[part 1 of 5: packages /MICROSAR/Dem_swc/DataTypes to /MICROSAR/Dem_swc/ComponentTypes]
AUTOSAR XML (schema 00048)
package /MICROSAR/Dem_swc/DataTypes
  27 x impl type:
    Dem_EventIdType: range raw 1..65535, implementation-data-type=uint16
    Dem_RatioIdType: range raw 1..65535, implementation-data-type=uint16
    Dem_DTCStatusMaskType: range raw 0..255, implementation-data-type=uint8
    Dem_OperationCycleIdType: range raw 0..255, implementation-data-type=uint8
    Dem_DTCGroupType: range raw 0..16777215, implementation-data-type=uint32
    Dem_EventStatusType:
      compu {0=DEM_EVENT_STATUS_PASSED, 1=DEM_EVENT_STATUS_FAILED, 2=DEM_EVENT_STATUS_PREPASSED, 3=DEM_EVENT_STATUS_PREFAILED, 4=DEM_EVENT_STATUS_FDC_THRESHOLD_REACHED, 5=DEM_EVENT_STATUS_PASSED_CONDITIONS_NOT_FULFILLED, 6=DEM_EVENT_STATUS_FAILED_CONDITIONS_NOT_FULFILLED, 7=DEM_EVENT_STATUS_PREPASSED_CONDITIONS_NOT_FULFILLED, 8=DEM_EVENT_STATUS_PREFAILED_CONDITIONS_NOT_FULFILLED}
      range raw 0..255
      implementation-data-type=uint8
    Dem_DTCKindType: compu {1=DEM_DTC_KIND_ALL_DTCS, 2=DEM_DTC_KIND_EMISSION_REL_DTCS}, range raw 0..255, implementation-data-type=uint8
    Dem_IumprDenomCondStatusType: compu {0=DEM_IUMPR_DEN_STATUS_NOT_REACHED, 1=DEM_IUMPR_DEN_STATUS_REACHED, 2=DEM_IUMPR_DEN_STATUS_INHIBITED}, range raw 0..255, implementation-data-type=uint8
    Dem_DebounceResetStatusType: compu {0=DEM_DEBOUNCE_STATUS_FREEZE, 1=DEM_DEBOUNCE_STATUS_RESET}, range raw 0..255, implementation-data-type=uint8
    Dem_DTRControlType: compu {0=DEM_DTR_CTL_NORMAL, 1=DEM_DTR_CTL_NO_MAX, 2=DEM_DTR_CTL_NO_MIN, 3=DEM_DTR_CTL_RESET, 4=DEM_DTR_CTL_INVISIBLE}, range raw 0..255, implementation-data-type=uint8
    Dem_DebouncingStateType:
      compu {mask 1: 1=DEM_TEMPORARILY_DEFECTIVE (Bit 0: Temporarily Defective (corresponds to 0 < FDC < 127)), mask 2: 2=DEM_FINALLY_DEFECTIVE (Bit 1: Finally Defective (corresponds to FDC = 127)), mask 4: 4=DEM_TEMPORARILY_HEALED (Bit 2: Temporarily healed (corresponds to -128 < FDC < 0)), mask 8: 8=DEM_TEST_COMPLETE (Bit 3: Test complete (corresponds to FDC = -128 or FDC = 127)), mask 16: 16=DEM_DTR_UPDATE (Bit 4: DTR Update (= Test complete && Debouncing complete && enable conditions / storage conditions fulfilled))}
      range raw 0..255
      implementation-data-type=uint8
    Dem_DTCSeverityType:
      compu {mask 255: 0=DEM_SEVERITY_NO_SEVERITY (DTC_NO_SEVERITY) (No severity information available), mask 31: 1=DEM_SEVERITY_WWHOBD_CLASS_NO_CLASS (DTC_CLASS) (No class information), mask 31: 2=DEM_SEVERITY_WWHOBD_CLASS_A (DTC_CLASS) (WWH-OBD Class A), mask 31: 4=DEM_SEVERITY_WWHOBD_CLASS_B1 (DTC_CLASS) (WWH-OBD Class B1), mask 31: 8=DEM_SEVERITY_WWHOBD_CLASS_B2 (DTC_CLASS) (WWH-OBD Class B2), mask 31: 16=DEM_SEVERITY_WWHOBD_CLASS_C (DTC_CLASS) (WWH-OBD Class C), mask 224: 32=DEM_SEVERITY_MAINTENANCE_ONLY (DTC_SEVERITY) (Maintenance required), mask 224: 64=DEM_SEVERITY_CHECK_AT_NEXT_HALT (DTC_SEVERITY) (Check at next halt), mask 224: 128=DEM_SEVERITY_CHECK_IMMEDIATELY (DTC_SEVERITY) (Check immediately)}
      range raw 0..255
      implementation-data-type=uint8
    Dem_UdsStatusByteType:
      compu {mask 1: 1=DEM_UDS_STATUS_TF (bit 0: TestFailed), mask 2: 2=DEM_UDS_STATUS_TFTOC (bit 1: TestFailedThisOperationCycle), mask 4: 4=DEM_UDS_STATUS_PDTC (bit 2: PendingDTC), mask 8: 8=DEM_UDS_STATUS_CDTC (bit 3: ConfirmedDTC), mask 16: 16=DEM_UDS_STATUS_TNCSLC (bit 4: TestNotCompletedSinceLastClear), mask 32: 32=DEM_UDS_STATUS_TFSLC (bit 5: TestFailedSinceLastClear), mask 64: 64=DEM_UDS_STATUS_TNCTOC (bit 6: TestNotCompletedThisOperationCycle), mask 128: 128=DEM_UDS_STATUS_WIR (bit 7: WarningIndicatorRequested)}
      range raw 0..255
      implementation-data-type=uint8
    Dem_MonitorStatusType: compu {mask 1: 1=DEM_MONITOR_STATUS_TF (bit 0: TestFailed), mask 2: 2=DEM_MONITOR_STATUS_TNCTOC (bit 1: TestNotCompletedThisOperationCycle)}, range raw 0..255, implementation-data-type=uint8
    DataArrayType_uint8_2: category=ARRAY, sw-calibration-access=READ-ONLY
      element DataArrayType_uint8_2Element: array-size=2, array-size-semantics=FIXED-SIZE, implementation-data-type=uint8
    Dem_IumprReadinessGroupType:
      compu {0=DEM_IUMPR_BOOSTPRS, 1=DEM_IUMPR_CAT1, 2=DEM_IUMPR_CAT2, 3=DEM_IUMPR_EGR, 4=DEM_IUMPR_EGSENSOR, 5=DEM_IUMPR_EVAP, 6=DEM_IUMPR_NMHCCAT, 7=DEM_IUMPR_NOXADSORB, 8=DEM_IUMPR_NOXCAT, 9=DEM_IUMPR_OXS1, 10=DEM_IUMPR_OXS2, 11=DEM_IUMPR_PMFILTER, 12=DEM_IUMPR_PRIVATE, 13=DEM_IUMPR_SAIR, 14=DEM_IUMPR_SECOXS1, 15=DEM_IUMPR_SECOXS2, 16=DEM_IUMPR_FLSYS, 17=DEM_IUMPR_AFRI1, 18=DEM_IUMPR_AFRI2, 19=DEM_IUMPR_PF1, 20=DEM_IUMPR_PF2, 255=DEM_IUMPR_ALLGROUPS}
      range raw 0..255
      implementation-data-type=uint8
    Dem_IumprDenomCondIdType: compu {1=DEM_IUMPR_GENERAL_DENOMINATOR, 2=DEM_IUMPR_DEN_COND_COLDSTART, 3=DEM_IUMPR_DEN_COND_EVAP, 4=DEM_IUMPR_DEN_COND_500MI, 5=DEM_IUMPR_GENERAL_INDIVIDUAL_DENOMINATOR, 6=DEM_IUMPR_GENERAL_OBDCOND, 7=DEM_IUMPR_DEN_COND_INDEPENDENT}, range raw 0..255, implementation-data-type=uint8
    Dem_InitMonitorReasonType: compu {1=DEM_INIT_MONITOR_CLEAR, 2=DEM_INIT_MONITOR_RESTART, 3=DEM_INIT_MONITOR_REENABLED, 4=DEM_INIT_MONITOR_STORAGE_REENABLED}, range raw 1..4, implementation-data-type=uint8
    Dem_DTCFormatType: compu {0=DEM_DTC_FORMAT_OBD, 1=DEM_DTC_FORMAT_UDS, 2=DEM_DTC_FORMAT_J1939}, range raw 0..2, implementation-data-type=uint8
    Dem_OperationCycleStateType: compu {0=DEM_CYCLE_STATE_START, 1=DEM_CYCLE_STATE_END}, range raw 0..1, implementation-data-type=uint8
    Dem_IndicatorStatusType: compu {0=DEM_INDICATOR_OFF, 1=DEM_INDICATOR_CONTINUOUS, 2=DEM_INDICATOR_BLINKING, 3=DEM_INDICATOR_BLINK_CONT, 4=DEM_INDICATOR_SLOW_FLASH, 5=DEM_INDICATOR_FAST_FLASH, 6=DEM_INDICATOR_ON_DEMAND, 7=DEM_INDICATOR_SHORT}, range raw 0..7, implementation-data-type=uint8
    Dem_DTCOriginType: compu {1=DEM_DTC_ORIGIN_PRIMARY_MEMORY, 2=DEM_DTC_ORIGIN_MIRROR_MEMORY, 3=DEM_DTC_ORIGIN_PERMANENT_MEMORY, 4=DEM_DTC_ORIGIN_OBD_RELEVANT_MEMORY, 256=DEM_DTC_ORIGIN_SECONDARY_MEMORY}, range raw 1..511, implementation-data-type=uint16
    Dem_MaxDataValueType: category=ARRAY, sw-calibration-access=READ-ONLY
      element Dem_MaxDataValueTypeElement: array-size=10, array-size-semantics=FIXED-SIZE, implementation-data-type=uint8
    DataPrimitiveType_uint8: implementation-data-type=uint8
    DataArrayType_uint8_3: category=ARRAY, sw-calibration-access=READ-ONLY
      element DataArrayType_uint8_3Element: array-size=3, array-size-semantics=FIXED-SIZE, implementation-data-type=uint8
    DataArrayType_uint8_1: category=ARRAY, sw-calibration-access=READ-ONLY
      element DataArrayType_uint8_1Element: array-size=1, array-size-semantics=FIXED-SIZE, implementation-data-type=uint8
    DataArrayType_uint8_5: category=ARRAY, sw-calibration-access=READ-ONLY
      element DataArrayType_uint8_5Element: array-size=5, array-size-semantics=FIXED-SIZE, implementation-data-type=uint8
package /MICROSAR/Dem_swc/Interfaces
  37 x client server interface, all with is-service=true, service-kind=DIAGNOSTIC-EVENT-MANAGER:
    DemServices
      operation GetPostRunRequested: possible-error=DemServices/E_NOT_OK
        arg IsRequested: type=boolean, direction=OUT
      operation GetDTCStatusAvailabilityMask: possible-error=DemServices/E_NOT_OK
        arg ClientId: type=uint8, direction=IN
        arg DTCStatusMask: type=uint8, direction=OUT
      error E_NOT_OK: error-code=1
    ClearDTC
      operation ClearDTC: possible-error=[ClearDTC/E_NOT_OK, DEM_CLEAR_FAILED, ClearDTC/DEM_PENDING, DEM_CLEAR_BUSY, DEM_CLEAR_MEMORY_ERROR, ClearDTC/DEM_WRONG_DTC, ClearDTC/DEM_WRONG_DTCORIGIN]
      operation SelectDTC: possible-error=[ClearDTC/E_OK, ClearDTC/E_NOT_OK]
        arg DTC: type=uint32, direction=IN
        arg DTCFormat: type=Dem_DTCFormatType, direction=IN
        arg DTCOrigin: type=Dem_DTCOriginType, direction=IN
      8 x error:
        E_OK: error-code=0
        E_NOT_OK: error-code=1
        DEM_CLEAR_FAILED: error-code=7
        DEM_PENDING: error-code=4
        DEM_CLEAR_BUSY: error-code=5
        DEM_CLEAR_MEMORY_ERROR: error-code=6
        DEM_WRONG_DTC: error-code=8
        DEM_WRONG_DTCORIGIN: error-code=9
    EvMemOverflowIndication
      operation GetEventMemoryOverflow: possible-error=EvMemOverflowIndication/E_NOT_OK
        arg OverflowIndication: type=boolean, direction=OUT
      operation GetNumberOfEventMemoryEntries: possible-error=EvMemOverflowIndication/E_NOT_OK
        arg NumberOfEventMemoryEntries: type=uint8, direction=OUT
      error E_NOT_OK: error-code=1
    GeneralDiagnosticInfo
      11 x operation:
        GetEventUdsStatus: possible-error=GeneralDiagnosticInfo/E_NOT_OK
          arg EventId: type=Dem_EventIdType, direction=IN
          arg UDSStatusByte: type=Dem_UdsStatusByteType, direction=OUT
        GetEventStatus: possible-error=GeneralDiagnosticInfo/E_NOT_OK
          arg EventId: type=Dem_EventIdType, direction=IN
          arg UDSStatusByte: type=Dem_UdsStatusByteType, direction=OUT
        GetEventFailed: possible-error=GeneralDiagnosticInfo/E_NOT_OK
          arg EventId: type=Dem_EventIdType, direction=IN
          arg EventFailed: type=boolean, direction=OUT
        GetEventTested: possible-error=GeneralDiagnosticInfo/E_NOT_OK
          arg EventId: type=Dem_EventIdType, direction=IN
          arg EventTested: type=boolean, direction=OUT
        GetDTCOfEvent: possible-error=[GeneralDiagnosticInfo/E_NOT_OK, GeneralDiagnosticInfo/DEM_E_NO_DTC_AVAILABLE]
          arg EventId: type=Dem_EventIdType, direction=IN
          arg DTCFormat: type=Dem_DTCFormatType, direction=IN
          arg DTCOfEvent: type=uint32, direction=OUT
        GetFaultDetectionCounter: possible-error=[GeneralDiagnosticInfo/E_NOT_OK, GeneralDiagnosticInfo/DEM_E_NO_FDC_AVAILABLE]
          arg EventId: type=Dem_EventIdType, direction=IN
          arg FaultDetectionCounter: type=sint8, direction=OUT
        GetEventFreezeFrameDataEx: possible-error=[GeneralDiagnosticInfo/E_NOT_OK, GeneralDiagnosticInfo/DEM_BUFFER_TOO_SMALL, GeneralDiagnosticInfo/DEM_NO_SUCH_ELEMENT]
          5 x arg:
            EventId: type=Dem_EventIdType, direction=IN
            RecordNumber: type=uint8, direction=IN
            DataId: type=uint16, direction=IN
            DestBuffer: type=Dem_MaxDataValueType, direction=OUT
            BufSize: type=uint16, direction=INOUT
        GetEventExtendedDataRecordEx: possible-error=[GeneralDiagnosticInfo/E_NOT_OK, GeneralDiagnosticInfo/DEM_BUFFER_TOO_SMALL, GeneralDiagnosticInfo/DEM_NO_SUCH_ELEMENT]
          4 x arg:
            EventId: type=Dem_EventIdType, direction=IN
            RecordNumber: type=uint8, direction=IN
            DestBuffer: type=Dem_MaxDataValueType, direction=OUT
            BufSize: type=uint16, direction=INOUT
        GetEventEnableCondition: possible-error=GeneralDiagnosticInfo/E_NOT_OK
          arg EventId: type=Dem_EventIdType, direction=IN
          arg ConditionFullfilled: type=boolean, direction=OUT
        GetDebouncingOfEvent: possible-error=GeneralDiagnosticInfo/E_NOT_OK
          arg EventId: type=Dem_EventIdType, direction=IN
          arg DebouncingState: type=Dem_DebouncingStateType, direction=OUT
        GetMonitorStatus: possible-error=GeneralDiagnosticInfo/E_NOT_OK
          arg EventId: type=Dem_EventIdType, direction=IN
          arg MonitorStatus: type=Dem_MonitorStatusType, direction=OUT
      5 x error:
        E_NOT_OK: error-code=1
        DEM_E_NO_DTC_AVAILABLE: error-code=10
        DEM_E_NO_FDC_AVAILABLE: error-code=14
        DEM_BUFFER_TOO_SMALL: error-code=21
        DEM_NO_SUCH_ELEMENT: error-code=48
    OperationCycle
      operation GetOperationCycleState: possible-error=[OperationCycle/E_OK, OperationCycle/E_NOT_OK]
        arg CycleState: type=Dem_OperationCycleStateType, direction=OUT
      operation SetOperationCycleState: possible-error=[OperationCycle/E_OK, OperationCycle/E_NOT_OK]
        arg CycleState: type=Dem_OperationCycleStateType, direction=IN
      error E_OK: error-code=0
      error E_NOT_OK: error-code=1
    DiagnosticInfo
      11 x operation:
        GetEventUdsStatus: possible-error=DiagnosticInfo/E_NOT_OK
          arg UDSStatusByte: type=Dem_UdsStatusByteType, direction=OUT
        GetEventStatus: possible-error=DiagnosticInfo/E_NOT_OK
          arg UDSStatusByte: type=Dem_UdsStatusByteType, direction=OUT
        GetEventFailed: possible-error=DiagnosticInfo/E_NOT_OK
          arg EventFailed: type=boolean, direction=OUT
        GetEventTested: possible-error=DiagnosticInfo/E_NOT_OK
          arg EventTested: type=boolean, direction=OUT
        GetDTCOfEvent: possible-error=[DiagnosticInfo/E_NOT_OK, DiagnosticInfo/DEM_E_NO_DTC_AVAILABLE]
          arg DTCFormat: type=Dem_DTCFormatType, direction=IN
          arg DTCOfEvent: type=uint32, direction=OUT
        GetFaultDetectionCounter: possible-error=[DiagnosticInfo/E_NOT_OK, DiagnosticInfo/DEM_E_NO_FDC_AVAILABLE]
          arg FaultDetectionCounter: type=sint8, direction=OUT
        GetEventFreezeFrameDataEx: possible-error=[DiagnosticInfo/E_NOT_OK, DiagnosticInfo/DEM_BUFFER_TOO_SMALL, DiagnosticInfo/DEM_NO_SUCH_ELEMENT]
          4 x arg:
            RecordNumber: type=uint8, direction=IN
            DataId: type=uint16, direction=IN
            DestBuffer: type=Dem_MaxDataValueType, direction=OUT
            BufSize: type=uint16, direction=INOUT
        GetEventExtendedDataRecordEx: possible-error=[DiagnosticInfo/E_NOT_OK, DiagnosticInfo/DEM_BUFFER_TOO_SMALL, DiagnosticInfo/DEM_NO_SUCH_ELEMENT]
          arg RecordNumber: type=uint8, direction=IN
          arg DestBuffer: type=Dem_MaxDataValueType, direction=OUT
          arg BufSize: type=uint16, direction=INOUT
        GetEventEnableCondition: possible-error=DiagnosticInfo/E_NOT_OK
          arg ConditionFullfilled: type=boolean, direction=OUT
        GetDebouncingOfEvent: possible-error=DiagnosticInfo/E_NOT_OK
          arg DebouncingState: type=Dem_DebouncingStateType, direction=OUT
        GetMonitorStatus: possible-error=DiagnosticInfo/E_NOT_OK
          arg MonitorStatus: type=Dem_MonitorStatusType, direction=OUT
      5 x error:
        E_NOT_OK: error-code=1
        DEM_E_NO_DTC_AVAILABLE: error-code=10
        DEM_E_NO_FDC_AVAILABLE: error-code=14
        DEM_BUFFER_TOO_SMALL: error-code=21
        DEM_NO_SUCH_ELEMENT: error-code=48
    DiagnosticMonitor
      11 x operation:
        SetEventStatus: possible-error=DiagnosticMonitor/E_NOT_OK
          arg EventStatus: type=Dem_EventStatusType, direction=IN
        ResetEventStatus: possible-error=DiagnosticMonitor/E_NOT_OK
        ResetEventDebounceStatus: possible-error=DiagnosticMonitor/E_NOT_OK
          arg DebounceResetStatus: type=Dem_DebounceResetStatusType, direction=IN
        GetEventUdsStatus: possible-error=DiagnosticMonitor/E_NOT_OK
          arg UDSStatusByte: type=Dem_UdsStatusByteType, direction=OUT
        GetEventStatus: possible-error=DiagnosticMonitor/E_NOT_OK
          arg UDSStatusByte: type=Dem_UdsStatusByteType, direction=OUT
        GetEventFailed: possible-error=DiagnosticMonitor/E_NOT_OK
          arg EventFailed: type=boolean, direction=OUT
        GetEventTested: possible-error=DiagnosticMonitor/E_NOT_OK
          arg EventTested: type=boolean, direction=OUT
        GetDTCOfEvent: possible-error=[DiagnosticMonitor/E_NOT_OK, DiagnosticMonitor/DEM_E_NO_DTC_AVAILABLE]
          arg DTCFormat: type=Dem_DTCFormatType, direction=IN
          arg DTCOfEvent: type=uint32, direction=OUT
        GetFaultDetectionCounter: possible-error=[DiagnosticMonitor/E_NOT_OK, DiagnosticMonitor/DEM_E_NO_FDC_AVAILABLE]
          arg FaultDetectionCounter: type=sint8, direction=OUT
        GetEventFreezeFrameDataEx: possible-error=[DiagnosticMonitor/E_NOT_OK, DiagnosticMonitor/DEM_BUFFER_TOO_SMALL, DiagnosticMonitor/DEM_NO_SUCH_ELEMENT]
          4 x arg:
            RecordNumber: type=uint8, direction=IN
            DataId: type=uint16, direction=IN
            DestBuffer: type=Dem_MaxDataValueType, direction=OUT
            BufSize: type=uint16, direction=INOUT
        GetEventExtendedDataRecordEx: possible-error=[DiagnosticMonitor/E_NOT_OK, DiagnosticMonitor/DEM_BUFFER_TOO_SMALL, DiagnosticMonitor/DEM_NO_SUCH_ELEMENT]
          arg RecordNumber: type=uint8, direction=IN
          arg DestBuffer: type=Dem_MaxDataValueType, direction=OUT
          arg BufSize: type=uint16, direction=INOUT
      5 x error:
        E_NOT_OK: error-code=1
        DEM_E_NO_DTC_AVAILABLE: error-code=10
        DEM_E_NO_FDC_AVAILABLE: error-code=14
        DEM_BUFFER_TOO_SMALL: error-code=21
        DEM_NO_SUCH_ELEMENT: error-code=48
    CSDataServices_DemDataElementClass_StartApplication
      operation ReadData: possible-error=CSDataServices_DemDataElementClass_StartApplication/E_NOT_OK
        arg Data: type=DataArrayType_uint8_2, direction=OUT
      error E_NOT_OK: error-code=1
    CallbackGetFaultDetectCounter
      operation GetFaultDetectionCounter: possible-error=CallbackGetFaultDetectCounter/E_NOT_OK
        arg FaultDetectionCounter: type=sint8, direction=OUT
      error E_NOT_OK: error-code=1
    CSDataServices_DID_0xF404_Calculate_Load_Value
      operation ReadData: possible-error=CSDataServices_DID_0xF404_Calculate_Load_Value/E_NOT_OK
        arg Data: type=DataPrimitiveType_uint8, direction=OUT
      error E_NOT_OK: error-code=1
    CSDataServices_DID_0xF405_Engine_Coolent_temperature
      operation ReadData: possible-error=CSDataServices_DID_0xF405_Engine_Coolent_temperature/E_NOT_OK
        arg Data: type=DataPrimitiveType_uint8, direction=OUT
      error E_NOT_OK: error-code=1
    CSDataServices_DID_0xF40C_Engine_RPM
      operation ReadData: possible-error=CSDataServices_DID_0xF40C_Engine_RPM/E_NOT_OK
        arg Data: type=DataPrimitiveType_uint8, direction=OUT
      error E_NOT_OK: error-code=1
    CSDataServices_DID_0xF41F_Time_Since_Engin_Start
      operation ReadData: possible-error=CSDataServices_DID_0xF41F_Time_Since_Engin_Start/E_NOT_OK
        arg Data: type=DataPrimitiveType_uint8, direction=OUT
      error E_NOT_OK: error-code=1
    CSDataServices_DID_0xF40D_Vehicle_Speed_Sensor
      operation ReadData: possible-error=CSDataServices_DID_0xF40D_Vehicle_Speed_Sensor/E_NOT_OK
        arg Data: type=DataPrimitiveType_uint8, direction=OUT
      error E_NOT_OK: error-code=1
    CSDataServices_DID_0xF442_Controle_Module_Voltage
      operation ReadData: possible-error=CSDataServices_DID_0xF442_Controle_Module_Voltage/E_NOT_OK
        arg Data: type=DataPrimitiveType_uint8, direction=OUT
      error E_NOT_OK: error-code=1
    CSDataServices_DID_0xF449_Accelerator_Pedal_Position_D
      operation ReadData: possible-error=CSDataServices_DID_0xF449_Accelerator_Pedal_Position_D/E_NOT_OK
        arg Data: type=DataPrimitiveType_uint8, direction=OUT
      error E_NOT_OK: error-code=1
    CSDataServices_EDC_Standard_DTC_Information
      operation ReadData: possible-error=CSDataServices_EDC_Standard_DTC_Information/E_NOT_OK
        arg Data: type=DataPrimitiveType_uint8, direction=OUT
      error E_NOT_OK: error-code=1
    CSDataServices_EDC_Standard_Freeze_Frame
      operation ReadData: possible-error=CSDataServices_EDC_Standard_Freeze_Frame/E_NOT_OK
        arg Data: type=DataPrimitiveType_uint8, direction=OUT
      error E_NOT_OK: error-code=1
    CSDataServices_EDC_Monitor_Activity_numerator_Counts
      operation ReadData: possible-error=CSDataServices_EDC_Monitor_Activity_numerator_Counts/E_NOT_OK
        arg Data: type=DataPrimitiveType_uint8, direction=OUT
      error E_NOT_OK: error-code=1
    CSDataServices_EDC_Stored_Monitor_Activity_Ratio
      operation ReadData: possible-error=CSDataServices_EDC_Stored_Monitor_Activity_Ratio/E_NOT_OK
        arg Data: type=DataPrimitiveType_uint8, direction=OUT
      error E_NOT_OK: error-code=1
    CSDataServices_Data_StandardFreezeFrame1_Param_KmMilea_1
      operation ReadData: possible-error=CSDataServices_Data_StandardFreezeFrame1_Param_KmMilea_1/E_NOT_OK
        arg Data: type=DataArrayType_uint8_3, direction=OUT
      error E_NOT_OK: error-code=1
    CSDataServices_Data_PID_0xd_Param_VehicSpeedSenso
      operation ReadData: possible-error=CSDataServices_Data_PID_0xd_Param_VehicSpeedSenso/E_NOT_OK
        arg Data: type=DataArrayType_uint8_1, direction=OUT
      error E_NOT_OK: error-code=1
    CSDataServices_Data_PID_0x42_Param_ContrModulVolta
      operation ReadData: possible-error=CSDataServices_Data_PID_0x42_Param_ContrModulVolta/E_NOT_OK
        arg Data: type=DataArrayType_uint8_2, direction=OUT
      error E_NOT_OK: error-code=1
    CSDataServices_Data_PID_0xc_Param_EnginRPM
      operation ReadData: possible-error=CSDataServices_Data_PID_0xc_Param_EnginRPM/E_NOT_OK
        arg Data: type=DataArrayType_uint8_2, direction=OUT
      error E_NOT_OK: error-code=1
    CSDataServices_Data_PID_0x1f_Param_TimeSinceEnginStart
      operation ReadData: possible-error=CSDataServices_Data_PID_0x1f_Param_TimeSinceEnginStart/E_NOT_OK
        arg Data: type=DataArrayType_uint8_2, direction=OUT
      error E_NOT_OK: error-code=1
    CSDataServices_Data_SupplementalMonitorActivityData_Param_StoreMonitActivRatio
      operation ReadData: possible-error=CSDataServices_Data_SupplementalMonitorActivityData_Param_StoreMonitActivRatio/E_NOT_OK
        arg Data: type=DataPrimitiveType_uint8, direction=OUT
      error E_NOT_OK: error-code=1
    CSDataServices_Data_PID_0x49_Param_AccelPedalPositD
      operation ReadData: possible-error=CSDataServices_Data_PID_0x49_Param_AccelPedalPositD/E_NOT_OK
        arg Data: type=DataArrayType_uint8_1, direction=OUT
      error E_NOT_OK: error-code=1
    CSDataServices_Data_PID_0x4_Param_CalcuLOADValue
      operation ReadData: possible-error=CSDataServices_Data_PID_0x4_Param_CalcuLOADValue/E_NOT_OK
        arg Data: type=DataArrayType_uint8_1, direction=OUT
      error E_NOT_OK: error-code=1
    CSDataServices_Data_PID_0x5_Param_EnginCoolaTempe
      operation ReadData: possible-error=CSDataServices_Data_PID_0x5_Param_EnginCoolaTempe/E_NOT_OK
        arg Data: type=DataArrayType_uint8_1, direction=OUT
      error E_NOT_OK: error-code=1
    CSDataServices_Data_StandardFreezeFrame1_Param_TimeStamp_STRUC_Bitfi
      operation ReadData: possible-error=CSDataServices_Data_StandardFreezeFrame1_Param_TimeStamp_STRUC_Bitfi/E_NOT_OK
        arg Data: type=DataArrayType_uint8_5, direction=OUT
      error E_NOT_OK: error-code=1
    CSDataServices_Data_StandardFreezeFrame1_Param_AgingCount
      operation ReadData: possible-error=CSDataServices_Data_StandardFreezeFrame1_Param_AgingCount/E_NOT_OK
        arg Data: type=DataPrimitiveType_uint8, direction=OUT
      error E_NOT_OK: error-code=1
    CSDataServices_Data_StandardDTCInformation_Param_DTCPrior
      operation ReadData: possible-error=CSDataServices_Data_StandardDTCInformation_Param_DTCPrior/E_NOT_OK
        arg Data: type=DataPrimitiveType_uint8, direction=OUT
      error E_NOT_OK: error-code=1
    CSDataServices_Data_SupplementalMonitorActivityData_Param_MonitActivNumerCount
      operation ReadData: possible-error=CSDataServices_Data_SupplementalMonitorActivityData_Param_MonitActivNumerCount/E_NOT_OK
        arg Data: type=DataPrimitiveType_uint8, direction=OUT
      error E_NOT_OK: error-code=1
    CSDataServices_Data_StandardFreezeFrame1_Param_Reser
      operation ReadData: possible-error=CSDataServices_Data_StandardFreezeFrame1_Param_Reser/E_NOT_OK
        arg Data: type=DataPrimitiveType_uint8, direction=OUT
      error E_NOT_OK: error-code=1
    CSDataServices_Data_Vishnu_ExtData_Param_VishnDOB
      operation ReadData: possible-error=CSDataServices_Data_Vishnu_ExtData_Param_VishnDOB/E_NOT_OK
        arg EventId: type=Dem_EventIdType, direction=IN
        arg Data: type=DataPrimitiveType_uint8, direction=OUT
      error E_NOT_OK: error-code=1
    CSDataServices_Data_Vishnu_ExtData_Param_VishnRes
      operation ReadData: possible-error=CSDataServices_Data_Vishnu_ExtData_Param_VishnRes/E_NOT_OK
        arg Data: type=DataPrimitiveType_uint8, direction=OUT
      error E_NOT_OK: error-code=1
    DTCSuppression
      operation SetDTCSuppression: possible-error=[DTCSuppression/E_NOT_OK, DTCSuppression/DEM_WRONG_DTC, DTCSuppression/DEM_WRONG_DTCORIGIN, DTCSuppression/DEM_PENDING]
        arg SuppressionStatus: type=boolean, direction=IN
      operation GetDTCSuppression: possible-error=[DTCSuppression/E_NOT_OK, DTCSuppression/DEM_WRONG_DTC, DTCSuppression/DEM_WRONG_DTCORIGIN, DTCSuppression/DEM_PENDING]
        arg SuppressionStatus: type=boolean, direction=OUT
      4 x error:
        E_NOT_OK: error-code=1
        DEM_WRONG_DTC: error-code=8
        DEM_WRONG_DTCORIGIN: error-code=9
        DEM_PENDING: error-code=4
package /MICROSAR/Dem_swc/ComponentTypes
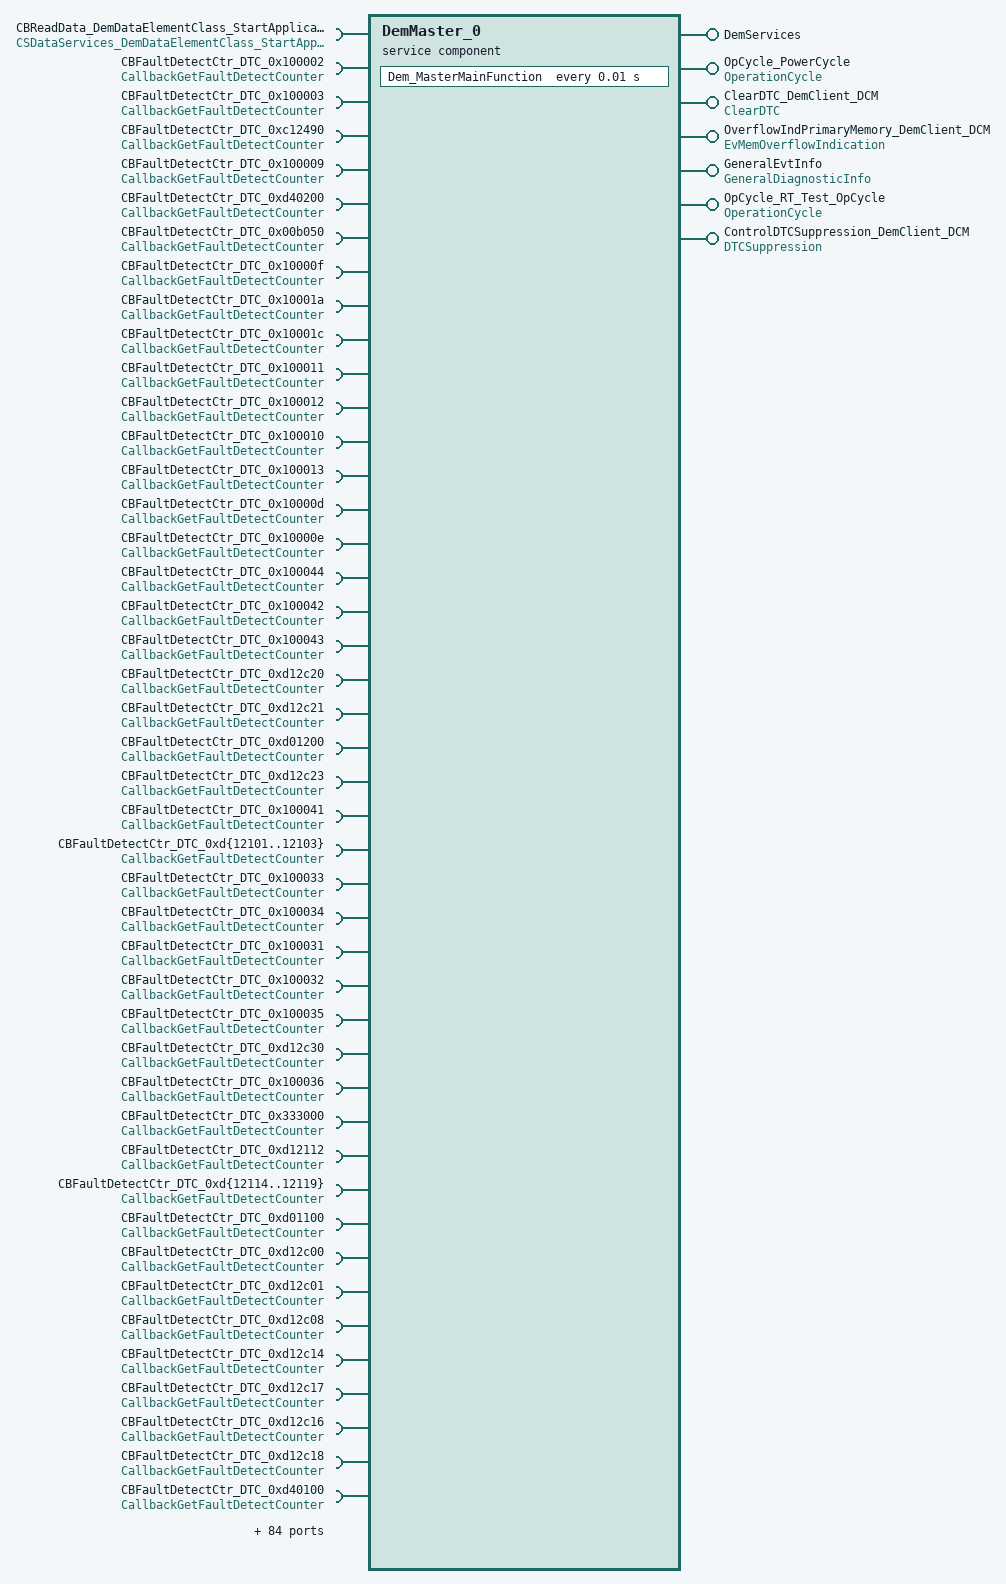
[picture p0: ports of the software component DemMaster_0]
  service sw component type DemMaster_0: category=SERVICE_COMPONENT
    provide port DemServices: provided-interface=DemServices
    provide port OpCycle_PowerCycle: provided-interface=OperationCycle
    require port CBReadData_DemDataElementClass_StartApplication: required-interface=CSDataServices_DemDataElementClass_StartApplication
    provide port ClearDTC_DemClient_DCM: provided-interface=ClearDTC
    provide port OverflowIndPrimaryMemory_DemClient_DCM: provided-interface=EvMemOverflowIndication
    provide port GeneralEvtInfo: provided-interface=GeneralDiagnosticInfo
    135 x require port:
      CBFaultDetectCtr_DTC_0x100002: required-interface=CallbackGetFaultDetectCounter
      CBFaultDetectCtr_DTC_0x100003: required-interface=CallbackGetFaultDetectCounter
      CBFaultDetectCtr_DTC_0xc12490: required-interface=CallbackGetFaultDetectCounter
      CBFaultDetectCtr_DTC_0x100009: required-interface=CallbackGetFaultDetectCounter
      CBFaultDetectCtr_DTC_0xd40200: required-interface=CallbackGetFaultDetectCounter
      CBFaultDetectCtr_DTC_0x00b050: required-interface=CallbackGetFaultDetectCounter
      CBFaultDetectCtr_DTC_0x10000f: required-interface=CallbackGetFaultDetectCounter
      CBFaultDetectCtr_DTC_0x10001a: required-interface=CallbackGetFaultDetectCounter
      CBFaultDetectCtr_DTC_0x10001c: required-interface=CallbackGetFaultDetectCounter
      CBFaultDetectCtr_DTC_0x100011: required-interface=CallbackGetFaultDetectCounter
      CBFaultDetectCtr_DTC_0x100012: required-interface=CallbackGetFaultDetectCounter
      CBFaultDetectCtr_DTC_0x100010: required-interface=CallbackGetFaultDetectCounter
      CBFaultDetectCtr_DTC_0x100013: required-interface=CallbackGetFaultDetectCounter
      CBFaultDetectCtr_DTC_0x10000d: required-interface=CallbackGetFaultDetectCounter
      CBFaultDetectCtr_DTC_0x10000e: required-interface=CallbackGetFaultDetectCounter
      CBFaultDetectCtr_DTC_0x100044: required-interface=CallbackGetFaultDetectCounter
      CBFaultDetectCtr_DTC_0x100042: required-interface=CallbackGetFaultDetectCounter
      CBFaultDetectCtr_DTC_0x100043: required-interface=CallbackGetFaultDetectCounter
      CBFaultDetectCtr_DTC_0xd12c20: required-interface=CallbackGetFaultDetectCounter
      CBFaultDetectCtr_DTC_0xd12c21: required-interface=CallbackGetFaultDetectCounter
      CBFaultDetectCtr_DTC_0xd01200: required-interface=CallbackGetFaultDetectCounter
      CBFaultDetectCtr_DTC_0xd12c23: required-interface=CallbackGetFaultDetectCounter
      CBFaultDetectCtr_DTC_0x100041: required-interface=CallbackGetFaultDetectCounter
      CBFaultDetectCtr_DTC_0xd{12101..12103}: required-interface=CallbackGetFaultDetectCounter
      CBFaultDetectCtr_DTC_0x100033: required-interface=CallbackGetFaultDetectCounter
      CBFaultDetectCtr_DTC_0x100034: required-interface=CallbackGetFaultDetectCounter
      CBFaultDetectCtr_DTC_0x100031: required-interface=CallbackGetFaultDetectCounter
      CBFaultDetectCtr_DTC_0x100032: required-interface=CallbackGetFaultDetectCounter
      CBFaultDetectCtr_DTC_0x100035: required-interface=CallbackGetFaultDetectCounter
      CBFaultDetectCtr_DTC_0xd12c30: required-interface=CallbackGetFaultDetectCounter
      CBFaultDetectCtr_DTC_0x100036: required-interface=CallbackGetFaultDetectCounter
      CBFaultDetectCtr_DTC_0x333000: required-interface=CallbackGetFaultDetectCounter
      CBFaultDetectCtr_DTC_0xd12112: required-interface=CallbackGetFaultDetectCounter
      CBFaultDetectCtr_DTC_0xd{12114..12119}: required-interface=CallbackGetFaultDetectCounter
      CBFaultDetectCtr_DTC_0xd01100: required-interface=CallbackGetFaultDetectCounter
      CBFaultDetectCtr_DTC_0xd12c00: required-interface=CallbackGetFaultDetectCounter
      CBFaultDetectCtr_DTC_0xd12c01: required-interface=CallbackGetFaultDetectCounter
      CBFaultDetectCtr_DTC_0xd12c08: required-interface=CallbackGetFaultDetectCounter
      CBFaultDetectCtr_DTC_0xd12c14: required-interface=CallbackGetFaultDetectCounter
      CBFaultDetectCtr_DTC_0xd12c17: required-interface=CallbackGetFaultDetectCounter
      CBFaultDetectCtr_DTC_0xd12c16: required-interface=CallbackGetFaultDetectCounter
      CBFaultDetectCtr_DTC_0xd12c18: required-interface=CallbackGetFaultDetectCounter
      CBFaultDetectCtr_DTC_0xd40100: required-interface=CallbackGetFaultDetectCounter
      CBFaultDetectCtr_DTC_0x000080: required-interface=CallbackGetFaultDetectCounter
      CBFaultDetectCtr_DTC_0xd12025: required-interface=CallbackGetFaultDetectCounter
      CBFaultDetectCtr_DTC_0xd12026: required-interface=CallbackGetFaultDetectCounter
      CBFaultDetectCtr_DTC_0x120022: required-interface=CallbackGetFaultDetectCounter
      CBFaultDetectCtr_DTC_0x120020: required-interface=CallbackGetFaultDetectCounter
      CBFaultDetectCtr_DTC_0x170400: required-interface=CallbackGetFaultDetectCounter
      CBFaultDetectCtr_DTC_0xd12159: required-interface=CallbackGetFaultDetectCounter
      CBFaultDetectCtr_DTC_0x00a009: required-interface=CallbackGetFaultDetectCounter
      CBFaultDetectCtr_DTC_0xd1210b: required-interface=CallbackGetFaultDetectCounter
      CBFaultDetectCtr_DTC_0xd1210c: required-interface=CallbackGetFaultDetectCounter
      CBFaultDetectCtr_DTC_0xd1210d: required-interface=CallbackGetFaultDetectCounter
      CBFaultDetectCtr_DTC_0xd1210e: required-interface=CallbackGetFaultDetectCounter
      CBFaultDetectCtr_DTC_0xd1210f: required-interface=CallbackGetFaultDetectCounter
      CBFaultDetectCtr_DTC_0xd{12000..12002}: required-interface=CallbackGetFaultDetectCounter
      CBFaultDetectCtr_DTC_0xd12004: required-interface=CallbackGetFaultDetectCounter
      CBFaultDetectCtr_DTC_0xe40004: required-interface=CallbackGetFaultDetectCounter
      CBFaultDetectCtr_DTC_0xe40005: required-interface=CallbackGetFaultDetectCounter
      CBFaultDetectCtr_DTC_0xe40002: required-interface=CallbackGetFaultDetectCounter
      CBFaultDetectCtr_DTC_0xe40003: required-interface=CallbackGetFaultDetectCounter
      CBFaultDetectCtr_DTC_0xe40001: required-interface=CallbackGetFaultDetectCounter
      CBFaultDetectCtr_DTC_0xd1211d: required-interface=CallbackGetFaultDetectCounter
      CBFaultDetectCtr_DTC_0xd12011: required-interface=CallbackGetFaultDetectCounter
      CBFaultDetectCtr_DTC_0xe40013: required-interface=CallbackGetFaultDetectCounter
      CBFaultDetectCtr_DTC_0xd13b51: required-interface=CallbackGetFaultDetectCounter
      CBFaultDetectCtr_DTC_0xd13b50: required-interface=CallbackGetFaultDetectCounter
      CBFaultDetectCtr_DTC_0xe40011: required-interface=CallbackGetFaultDetectCounter
      CBFaultDetectCtr_DTC_0xe40012: required-interface=CallbackGetFaultDetectCounter
      CBFaultDetectCtr_DTC_0x100203: required-interface=CallbackGetFaultDetectCounter
      CBFaultDetectCtr_DTC_0xe40010: required-interface=CallbackGetFaultDetectCounter
      CBFaultDetectCtr_DTC_0x12cb03: required-interface=CallbackGetFaultDetectCounter
      CBFaultDetectCtr_DTC_0x12cb04: required-interface=CallbackGetFaultDetectCounter
      CBFaultDetectCtr_DTC_0x12cb01: required-interface=CallbackGetFaultDetectCounter
      CBFaultDetectCtr_DTC_0x12cb02: required-interface=CallbackGetFaultDetectCounter
      CBFaultDetectCtr_DTC_0xe40008: required-interface=CallbackGetFaultDetectCounter
      CBFaultDetectCtr_DTC_0xe40009: required-interface=CallbackGetFaultDetectCounter
      CBFaultDetectCtr_DTC_0xe40006: required-interface=CallbackGetFaultDetectCounter
      CBFaultDetectCtr_DTC_0xe40007: required-interface=CallbackGetFaultDetectCounter
      CBFaultDetectCtr_DTC_0xd10301: required-interface=CallbackGetFaultDetectCounter
      CBFaultDetectCtr_DTC_0xd10300: required-interface=CallbackGetFaultDetectCounter
      CBFaultDetectCtr_DTC_0x170600: required-interface=CallbackGetFaultDetectCounter
      CBFaultDetectCtr_DTC_0x000016: required-interface=CallbackGetFaultDetectCounter
      CBFaultDetectCtr_DTC_0x000018: required-interface=CallbackGetFaultDetectCounter
      CBFaultDetectCtr_DTC_0xd1311d: required-interface=CallbackGetFaultDetectCounter
      CBFaultDetectCtr_DTC_0xd1311f: required-interface=CallbackGetFaultDetectCounter
      CBFaultDetectCtr_DTC_0xd12160: required-interface=CallbackGetFaultDetectCounter
      CBFaultDetectCtr_DTC_0xd12161: required-interface=CallbackGetFaultDetectCounter
      CBFaultDetectCtr_DTC_0x170612: required-interface=CallbackGetFaultDetectCounter
      CBFaultDetectCtr_DTC_0x000012: required-interface=CallbackGetFaultDetectCounter
      CBFaultDetectCtr_DTC_0x170610: required-interface=CallbackGetFaultDetectCounter
      CBFaultDetectCtr_DTC_0x000015: required-interface=CallbackGetFaultDetectCounter
      CBFaultDetectCtr_DTC_0x170611: required-interface=CallbackGetFaultDetectCounter
      CBFaultDetectCtr_DTC_0xd13026: required-interface=CallbackGetFaultDetectCounter
      CBFaultDetectCtr_DTC_0x170500: required-interface=CallbackGetFaultDetectCounter
      CBReadData_DID_0xF404_Calculate_Load_Value: required-interface=CSDataServices_DID_0xF404_Calculate_Load_Value
      CBReadData_DID_0xF405_Engine_Coolent_temperature: required-interface=CSDataServices_DID_0xF405_Engine_Coolent_temperature
      CBReadData_DID_0xF40C_Engine_RPM: required-interface=CSDataServices_DID_0xF40C_Engine_RPM
      CBReadData_DID_0xF41F_Time_Since_Engin_Start: required-interface=CSDataServices_DID_0xF41F_Time_Since_Engin_Start
      CBReadData_DID_0xF40D_Vehicle_Speed_Sensor: required-interface=CSDataServices_DID_0xF40D_Vehicle_Speed_Sensor
      CBReadData_DID_0xF442_Controle_Module_Voltage: required-interface=CSDataServices_DID_0xF442_Controle_Module_Voltage
      CBReadData_DID_0xF449_Accelerator_Pedal_Position_D: required-interface=CSDataServices_DID_0xF449_Accelerator_Pedal_Position_D
      CBReadData_EDC_Standard_DTC_Information: required-interface=CSDataServices_EDC_Standard_DTC_Information
      CBReadData_EDC_Standard_Freeze_Frame: required-interface=CSDataServices_EDC_Standard_Freeze_Frame
      CBReadData_EDC_Monitor_Activity_numerator_Counts: required-interface=CSDataServices_EDC_Monitor_Activity_numerator_Counts
      CBReadData_EDC_Stored_Monitor_Activity_Ratio: required-interface=CSDataServices_EDC_Stored_Monitor_Activity_Ratio
      CBFaultDetectCtr_DTC_0x184c00: required-interface=CallbackGetFaultDetectCounter
      CBFaultDetectCtr_DTC_0x1d5af0: required-interface=CallbackGetFaultDetectCounter
      CBReadData_Data_StandardFreezeFrame1_Param_KmMilea_1: required-interface=CSDataServices_Data_StandardFreezeFrame1_Param_KmMilea_1
      CBReadData_Data_PID_0xd_Param_VehicSpeedSenso: required-interface=CSDataServices_Data_PID_0xd_Param_VehicSpeedSenso
      CBReadData_Data_PID_0x42_Param_ContrModulVolta: required-interface=CSDataServices_Data_PID_0x42_Param_ContrModulVolta
      CBReadData_Data_PID_0xc_Param_EnginRPM: required-interface=CSDataServices_Data_PID_0xc_Param_EnginRPM
      CBReadData_Data_PID_0x1f_Param_TimeSinceEnginStart: required-interface=CSDataServices_Data_PID_0x1f_Param_TimeSinceEnginStart
      CBReadData_Data_SupplementalMonitorActivityData_Param_StoreMonitActivRatio: required-interface=CSDataServices_Data_SupplementalMonitorActivityData_Param_StoreMonitActivRatio
      CBReadData_Data_PID_0x49_Param_AccelPedalPositD: required-interface=CSDataServices_Data_PID_0x49_Param_AccelPedalPositD
      CBReadData_Data_PID_0x4_Param_CalcuLOADValue: required-interface=CSDataServices_Data_PID_0x4_Param_CalcuLOADValue
      CBReadData_Data_PID_0x5_Param_EnginCoolaTempe: required-interface=CSDataServices_Data_PID_0x5_Param_EnginCoolaTempe
      CBReadData_Data_StandardFreezeFrame1_Param_TimeStamp_STRUC_Bitfi: required-interface=CSDataServices_Data_StandardFreezeFrame1_Param_TimeStamp_STRUC_Bitfi
      CBReadData_Data_StandardFreezeFrame1_Param_AgingCount: required-interface=CSDataServices_Data_StandardFreezeFrame1_Param_AgingCount
      CBReadData_Data_StandardDTCInformation_Param_DTCPrior: required-interface=CSDataServices_Data_StandardDTCInformation_Param_DTCPrior
      CBReadData_Data_SupplementalMonitorActivityData_Param_MonitActivNumerCount: required-interface=CSDataServices_Data_SupplementalMonitorActivityData_Param_MonitActivNumerCount
      CBReadData_Data_StandardFreezeFrame1_Param_Reser: required-interface=CSDataServices_Data_StandardFreezeFrame1_Param_Reser
      CBFaultDetectCtr_DTC_0x100000: required-interface=CallbackGetFaultDetectCounter
      CBReadData_Data_Vishnu_ExtData_Param_VishnDOB: required-interface=CSDataServices_Data_Vishnu_ExtData_Param_VishnDOB
      CBReadData_Data_Vishnu_ExtData_Param_VishnRes: required-interface=CSDataServices_Data_Vishnu_ExtData_Param_VishnRes
    provide port OpCycle_RT_Test_OpCycle: provided-interface=OperationCycle
    require port CBFaultDetectCtr_DTC_0xe40000: required-interface=CallbackGetFaultDetectCounter
    provide port ControlDTCSuppression_DemClient_DCM: provided-interface=DTCSuppression
    behavior DemMaster_0InternalBehavior: handle-termination-and-restart=NO-SUPPORT, included-data-type-set=data-type=[Dem_EventIdType, Dem_RatioIdType, Dem_EventStatusType, Dem_UdsStatusByteType, Dem_DTCFormatType, Dem_InitMonitorReasonType, Dem_OperationCycleStateType, Dem_DTCStatusMaskType, Dem_IndicatorStatusType, Dem_MaxDataValueType, Dem_DTCKindType, Dem_DTCGroupType, Dem_IumprDenomCondIdType, Dem_IumprDenomCondStatusType, Dem_DebounceResetStatusType, Dem_DebouncingStateType, Dem_IumprReadinessGroupType, Dem_DTRControlType, Dem_DTCSeverityType, Dem_MonitorStatusType]
      timing event Timer_Dem_MasterMainFunction: start-on-event=Dem_MasterMainFunction, period=0.01
      23 x operation invoked event:
        OpEventPostRunRequested_GetPostRunRequested_DemServices: start-on-event=PostRunRequested, operation=DemServices.GetPostRunRequested
        OpEventGetDTCStatusAvailabilityMask_GetDTCStatusAvailabilityMask_DemServices: start-on-event=GetDTCStatusAvailabilityMask, operation=DemServices.GetDTCStatusAvailabilityMask
        OpEventGetOperationCycleState_GetOperationCycleState_OpCycle_PowerCycle: start-on-event=GetOperationCycleState, operation=OpCycle_PowerCycle.GetOperationCycleState
        OpEventSetOperationCycleState_SetOperationCycleState_OpCycle_PowerCycle: start-on-event=SetOperationCycleState, operation=OpCycle_PowerCycle.SetOperationCycleState
        OpEventClearDTC_ClearDTC_ClearDTC_DemClient_DCM: start-on-event=ClearDTC, operation=ClearDTC_DemClient_DCM.ClearDTC
        OpEventSelectDTC_SelectDTC_ClearDTC_DemClient_DCM: start-on-event=SelectDTC, operation=ClearDTC_DemClient_DCM.SelectDTC
        OpEventGetEventMemoryOverflow_GetEventMemoryOverflow_OverflowIndPrimaryMemory_DemClient_DCM: start-on-event=GetEventMemoryOverflow, operation=OverflowIndPrimaryMemory_DemClient_DCM.GetEventMemoryOverflow
        OpEventGetNumberOfEventMemoryEntries_GetNumberOfEventMemoryEntries_OverflowIndPrimaryMemory_DemClient_DCM: start-on-event=GetNumberOfEventMemoryEntries, operation=OverflowIndPrimaryMemory_DemClient_DCM.GetNumberOfEventMemoryEntries
        OpEventGetEventUdsStatus_GetEventUdsStatus_GeneralEvtInfo: start-on-event=DemMaster_0InternalBehavior/GetEventUdsStatus, operation=GeneralEvtInfo.GetEventUdsStatus
        OpEventGetEventStatus_GetEventStatus_GeneralEvtInfo: start-on-event=DemMaster_0InternalBehavior/GetEventStatus, operation=GeneralEvtInfo.GetEventStatus
        OpEventGetEventFailed_GetEventFailed_GeneralEvtInfo: start-on-event=DemMaster_0InternalBehavior/GetEventFailed, operation=GeneralEvtInfo.GetEventFailed
        OpEventGetEventTested_GetEventTested_GeneralEvtInfo: start-on-event=DemMaster_0InternalBehavior/GetEventTested, operation=GeneralEvtInfo.GetEventTested
        OpEventGetDTCOfEvent_GetDTCOfEvent_GeneralEvtInfo: start-on-event=DemMaster_0InternalBehavior/GetDTCOfEvent, operation=GeneralEvtInfo.GetDTCOfEvent
        OpEventGetFaultDetectionCounter_GetFaultDetectionCounter_GeneralEvtInfo: start-on-event=DemMaster_0InternalBehavior/GetFaultDetectionCounter, operation=GeneralEvtInfo.GetFaultDetectionCounter
        OpEventGetEventFreezeFrameDataEx_GetEventFreezeFrameDataEx_GeneralEvtInfo: start-on-event=DemMaster_0InternalBehavior/GetEventFreezeFrameDataEx, operation=GeneralEvtInfo.GetEventFreezeFrameDataEx
        OpEventGetEventExtendedDataRecordEx_GetEventExtendedDataRecordEx_GeneralEvtInfo: start-on-event=DemMaster_0InternalBehavior/GetEventExtendedDataRecordEx, operation=GeneralEvtInfo.GetEventExtendedDataRecordEx
        OpEventGetEventEnableCondition_GetEventEnableCondition_GeneralEvtInfo: start-on-event=DemMaster_0InternalBehavior/GetEventEnableCondition, operation=GeneralEvtInfo.GetEventEnableCondition
        OpEventGetDebouncingOfEvent_GetDebouncingOfEvent_GeneralEvtInfo: start-on-event=DemMaster_0InternalBehavior/GetDebouncingOfEvent, operation=GeneralEvtInfo.GetDebouncingOfEvent
        OpEventGetMonitorStatus_GetMonitorStatus_GeneralEvtInfo: start-on-event=DemMaster_0InternalBehavior/GetMonitorStatus, operation=GeneralEvtInfo.GetMonitorStatus
        OpEventGetOperationCycleState_GetOperationCycleState_OpCycle_RT_Test_OpCycle: start-on-event=GetOperationCycleState, operation=OpCycle_RT_Test_OpCycle.GetOperationCycleState
        OpEventSetOperationCycleState_SetOperationCycleState_OpCycle_RT_Test_OpCycle: start-on-event=SetOperationCycleState, operation=OpCycle_RT_Test_OpCycle.SetOperationCycleState
        OpEventSetDTCSuppression_SetDTCSuppression_ControlDTCSuppression_DemClient_DCM: start-on-event=SetDTCSuppression, operation=ControlDTCSuppression_DemClient_DCM.SetDTCSuppression
        OpEventGetDTCSuppression_GetDTCSuppression_ControlDTCSuppression_DemClient_DCM: start-on-event=GetDTCSuppression, operation=ControlDTCSuppression_DemClient_DCM.GetDTCSuppression
      port-api-options:
        enable-take-address=true, indirect-api=false, port=DemServices
        {enable-take-address=true, indirect-api=false, port-defined-argument-value{value=0, value-type=uint8}, port=ClearDTC_DemClient_DCM}
        enable-take-address=true, indirect-api=false, port=DemMaster_0/GeneralEvtInfo
        enable-take-address=true, indirect-api=false, port=DemMaster_0/CBReadData_DemDataElementClass_StartApplication
        {enable-take-address=true, indirect-api=false, port-arg-values=[{value=0, value-type=uint8}, {value=1, value-type=Dem_DTCOriginType}], port=OverflowIndPrimaryMemory_DemClient_DCM}
        enable-take-address=true, indirect-api=false, port=CBFaultDetectCtr_DTC_0x100002
        enable-take-address=true, indirect-api=false, port=CBFaultDetectCtr_DTC_0x100003
        enable-take-address=true, indirect-api=false, port=CBFaultDetectCtr_DTC_0xc12490
        enable-take-address=true, indirect-api=false, port=CBFaultDetectCtr_DTC_0x100009
        enable-take-address=true, indirect-api=false, port=CBFaultDetectCtr_DTC_0xd40200
        enable-take-address=true, indirect-api=false, port=CBFaultDetectCtr_DTC_0x00b050
        enable-take-address=true, indirect-api=false, port=CBFaultDetectCtr_DTC_0x10000f
        enable-take-address=true, indirect-api=false, port=CBFaultDetectCtr_DTC_0x10001a
        enable-take-address=true, indirect-api=false, port=CBFaultDetectCtr_DTC_0x10001c
        enable-take-address=true, indirect-api=false, port=CBFaultDetectCtr_DTC_0x100011
        enable-take-address=true, indirect-api=false, port=CBFaultDetectCtr_DTC_0x100012
        enable-take-address=true, indirect-api=false, port=CBFaultDetectCtr_DTC_0x100010
        enable-take-address=true, indirect-api=false, port=CBFaultDetectCtr_DTC_0x100013
        enable-take-address=true, indirect-api=false, port=CBFaultDetectCtr_DTC_0x10000d
        enable-take-address=true, indirect-api=false, port=CBFaultDetectCtr_DTC_0x10000e
        enable-take-address=true, indirect-api=false, port=CBFaultDetectCtr_DTC_0x100044
        enable-take-address=true, indirect-api=false, port=CBFaultDetectCtr_DTC_0x100042
        enable-take-address=true, indirect-api=false, port=CBFaultDetectCtr_DTC_0x100043
        enable-take-address=true, indirect-api=false, port=CBFaultDetectCtr_DTC_0xd12c20
        enable-take-address=true, indirect-api=false, port=CBFaultDetectCtr_DTC_0xd12c21
        enable-take-address=true, indirect-api=false, port=CBFaultDetectCtr_DTC_0xd01200
        enable-take-address=true, indirect-api=false, port=CBFaultDetectCtr_DTC_0xd12c23
        enable-take-address=true, indirect-api=false, port=CBFaultDetectCtr_DTC_0x100041
        enable-take-address=true, indirect-api=false, port=CBFaultDetectCtr_DTC_0xd{12101..12103}
        enable-take-address=true, indirect-api=false, port=CBFaultDetectCtr_DTC_0x100033
        enable-take-address=true, indirect-api=false, port=CBFaultDetectCtr_DTC_0x100034
        enable-take-address=true, indirect-api=false, port=CBFaultDetectCtr_DTC_0x100031
        enable-take-address=true, indirect-api=false, port=CBFaultDetectCtr_DTC_0x100032
        enable-take-address=true, indirect-api=false, port=CBFaultDetectCtr_DTC_0x100035
        enable-take-address=true, indirect-api=false, port=CBFaultDetectCtr_DTC_0xd12c30
        enable-take-address=true, indirect-api=false, port=CBFaultDetectCtr_DTC_0x100036
        enable-take-address=true, indirect-api=false, port=CBFaultDetectCtr_DTC_0x333000
        enable-take-address=true, indirect-api=false, port=CBFaultDetectCtr_DTC_0xd12112
        enable-take-address=true, indirect-api=false, port=CBFaultDetectCtr_DTC_0xd{12114..12119}
        enable-take-address=true, indirect-api=false, port=CBFaultDetectCtr_DTC_0xd01100
        enable-take-address=true, indirect-api=false, port=CBFaultDetectCtr_DTC_0xd12c00
        enable-take-address=true, indirect-api=false, port=CBFaultDetectCtr_DTC_0xd12c01
        enable-take-address=true, indirect-api=false, port=CBFaultDetectCtr_DTC_0xd12c08
        enable-take-address=true, indirect-api=false, port=CBFaultDetectCtr_DTC_0xd12c14
        enable-take-address=true, indirect-api=false, port=CBFaultDetectCtr_DTC_0xd12c17
        enable-take-address=true, indirect-api=false, port=CBFaultDetectCtr_DTC_0xd12c16
        enable-take-address=true, indirect-api=false, port=CBFaultDetectCtr_DTC_0xd12c18
        enable-take-address=true, indirect-api=false, port=CBFaultDetectCtr_DTC_0xd40100
        enable-take-address=true, indirect-api=false, port=CBFaultDetectCtr_DTC_0x000080
        enable-take-address=true, indirect-api=false, port=CBFaultDetectCtr_DTC_0xd12025
        enable-take-address=true, indirect-api=false, port=CBFaultDetectCtr_DTC_0xd12026
        enable-take-address=true, indirect-api=false, port=CBFaultDetectCtr_DTC_0x120022
        enable-take-address=true, indirect-api=false, port=CBFaultDetectCtr_DTC_0x120020
        enable-take-address=true, indirect-api=false, port=CBFaultDetectCtr_DTC_0x170400
        enable-take-address=true, indirect-api=false, port=CBFaultDetectCtr_DTC_0xd12159
        enable-take-address=true, indirect-api=false, port=CBFaultDetectCtr_DTC_0x00a009
        enable-take-address=true, indirect-api=false, port=CBFaultDetectCtr_DTC_0xd1210b
        enable-take-address=true, indirect-api=false, port=CBFaultDetectCtr_DTC_0xd1210c
        enable-take-address=true, indirect-api=false, port=CBFaultDetectCtr_DTC_0xd1210d
        enable-take-address=true, indirect-api=false, port=CBFaultDetectCtr_DTC_0xd1210e
        enable-take-address=true, indirect-api=false, port=CBFaultDetectCtr_DTC_0xd1210f
        enable-take-address=true, indirect-api=false, port=CBFaultDetectCtr_DTC_0xd{12000..12002}
        enable-take-address=true, indirect-api=false, port=CBFaultDetectCtr_DTC_0xd12004
        enable-take-address=true, indirect-api=false, port=CBFaultDetectCtr_DTC_0xe40004
        enable-take-address=true, indirect-api=false, port=CBFaultDetectCtr_DTC_0xe40005
        enable-take-address=true, indirect-api=false, port=CBFaultDetectCtr_DTC_0xe40002
        enable-take-address=true, indirect-api=false, port=CBFaultDetectCtr_DTC_0xe40003
        enable-take-address=true, indirect-api=false, port=CBFaultDetectCtr_DTC_0xe40001
        enable-take-address=true, indirect-api=false, port=CBFaultDetectCtr_DTC_0xd1211d
        enable-take-address=true, indirect-api=false, port=CBFaultDetectCtr_DTC_0xd12011
        enable-take-address=true, indirect-api=false, port=CBFaultDetectCtr_DTC_0xe40013
        enable-take-address=true, indirect-api=false, port=CBFaultDetectCtr_DTC_0xd13b51
        enable-take-address=true, indirect-api=false, port=CBFaultDetectCtr_DTC_0xd13b50
        enable-take-address=true, indirect-api=false, port=CBFaultDetectCtr_DTC_0xe40011
        enable-take-address=true, indirect-api=false, port=CBFaultDetectCtr_DTC_0xe40012
        enable-take-address=true, indirect-api=false, port=CBFaultDetectCtr_DTC_0x100203
        enable-take-address=true, indirect-api=false, port=CBFaultDetectCtr_DTC_0xe40010
        enable-take-address=true, indirect-api=false, port=CBFaultDetectCtr_DTC_0x12cb03
        enable-take-address=true, indirect-api=false, port=CBFaultDetectCtr_DTC_0x12cb04
        enable-take-address=true, indirect-api=false, port=CBFaultDetectCtr_DTC_0x12cb01
        enable-take-address=true, indirect-api=false, port=CBFaultDetectCtr_DTC_0x12cb02
        enable-take-address=true, indirect-api=false, port=CBFaultDetectCtr_DTC_0xe40008
        enable-take-address=true, indirect-api=false, port=CBFaultDetectCtr_DTC_0xe40009
        enable-take-address=true, indirect-api=false, port=CBFaultDetectCtr_DTC_0xe40006
        enable-take-address=true, indirect-api=false, port=CBFaultDetectCtr_DTC_0xe40007
        enable-take-address=true, indirect-api=false, port=CBFaultDetectCtr_DTC_0xd10301
        enable-take-address=true, indirect-api=false, port=CBFaultDetectCtr_DTC_0xd10300
        enable-take-address=true, indirect-api=false, port=CBFaultDetectCtr_DTC_0x170600
        enable-take-address=true, indirect-api=false, port=CBFaultDetectCtr_DTC_0x000016
        enable-take-address=true, indirect-api=false, port=CBFaultDetectCtr_DTC_0x000018
        enable-take-address=true, indirect-api=false, port=CBFaultDetectCtr_DTC_0xd1311d
        enable-take-address=true, indirect-api=false, port=CBFaultDetectCtr_DTC_0xd1311f
        enable-take-address=true, indirect-api=false, port=CBFaultDetectCtr_DTC_0xd12160
        enable-take-address=true, indirect-api=false, port=CBFaultDetectCtr_DTC_0xd12161
        enable-take-address=true, indirect-api=false, port=CBFaultDetectCtr_DTC_0x170612
        enable-take-address=true, indirect-api=false, port=CBFaultDetectCtr_DTC_0x000012
        enable-take-address=true, indirect-api=false, port=CBFaultDetectCtr_DTC_0x170610
        enable-take-address=true, indirect-api=false, port=CBFaultDetectCtr_DTC_0x000015
        enable-take-address=true, indirect-api=false, port=CBFaultDetectCtr_DTC_0x170611
        enable-take-address=true, indirect-api=false, port=CBFaultDetectCtr_DTC_0xd13026
        enable-take-address=true, indirect-api=false, port=CBFaultDetectCtr_DTC_0x170500
        {enable-take-address=true, indirect-api=false, port-defined-argument-value{value=0, value-type=uint8}, port=OpCycle_PowerCycle}
        enable-take-address=true, indirect-api=false, port=DemMaster_0/CBReadData_DID_0xF404_Calculate_Load_Value
        enable-take-address=true, indirect-api=false, port=DemMaster_0/CBReadData_DID_0xF405_Engine_Coolent_temperature
        enable-take-address=true, indirect-api=false, port=DemMaster_0/CBReadData_DID_0xF40C_Engine_RPM
        enable-take-address=true, indirect-api=false, port=DemMaster_0/CBReadData_DID_0xF41F_Time_Since_Engin_Start
        enable-take-address=true, indirect-api=false, port=DemMaster_0/CBReadData_DID_0xF40D_Vehicle_Speed_Sensor
        enable-take-address=true, indirect-api=false, port=DemMaster_0/CBReadData_DID_0xF442_Controle_Module_Voltage
        enable-take-address=true, indirect-api=false, port=DemMaster_0/CBReadData_DID_0xF449_Accelerator_Pedal_Position_D
        enable-take-address=true, indirect-api=false, port=DemMaster_0/CBReadData_EDC_Standard_DTC_Information
        enable-take-address=true, indirect-api=false, port=DemMaster_0/CBReadData_EDC_Standard_Freeze_Frame
        enable-take-address=true, indirect-api=false, port=DemMaster_0/CBReadData_EDC_Monitor_Activity_numerator_Counts
        enable-take-address=true, indirect-api=false, port=DemMaster_0/CBReadData_EDC_Stored_Monitor_Activity_Ratio
        enable-take-address=true, indirect-api=false, port=CBFaultDetectCtr_DTC_0x184c00
        enable-take-address=true, indirect-api=false, port=CBFaultDetectCtr_DTC_0x1d5af0
        enable-take-address=true, indirect-api=false, port=DemMaster_0/CBReadData_Data_StandardFreezeFrame1_Param_KmMilea_1
        enable-take-address=true, indirect-api=false, port=DemMaster_0/CBReadData_Data_PID_0xd_Param_VehicSpeedSenso
        enable-take-address=true, indirect-api=false, port=DemMaster_0/CBReadData_Data_PID_0x42_Param_ContrModulVolta
        enable-take-address=true, indirect-api=false, port=DemMaster_0/CBReadData_Data_PID_0xc_Param_EnginRPM
        enable-take-address=true, indirect-api=false, port=DemMaster_0/CBReadData_Data_PID_0x1f_Param_TimeSinceEnginStart
        enable-take-address=true, indirect-api=false, port=DemMaster_0/CBReadData_Data_SupplementalMonitorActivityData_Param_StoreMonitActivRatio
        enable-take-address=true, indirect-api=false, port=DemMaster_0/CBReadData_Data_PID_0x49_Param_AccelPedalPositD
        enable-take-address=true, indirect-api=false, port=DemMaster_0/CBReadData_Data_PID_0x4_Param_CalcuLOADValue
        enable-take-address=true, indirect-api=false, port=DemMaster_0/CBReadData_Data_PID_0x5_Param_EnginCoolaTempe
        enable-take-address=true, indirect-api=false, port=DemMaster_0/CBReadData_Data_StandardFreezeFrame1_Param_TimeStamp_STRUC_Bitfi
        enable-take-address=true, indirect-api=false, port=DemMaster_0/CBReadData_Data_StandardFreezeFrame1_Param_AgingCount
        enable-take-address=true, indirect-api=false, port=DemMaster_0/CBReadData_Data_StandardDTCInformation_Param_DTCPrior
        enable-take-address=true, indirect-api=false, port=DemMaster_0/CBReadData_Data_SupplementalMonitorActivityData_Param_MonitActivNumerCount
        enable-take-address=true, indirect-api=false, port=DemMaster_0/CBReadData_Data_StandardFreezeFrame1_Param_Reser
        enable-take-address=true, indirect-api=false, port=CBFaultDetectCtr_DTC_0x100000
        enable-take-address=true, indirect-api=false, port=DemMaster_0/CBReadData_Data_Vishnu_ExtData_Param_VishnDOB
        enable-take-address=true, indirect-api=false, port=DemMaster_0/CBReadData_Data_Vishnu_ExtData_Param_VishnRes
        {enable-take-address=true, indirect-api=false, port-defined-argument-value{value=1, value-type=uint8}, port=OpCycle_RT_Test_OpCycle}
        enable-take-address=true, indirect-api=false, port=CBFaultDetectCtr_DTC_0xe40000
        {enable-take-address=true, indirect-api=false, port-defined-argument-value{value=0, value-type=uint8}, port=ControlDTCSuppression_DemClient_DCM}
      22 x runnable:
        Dem_MasterMainFunction
          137 x sync call, all with timeout=0:
            OpServerCallDem_MasterMainFunction_ReadData_CBReadData_DemDataElementClass_StartApplication: operation=CBReadData_DemDataElementClass_StartApplication.ReadData
            OpServerCallDem_MasterMainFunction_GetFaultDetectionCounter_CBFaultDetectCtr_DTC_0x100002: operation=CBFaultDetectCtr_DTC_0x100002.GetFaultDetectionCounter
            OpServerCallDem_MasterMainFunction_GetFaultDetectionCounter_CBFaultDetectCtr_DTC_0x100003: operation=CBFaultDetectCtr_DTC_0x100003.GetFaultDetectionCounter
            OpServerCallDem_MasterMainFunction_GetFaultDetectionCounter_CBFaultDetectCtr_DTC_0xc12490: operation=CBFaultDetectCtr_DTC_0xc12490.GetFaultDetectionCounter
            OpServerCallDem_MasterMainFunction_GetFaultDetectionCounter_CBFaultDetectCtr_DTC_0x100009: operation=CBFaultDetectCtr_DTC_0x100009.GetFaultDetectionCounter
            OpServerCallDem_MasterMainFunction_GetFaultDetectionCounter_CBFaultDetectCtr_DTC_0xd40200: operation=CBFaultDetectCtr_DTC_0xd40200.GetFaultDetectionCounter
            OpServerCallDem_MasterMainFunction_GetFaultDetectionCounter_CBFaultDetectCtr_DTC_0x00b050: operation=CBFaultDetectCtr_DTC_0x00b050.GetFaultDetectionCounter
            OpServerCallDem_MasterMainFunction_GetFaultDetectionCounter_CBFaultDetectCtr_DTC_0x10000f: operation=CBFaultDetectCtr_DTC_0x10000f.GetFaultDetectionCounter
            OpServerCallDem_MasterMainFunction_GetFaultDetectionCounter_CBFaultDetectCtr_DTC_0x10001a: operation=CBFaultDetectCtr_DTC_0x10001a.GetFaultDetectionCounter
            OpServerCallDem_MasterMainFunction_GetFaultDetectionCounter_CBFaultDetectCtr_DTC_0x10001c: operation=CBFaultDetectCtr_DTC_0x10001c.GetFaultDetectionCounter
            OpServerCallDem_MasterMainFunction_GetFaultDetectionCounter_CBFaultDetectCtr_DTC_0x100011: operation=CBFaultDetectCtr_DTC_0x100011.GetFaultDetectionCounter
            OpServerCallDem_MasterMainFunction_GetFaultDetectionCounter_CBFaultDetectCtr_DTC_0x100012: operation=CBFaultDetectCtr_DTC_0x100012.GetFaultDetectionCounter
            OpServerCallDem_MasterMainFunction_GetFaultDetectionCounter_CBFaultDetectCtr_DTC_0x100010: operation=CBFaultDetectCtr_DTC_0x100010.GetFaultDetectionCounter
            OpServerCallDem_MasterMainFunction_GetFaultDetectionCounter_CBFaultDetectCtr_DTC_0x100013: operation=CBFaultDetectCtr_DTC_0x100013.GetFaultDetectionCounter
            OpServerCallDem_MasterMainFunction_GetFaultDetectionCounter_CBFaultDetectCtr_DTC_0x10000d: operation=CBFaultDetectCtr_DTC_0x10000d.GetFaultDetectionCounter
            OpServerCallDem_MasterMainFunction_GetFaultDetectionCounter_CBFaultDetectCtr_DTC_0x10000e: operation=CBFaultDetectCtr_DTC_0x10000e.GetFaultDetectionCounter
            OpServerCallDem_MasterMainFunction_GetFaultDetectionCounter_CBFaultDetectCtr_DTC_0x100044: operation=CBFaultDetectCtr_DTC_0x100044.GetFaultDetectionCounter
            OpServerCallDem_MasterMainFunction_GetFaultDetectionCounter_CBFaultDetectCtr_DTC_0x100042: operation=CBFaultDetectCtr_DTC_0x100042.GetFaultDetectionCounter
            OpServerCallDem_MasterMainFunction_GetFaultDetectionCounter_CBFaultDetectCtr_DTC_0x100043: operation=CBFaultDetectCtr_DTC_0x100043.GetFaultDetectionCounter
            OpServerCallDem_MasterMainFunction_GetFaultDetectionCounter_CBFaultDetectCtr_DTC_0xd12c20: operation=CBFaultDetectCtr_DTC_0xd12c20.GetFaultDetectionCounter
            OpServerCallDem_MasterMainFunction_GetFaultDetectionCounter_CBFaultDetectCtr_DTC_0xd12c21: operation=CBFaultDetectCtr_DTC_0xd12c21.GetFaultDetectionCounter
            OpServerCallDem_MasterMainFunction_GetFaultDetectionCounter_CBFaultDetectCtr_DTC_0xd01200: operation=CBFaultDetectCtr_DTC_0xd01200.GetFaultDetectionCounter
            OpServerCallDem_MasterMainFunction_GetFaultDetectionCounter_CBFaultDetectCtr_DTC_0xd12c23: operation=CBFaultDetectCtr_DTC_0xd12c23.GetFaultDetectionCounter
            OpServerCallDem_MasterMainFunction_GetFaultDetectionCounter_CBFaultDetectCtr_DTC_0x100041: operation=CBFaultDetectCtr_DTC_0x100041.GetFaultDetectionCounter
            OpServerCallDem_MasterMainFunction_GetFaultDetectionCounter_CBFaultDetectCtr_DTC_0xd{12101..12103}: operation=CBFaultDetectCtr_DTC_0xd{12101..12103}.GetFaultDetectionCounter
            OpServerCallDem_MasterMainFunction_GetFaultDetectionCounter_CBFaultDetectCtr_DTC_0x100033: operation=CBFaultDetectCtr_DTC_0x100033.GetFaultDetectionCounter
            OpServerCallDem_MasterMainFunction_GetFaultDetectionCounter_CBFaultDetectCtr_DTC_0x100034: operation=CBFaultDetectCtr_DTC_0x100034.GetFaultDetectionCounter
            OpServerCallDem_MasterMainFunction_GetFaultDetectionCounter_CBFaultDetectCtr_DTC_0x100031: operation=CBFaultDetectCtr_DTC_0x100031.GetFaultDetectionCounter
            OpServerCallDem_MasterMainFunction_GetFaultDetectionCounter_CBFaultDetectCtr_DTC_0x100032: operation=CBFaultDetectCtr_DTC_0x100032.GetFaultDetectionCounter
            OpServerCallDem_MasterMainFunction_GetFaultDetectionCounter_CBFaultDetectCtr_DTC_0x100035: operation=CBFaultDetectCtr_DTC_0x100035.GetFaultDetectionCounter
            OpServerCallDem_MasterMainFunction_GetFaultDetectionCounter_CBFaultDetectCtr_DTC_0xd12c30: operation=CBFaultDetectCtr_DTC_0xd12c30.GetFaultDetectionCounter
            OpServerCallDem_MasterMainFunction_GetFaultDetectionCounter_CBFaultDetectCtr_DTC_0x100036: operation=CBFaultDetectCtr_DTC_0x100036.GetFaultDetectionCounter
            OpServerCallDem_MasterMainFunction_GetFaultDetectionCounter_CBFaultDetectCtr_DTC_0x333000: operation=CBFaultDetectCtr_DTC_0x333000.GetFaultDetectionCounter
            OpServerCallDem_MasterMainFunction_GetFaultDetectionCounter_CBFaultDetectCtr_DTC_0xd12112: operation=CBFaultDetectCtr_DTC_0xd12112.GetFaultDetectionCounter
            OpServerCallDem_MasterMainFunction_GetFaultDetectionCounter_CBFaultDetectCtr_DTC_0xd{12114..12119}: operation=CBFaultDetectCtr_DTC_0xd{12114..12119}.GetFaultDetectionCounter
            OpServerCallDem_MasterMainFunction_GetFaultDetectionCounter_CBFaultDetectCtr_DTC_0xd01100: operation=CBFaultDetectCtr_DTC_0xd01100.GetFaultDetectionCounter
            OpServerCallDem_MasterMainFunction_GetFaultDetectionCounter_CBFaultDetectCtr_DTC_0xd12c00: operation=CBFaultDetectCtr_DTC_0xd12c00.GetFaultDetectionCounter
            OpServerCallDem_MasterMainFunction_GetFaultDetectionCounter_CBFaultDetectCtr_DTC_0xd12c01: operation=CBFaultDetectCtr_DTC_0xd12c01.GetFaultDetectionCounter
            OpServerCallDem_MasterMainFunction_GetFaultDetectionCounter_CBFaultDetectCtr_DTC_0xd12c08: operation=CBFaultDetectCtr_DTC_0xd12c08.GetFaultDetectionCounter
            OpServerCallDem_MasterMainFunction_GetFaultDetectionCounter_CBFaultDetectCtr_DTC_0xd12c14: operation=CBFaultDetectCtr_DTC_0xd12c14.GetFaultDetectionCounter
            OpServerCallDem_MasterMainFunction_GetFaultDetectionCounter_CBFaultDetectCtr_DTC_0xd12c17: operation=CBFaultDetectCtr_DTC_0xd12c17.GetFaultDetectionCounter
            OpServerCallDem_MasterMainFunction_GetFaultDetectionCounter_CBFaultDetectCtr_DTC_0xd12c16: operation=CBFaultDetectCtr_DTC_0xd12c16.GetFaultDetectionCounter
            OpServerCallDem_MasterMainFunction_GetFaultDetectionCounter_CBFaultDetectCtr_DTC_0xd12c18: operation=CBFaultDetectCtr_DTC_0xd12c18.GetFaultDetectionCounter
            OpServerCallDem_MasterMainFunction_GetFaultDetectionCounter_CBFaultDetectCtr_DTC_0xd40100: operation=CBFaultDetectCtr_DTC_0xd40100.GetFaultDetectionCounter
            OpServerCallDem_MasterMainFunction_GetFaultDetectionCounter_CBFaultDetectCtr_DTC_0x000080: operation=CBFaultDetectCtr_DTC_0x000080.GetFaultDetectionCounter
            OpServerCallDem_MasterMainFunction_GetFaultDetectionCounter_CBFaultDetectCtr_DTC_0xd12025: operation=CBFaultDetectCtr_DTC_0xd12025.GetFaultDetectionCounter
            OpServerCallDem_MasterMainFunction_GetFaultDetectionCounter_CBFaultDetectCtr_DTC_0xd12026: operation=CBFaultDetectCtr_DTC_0xd12026.GetFaultDetectionCounter
            OpServerCallDem_MasterMainFunction_GetFaultDetectionCounter_CBFaultDetectCtr_DTC_0x120022: operation=CBFaultDetectCtr_DTC_0x120022.GetFaultDetectionCounter
            OpServerCallDem_MasterMainFunction_GetFaultDetectionCounter_CBFaultDetectCtr_DTC_0x120020: operation=CBFaultDetectCtr_DTC_0x120020.GetFaultDetectionCounter
            OpServerCallDem_MasterMainFunction_GetFaultDetectionCounter_CBFaultDetectCtr_DTC_0x170400: operation=CBFaultDetectCtr_DTC_0x170400.GetFaultDetectionCounter
            OpServerCallDem_MasterMainFunction_GetFaultDetectionCounter_CBFaultDetectCtr_DTC_0xd12159: operation=CBFaultDetectCtr_DTC_0xd12159.GetFaultDetectionCounter
            OpServerCallDem_MasterMainFunction_GetFaultDetectionCounter_CBFaultDetectCtr_DTC_0x00a009: operation=CBFaultDetectCtr_DTC_0x00a009.GetFaultDetectionCounter
            OpServerCallDem_MasterMainFunction_GetFaultDetectionCounter_CBFaultDetectCtr_DTC_0xd1210b: operation=CBFaultDetectCtr_DTC_0xd1210b.GetFaultDetectionCounter
            OpServerCallDem_MasterMainFunction_GetFaultDetectionCounter_CBFaultDetectCtr_DTC_0xd1210c: operation=CBFaultDetectCtr_DTC_0xd1210c.GetFaultDetectionCounter
            OpServerCallDem_MasterMainFunction_GetFaultDetectionCounter_CBFaultDetectCtr_DTC_0xd1210d: operation=CBFaultDetectCtr_DTC_0xd1210d.GetFaultDetectionCounter
            OpServerCallDem_MasterMainFunction_GetFaultDetectionCounter_CBFaultDetectCtr_DTC_0xd1210e: operation=CBFaultDetectCtr_DTC_0xd1210e.GetFaultDetectionCounter
            OpServerCallDem_MasterMainFunction_GetFaultDetectionCounter_CBFaultDetectCtr_DTC_0xd1210f: operation=CBFaultDetectCtr_DTC_0xd1210f.GetFaultDetectionCounter
            OpServerCallDem_MasterMainFunction_GetFaultDetectionCounter_CBFaultDetectCtr_DTC_0xd{12000..12002}: operation=CBFaultDetectCtr_DTC_0xd{12000..12002}.GetFaultDetectionCounter
            OpServerCallDem_MasterMainFunction_GetFaultDetectionCounter_CBFaultDetectCtr_DTC_0xd12004: operation=CBFaultDetectCtr_DTC_0xd12004.GetFaultDetectionCounter
            OpServerCallDem_MasterMainFunction_GetFaultDetectionCounter_CBFaultDetectCtr_DTC_0xe40004: operation=CBFaultDetectCtr_DTC_0xe40004.GetFaultDetectionCounter
            OpServerCallDem_MasterMainFunction_GetFaultDetectionCounter_CBFaultDetectCtr_DTC_0xe40005: operation=CBFaultDetectCtr_DTC_0xe40005.GetFaultDetectionCounter
            OpServerCallDem_MasterMainFunction_GetFaultDetectionCounter_CBFaultDetectCtr_DTC_0xe40002: operation=CBFaultDetectCtr_DTC_0xe40002.GetFaultDetectionCounter
            OpServerCallDem_MasterMainFunction_GetFaultDetectionCounter_CBFaultDetectCtr_DTC_0xe40003: operation=CBFaultDetectCtr_DTC_0xe40003.GetFaultDetectionCounter
            OpServerCallDem_MasterMainFunction_GetFaultDetectionCounter_CBFaultDetectCtr_DTC_0xe40001: operation=CBFaultDetectCtr_DTC_0xe40001.GetFaultDetectionCounter
            OpServerCallDem_MasterMainFunction_GetFaultDetectionCounter_CBFaultDetectCtr_DTC_0xd1211d: operation=CBFaultDetectCtr_DTC_0xd1211d.GetFaultDetectionCounter
            OpServerCallDem_MasterMainFunction_GetFaultDetectionCounter_CBFaultDetectCtr_DTC_0xd12011: operation=CBFaultDetectCtr_DTC_0xd12011.GetFaultDetectionCounter
            OpServerCallDem_MasterMainFunction_GetFaultDetectionCounter_CBFaultDetectCtr_DTC_0xe40013: operation=CBFaultDetectCtr_DTC_0xe40013.GetFaultDetectionCounter
            OpServerCallDem_MasterMainFunction_GetFaultDetectionCounter_CBFaultDetectCtr_DTC_0xd13b51: operation=CBFaultDetectCtr_DTC_0xd13b51.GetFaultDetectionCounter
            OpServerCallDem_MasterMainFunction_GetFaultDetectionCounter_CBFaultDetectCtr_DTC_0xd13b50: operation=CBFaultDetectCtr_DTC_0xd13b50.GetFaultDetectionCounter
            OpServerCallDem_MasterMainFunction_GetFaultDetectionCounter_CBFaultDetectCtr_DTC_0xe40011: operation=CBFaultDetectCtr_DTC_0xe40011.GetFaultDetectionCounter
            OpServerCallDem_MasterMainFunction_GetFaultDetectionCounter_CBFaultDetectCtr_DTC_0xe40012: operation=CBFaultDetectCtr_DTC_0xe40012.GetFaultDetectionCounter
            OpServerCallDem_MasterMainFunction_GetFaultDetectionCounter_CBFaultDetectCtr_DTC_0x100203: operation=CBFaultDetectCtr_DTC_0x100203.GetFaultDetectionCounter
            OpServerCallDem_MasterMainFunction_GetFaultDetectionCounter_CBFaultDetectCtr_DTC_0xe40010: operation=CBFaultDetectCtr_DTC_0xe40010.GetFaultDetectionCounter
            OpServerCallDem_MasterMainFunction_GetFaultDetectionCounter_CBFaultDetectCtr_DTC_0x12cb03: operation=CBFaultDetectCtr_DTC_0x12cb03.GetFaultDetectionCounter
            OpServerCallDem_MasterMainFunction_GetFaultDetectionCounter_CBFaultDetectCtr_DTC_0x12cb04: operation=CBFaultDetectCtr_DTC_0x12cb04.GetFaultDetectionCounter
            OpServerCallDem_MasterMainFunction_GetFaultDetectionCounter_CBFaultDetectCtr_DTC_0x12cb01: operation=CBFaultDetectCtr_DTC_0x12cb01.GetFaultDetectionCounter
            OpServerCallDem_MasterMainFunction_GetFaultDetectionCounter_CBFaultDetectCtr_DTC_0x12cb02: operation=CBFaultDetectCtr_DTC_0x12cb02.GetFaultDetectionCounter
            OpServerCallDem_MasterMainFunction_GetFaultDetectionCounter_CBFaultDetectCtr_DTC_0xe40008: operation=CBFaultDetectCtr_DTC_0xe40008.GetFaultDetectionCounter
            OpServerCallDem_MasterMainFunction_GetFaultDetectionCounter_CBFaultDetectCtr_DTC_0xe40009: operation=CBFaultDetectCtr_DTC_0xe40009.GetFaultDetectionCounter
            OpServerCallDem_MasterMainFunction_GetFaultDetectionCounter_CBFaultDetectCtr_DTC_0xe40006: operation=CBFaultDetectCtr_DTC_0xe40006.GetFaultDetectionCounter
            OpServerCallDem_MasterMainFunction_GetFaultDetectionCounter_CBFaultDetectCtr_DTC_0xe40007: operation=CBFaultDetectCtr_DTC_0xe40007.GetFaultDetectionCounter
            OpServerCallDem_MasterMainFunction_GetFaultDetectionCounter_CBFaultDetectCtr_DTC_0xd10301: operation=CBFaultDetectCtr_DTC_0xd10301.GetFaultDetectionCounter
            OpServerCallDem_MasterMainFunction_GetFaultDetectionCounter_CBFaultDetectCtr_DTC_0xd10300: operation=CBFaultDetectCtr_DTC_0xd10300.GetFaultDetectionCounter
            OpServerCallDem_MasterMainFunction_GetFaultDetectionCounter_CBFaultDetectCtr_DTC_0x170600: operation=CBFaultDetectCtr_DTC_0x170600.GetFaultDetectionCounter
            OpServerCallDem_MasterMainFunction_GetFaultDetectionCounter_CBFaultDetectCtr_DTC_0x000016: operation=CBFaultDetectCtr_DTC_0x000016.GetFaultDetectionCounter
            OpServerCallDem_MasterMainFunction_GetFaultDetectionCounter_CBFaultDetectCtr_DTC_0x000018: operation=CBFaultDetectCtr_DTC_0x000018.GetFaultDetectionCounter
            OpServerCallDem_MasterMainFunction_GetFaultDetectionCounter_CBFaultDetectCtr_DTC_0xd1311d: operation=CBFaultDetectCtr_DTC_0xd1311d.GetFaultDetectionCounter
            OpServerCallDem_MasterMainFunction_GetFaultDetectionCounter_CBFaultDetectCtr_DTC_0xd1311f: operation=CBFaultDetectCtr_DTC_0xd1311f.GetFaultDetectionCounter
            OpServerCallDem_MasterMainFunction_GetFaultDetectionCounter_CBFaultDetectCtr_DTC_0xd12160: operation=CBFaultDetectCtr_DTC_0xd12160.GetFaultDetectionCounter
            OpServerCallDem_MasterMainFunction_GetFaultDetectionCounter_CBFaultDetectCtr_DTC_0xd12161: operation=CBFaultDetectCtr_DTC_0xd12161.GetFaultDetectionCounter
            OpServerCallDem_MasterMainFunction_GetFaultDetectionCounter_CBFaultDetectCtr_DTC_0x170612: operation=CBFaultDetectCtr_DTC_0x170612.GetFaultDetectionCounter
            OpServerCallDem_MasterMainFunction_GetFaultDetectionCounter_CBFaultDetectCtr_DTC_0x000012: operation=CBFaultDetectCtr_DTC_0x000012.GetFaultDetectionCounter
            OpServerCallDem_MasterMainFunction_GetFaultDetectionCounter_CBFaultDetectCtr_DTC_0x170610: operation=CBFaultDetectCtr_DTC_0x170610.GetFaultDetectionCounter
            OpServerCallDem_MasterMainFunction_GetFaultDetectionCounter_CBFaultDetectCtr_DTC_0x000015: operation=CBFaultDetectCtr_DTC_0x000015.GetFaultDetectionCounter
            OpServerCallDem_MasterMainFunction_GetFaultDetectionCounter_CBFaultDetectCtr_DTC_0x170611: operation=CBFaultDetectCtr_DTC_0x170611.GetFaultDetectionCounter
            OpServerCallDem_MasterMainFunction_GetFaultDetectionCounter_CBFaultDetectCtr_DTC_0xd13026: operation=CBFaultDetectCtr_DTC_0xd13026.GetFaultDetectionCounter
            OpServerCallDem_MasterMainFunction_GetFaultDetectionCounter_CBFaultDetectCtr_DTC_0x170500: operation=CBFaultDetectCtr_DTC_0x170500.GetFaultDetectionCounter
            OpServerCallDem_MasterMainFunction_ReadData_CBReadData_DID_0xF404_Calculate_Load_Value: operation=CBReadData_DID_0xF404_Calculate_Load_Value.ReadData
            OpServerCallDem_MasterMainFunction_ReadData_CBReadData_DID_0xF405_Engine_Coolent_temperature: operation=CBReadData_DID_0xF405_Engine_Coolent_temperature.ReadData
            OpServerCallDem_MasterMainFunction_ReadData_CBReadData_DID_0xF40C_Engine_RPM: operation=CBReadData_DID_0xF40C_Engine_RPM.ReadData
            OpServerCallDem_MasterMainFunction_ReadData_CBReadData_DID_0xF41F_Time_Since_Engin_Start: operation=CBReadData_DID_0xF41F_Time_Since_Engin_Start.ReadData
            OpServerCallDem_MasterMainFunction_ReadData_CBReadData_DID_0xF40D_Vehicle_Speed_Sensor: operation=CBReadData_DID_0xF40D_Vehicle_Speed_Sensor.ReadData
            OpServerCallDem_MasterMainFunction_ReadData_CBReadData_DID_0xF442_Controle_Module_Voltage: operation=CBReadData_DID_0xF442_Controle_Module_Voltage.ReadData
            OpServerCallDem_MasterMainFunction_ReadData_CBReadData_DID_0xF449_Accelerator_Pedal_Position_D: operation=CBReadData_DID_0xF449_Accelerator_Pedal_Position_D.ReadData
            OpServerCallDem_MasterMainFunction_ReadData_CBReadData_EDC_Standard_DTC_Information: operation=CBReadData_EDC_Standard_DTC_Information.ReadData
            OpServerCallDem_MasterMainFunction_ReadData_CBReadData_EDC_Standard_Freeze_Frame: operation=CBReadData_EDC_Standard_Freeze_Frame.ReadData
            OpServerCallDem_MasterMainFunction_ReadData_CBReadData_EDC_Monitor_Activity_numerator_Counts: operation=CBReadData_EDC_Monitor_Activity_numerator_Counts.ReadData
            OpServerCallDem_MasterMainFunction_ReadData_CBReadData_EDC_Stored_Monitor_Activity_Ratio: operation=CBReadData_EDC_Stored_Monitor_Activity_Ratio.ReadData
            OpServerCallDem_MasterMainFunction_GetFaultDetectionCounter_CBFaultDetectCtr_DTC_0x184c00: operation=CBFaultDetectCtr_DTC_0x184c00.GetFaultDetectionCounter
            OpServerCallDem_MasterMainFunction_GetFaultDetectionCounter_CBFaultDetectCtr_DTC_0x1d5af0: operation=CBFaultDetectCtr_DTC_0x1d5af0.GetFaultDetectionCounter
            OpServerCallDem_MasterMainFunction_ReadData_CBReadData_Data_StandardFreezeFrame1_Param_KmMilea_1: operation=CBReadData_Data_StandardFreezeFrame1_Param_KmMilea_1.ReadData
            OpServerCallDem_MasterMainFunction_ReadData_CBReadData_Data_PID_0xd_Param_VehicSpeedSenso: operation=CBReadData_Data_PID_0xd_Param_VehicSpeedSenso.ReadData
            OpServerCallDem_MasterMainFunction_ReadData_CBReadData_Data_PID_0x42_Param_ContrModulVolta: operation=CBReadData_Data_PID_0x42_Param_ContrModulVolta.ReadData
            OpServerCallDem_MasterMainFunction_ReadData_CBReadData_Data_PID_0xc_Param_EnginRPM: operation=CBReadData_Data_PID_0xc_Param_EnginRPM.ReadData
            OpServerCallDem_MasterMainFunction_ReadData_CBReadData_Data_PID_0x1f_Param_TimeSinceEnginStart: operation=CBReadData_Data_PID_0x1f_Param_TimeSinceEnginStart.ReadData
            OpServerCallDem_MasterMainFunction_ReadData_CBReadData_Data_SupplementalMonitorActivityData_Param_StoreMonitActivRatio: operation=CBReadData_Data_SupplementalMonitorActivityData_Param_StoreMonitActivRatio.ReadData
            OpServerCallDem_MasterMainFunction_ReadData_CBReadData_Data_PID_0x49_Param_AccelPedalPositD: operation=CBReadData_Data_PID_0x49_Param_AccelPedalPositD.ReadData
            OpServerCallDem_MasterMainFunction_ReadData_CBReadData_Data_PID_0x4_Param_CalcuLOADValue: operation=CBReadData_Data_PID_0x4_Param_CalcuLOADValue.ReadData
            OpServerCallDem_MasterMainFunction_ReadData_CBReadData_Data_PID_0x5_Param_EnginCoolaTempe: operation=CBReadData_Data_PID_0x5_Param_EnginCoolaTempe.ReadData
            OpServerCallDem_MasterMainFunction_ReadData_CBReadData_Data_StandardFreezeFrame1_Param_TimeStamp_STRUC_Bitfi: operation=CBReadData_Data_StandardFreezeFrame1_Param_TimeStamp_STRUC_Bitfi.ReadData
            OpServerCallDem_MasterMainFunction_ReadData_CBReadData_Data_StandardFreezeFrame1_Param_AgingCount: operation=CBReadData_Data_StandardFreezeFrame1_Param_AgingCount.ReadData
            OpServerCallDem_MasterMainFunction_ReadData_CBReadData_Data_StandardDTCInformation_Param_DTCPrior: operation=CBReadData_Data_StandardDTCInformation_Param_DTCPrior.ReadData
            OpServerCallDem_MasterMainFunction_ReadData_CBReadData_Data_SupplementalMonitorActivityData_Param_MonitActivNumerCount: operation=CBReadData_Data_SupplementalMonitorActivityData_Param_MonitActivNumerCount.ReadData
            OpServerCallDem_MasterMainFunction_ReadData_CBReadData_Data_StandardFreezeFrame1_Param_Reser: operation=CBReadData_Data_StandardFreezeFrame1_Param_Reser.ReadData
            OpServerCallDem_MasterMainFunction_GetFaultDetectionCounter_CBFaultDetectCtr_DTC_0x100000: operation=CBFaultDetectCtr_DTC_0x100000.GetFaultDetectionCounter
            OpServerCallDem_MasterMainFunction_ReadData_CBReadData_Data_Vishnu_ExtData_Param_VishnDOB: operation=CBReadData_Data_Vishnu_ExtData_Param_VishnDOB.ReadData
            OpServerCallDem_MasterMainFunction_ReadData_CBReadData_Data_Vishnu_ExtData_Param_VishnRes: operation=CBReadData_Data_Vishnu_ExtData_Param_VishnRes.ReadData
            OpServerCallDem_MasterMainFunction_GetFaultDetectionCounter_CBFaultDetectCtr_DTC_0xe40000: operation=CBFaultDetectCtr_DTC_0xe40000.GetFaultDetectionCounter
        PostRunRequested: can-be-invoked-concurrently=true, symbol=Dem_PostRunRequested
        GetDTCStatusAvailabilityMask: can-be-invoked-concurrently=true, symbol=Dem_GetDTCStatusAvailabilityMask
        GetEventUdsStatus: can-be-invoked-concurrently=true, symbol=Dem_GetEventUdsStatus
        GetEventStatus: can-be-invoked-concurrently=true, symbol=Dem_GetEventUdsStatus
        GetEventFailed: can-be-invoked-concurrently=true, symbol=Dem_GetEventFailed
        GetEventTested: can-be-invoked-concurrently=true, symbol=Dem_GetEventTested
        GetDTCOfEvent: can-be-invoked-concurrently=true, symbol=Dem_GetDTCOfEvent
        GetFaultDetectionCounter: can-be-invoked-concurrently=true, symbol=Dem_GetFaultDetectionCounter
        GetEventFreezeFrameDataEx: can-be-invoked-concurrently=true, symbol=Dem_GetEventFreezeFrameDataEx
        GetEventExtendedDataRecordEx: can-be-invoked-concurrently=true, symbol=Dem_GetEventExtendedDataRecordEx
        GetEventEnableCondition: can-be-invoked-concurrently=true, symbol=Dem_GetEventEnableCondition
        GetDebouncingOfEvent: can-be-invoked-concurrently=true, symbol=Dem_GetDebouncingOfEvent
        GetMonitorStatus: can-be-invoked-concurrently=true, symbol=Dem_GetMonitorStatus
        GetOperationCycleState: can-be-invoked-concurrently=true, symbol=Dem_GetOperationCycleState
        SetOperationCycleState: can-be-invoked-concurrently=true, symbol=Dem_SetOperationCycleState
        ClearDTC: can-be-invoked-concurrently=true, symbol=Dem_ClearDTC
        SelectDTC: can-be-invoked-concurrently=true, symbol=Dem_SelectDTC
        GetEventMemoryOverflow: can-be-invoked-concurrently=true, symbol=Dem_GetEventMemoryOverflow
        GetNumberOfEventMemoryEntries: can-be-invoked-concurrently=true, symbol=Dem_GetNumberOfEventMemoryEntries
        SetDTCSuppression: can-be-invoked-concurrently=true, symbol=Dem_SetDTCSuppression
        GetDTCSuppression: can-be-invoked-concurrently=true, symbol=Dem_GetDTCSuppression
  swc implementation DemMaster_0Implementation: programming-language=C, behavior=DemMaster_0InternalBehavior
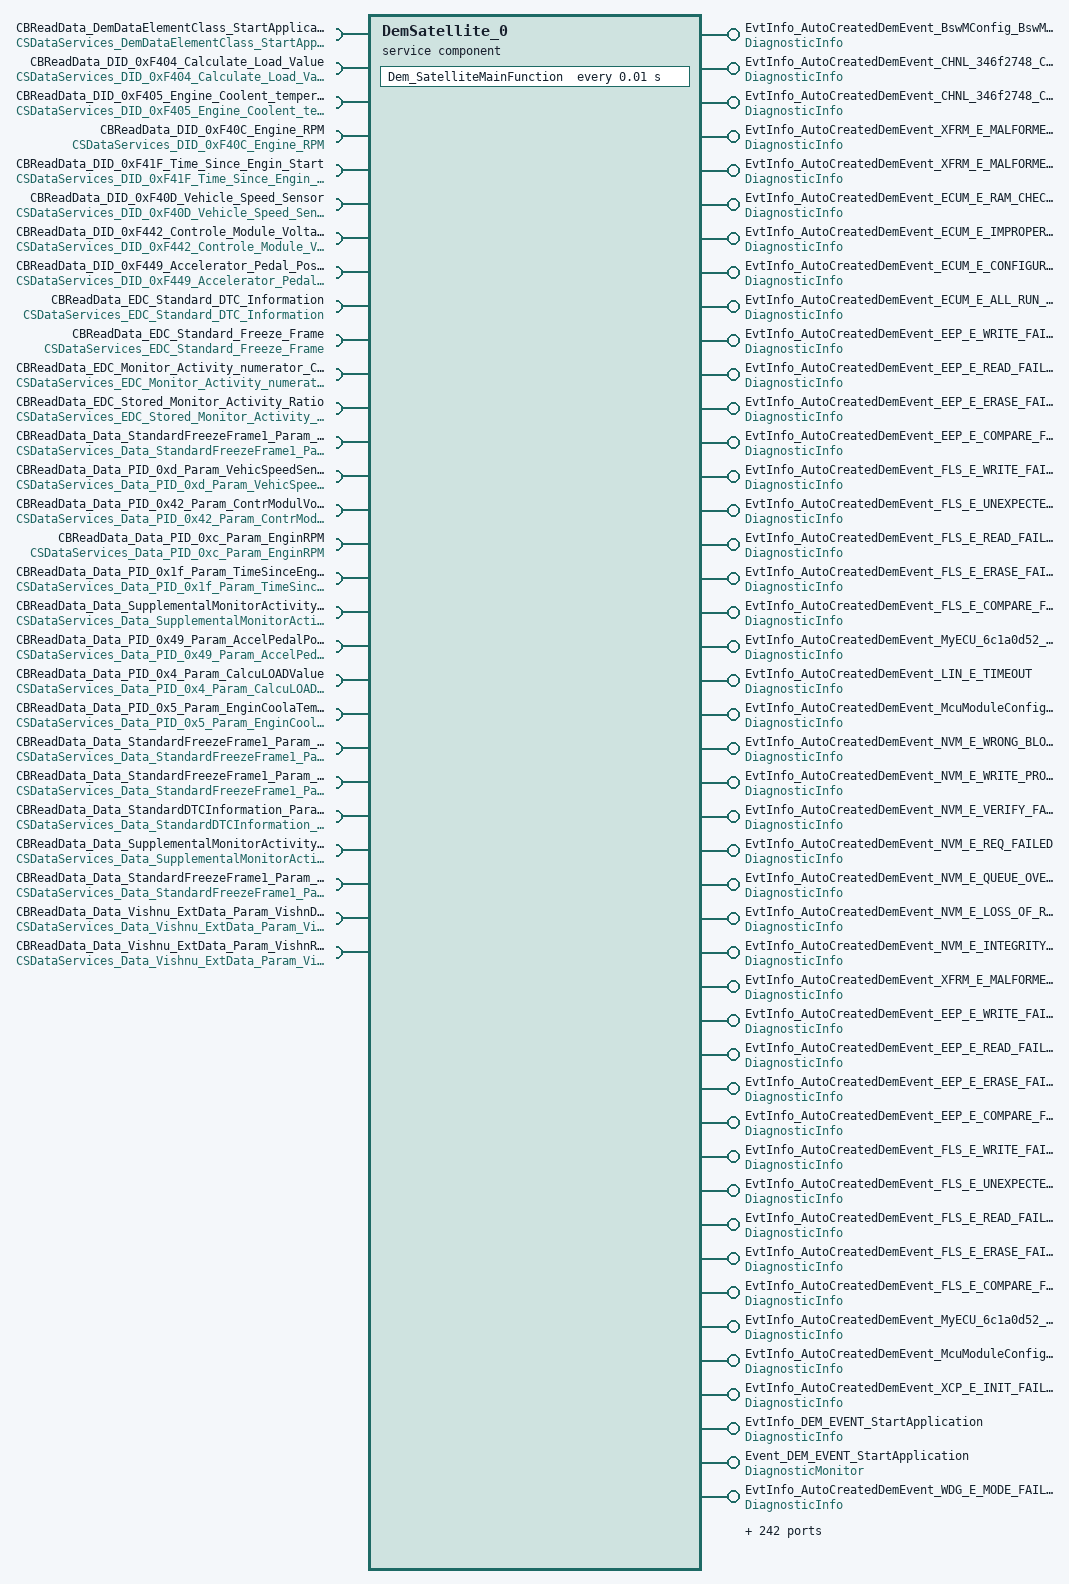
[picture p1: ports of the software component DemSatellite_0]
  service sw component type DemSatellite_0: category=SERVICE_COMPONENT
    43 x provide port:
      EvtInfo_AutoCreatedDemEvent_BswMConfig_BswMReportFailToDemRef: provided-interface=DiagnosticInfo
      EvtInfo_AutoCreatedDemEvent_CHNL_346f2748_CANSM_E_MODE_REQUEST_TIMEOUT: provided-interface=DiagnosticInfo
      EvtInfo_AutoCreatedDemEvent_CHNL_346f2748_CANSM_E_BUS_OFF: provided-interface=DiagnosticInfo
      EvtInfo_AutoCreatedDemEvent_XFRM_E_MALFORMED_MESSAGE: provided-interface=DiagnosticInfo
      EvtInfo_AutoCreatedDemEvent_XFRM_E_MALFORMED_MESSAGE_1: provided-interface=DiagnosticInfo
      EvtInfo_AutoCreatedDemEvent_ECUM_E_RAM_CHECK_FAILED: provided-interface=DiagnosticInfo
      EvtInfo_AutoCreatedDemEvent_ECUM_E_IMPROPER_CALLER: provided-interface=DiagnosticInfo
      EvtInfo_AutoCreatedDemEvent_ECUM_E_CONFIGURATION_DATA_INCONSISTENT: provided-interface=DiagnosticInfo
      EvtInfo_AutoCreatedDemEvent_ECUM_E_ALL_RUN_REQUESTS_KILLED: provided-interface=DiagnosticInfo
      EvtInfo_AutoCreatedDemEvent_EEP_E_WRITE_FAILED: provided-interface=DiagnosticInfo
      EvtInfo_AutoCreatedDemEvent_EEP_E_READ_FAILED: provided-interface=DiagnosticInfo
      EvtInfo_AutoCreatedDemEvent_EEP_E_ERASE_FAILED: provided-interface=DiagnosticInfo
      EvtInfo_AutoCreatedDemEvent_EEP_E_COMPARE_FAILED: provided-interface=DiagnosticInfo
      EvtInfo_AutoCreatedDemEvent_FLS_E_WRITE_FAILED: provided-interface=DiagnosticInfo
      EvtInfo_AutoCreatedDemEvent_FLS_E_UNEXPECTED_FLASH_ID: provided-interface=DiagnosticInfo
      EvtInfo_AutoCreatedDemEvent_FLS_E_READ_FAILED: provided-interface=DiagnosticInfo
      EvtInfo_AutoCreatedDemEvent_FLS_E_ERASE_FAILED: provided-interface=DiagnosticInfo
      EvtInfo_AutoCreatedDemEvent_FLS_E_COMPARE_FAILED: provided-interface=DiagnosticInfo
      EvtInfo_AutoCreatedDemEvent_MyECU_6c1a0d52_FrDemCtrlTestResultRef: provided-interface=DiagnosticInfo
      EvtInfo_AutoCreatedDemEvent_LIN_E_TIMEOUT: provided-interface=DiagnosticInfo
      EvtInfo_AutoCreatedDemEvent_McuModuleConfiguration_MCU_E_CLOCK_FAILURE: provided-interface=DiagnosticInfo
      EvtInfo_AutoCreatedDemEvent_NVM_E_WRONG_BLOCK_ID: provided-interface=DiagnosticInfo
      EvtInfo_AutoCreatedDemEvent_NVM_E_WRITE_PROTECTED: provided-interface=DiagnosticInfo
      EvtInfo_AutoCreatedDemEvent_NVM_E_VERIFY_FAILED: provided-interface=DiagnosticInfo
      EvtInfo_AutoCreatedDemEvent_NVM_E_REQ_FAILED: provided-interface=DiagnosticInfo
      EvtInfo_AutoCreatedDemEvent_NVM_E_QUEUE_OVERFLOW: provided-interface=DiagnosticInfo
      EvtInfo_AutoCreatedDemEvent_NVM_E_LOSS_OF_REDUNDANCY: provided-interface=DiagnosticInfo
      EvtInfo_AutoCreatedDemEvent_NVM_E_INTEGRITY_FAILED: provided-interface=DiagnosticInfo
      EvtInfo_AutoCreatedDemEvent_XFRM_E_MALFORMED_MESSAGE_2: provided-interface=DiagnosticInfo
      EvtInfo_AutoCreatedDemEvent_EEP_E_WRITE_FAILED_1: provided-interface=DiagnosticInfo
      EvtInfo_AutoCreatedDemEvent_EEP_E_READ_FAILED_1: provided-interface=DiagnosticInfo
      EvtInfo_AutoCreatedDemEvent_EEP_E_ERASE_FAILED_1: provided-interface=DiagnosticInfo
      EvtInfo_AutoCreatedDemEvent_EEP_E_COMPARE_FAILED_1: provided-interface=DiagnosticInfo
      EvtInfo_AutoCreatedDemEvent_FLS_E_WRITE_FAILED_1: provided-interface=DiagnosticInfo
      EvtInfo_AutoCreatedDemEvent_FLS_E_UNEXPECTED_FLASH_ID_1: provided-interface=DiagnosticInfo
      EvtInfo_AutoCreatedDemEvent_FLS_E_READ_FAILED_1: provided-interface=DiagnosticInfo
      EvtInfo_AutoCreatedDemEvent_FLS_E_ERASE_FAILED_1: provided-interface=DiagnosticInfo
      EvtInfo_AutoCreatedDemEvent_FLS_E_COMPARE_FAILED_1: provided-interface=DiagnosticInfo
      EvtInfo_AutoCreatedDemEvent_MyECU_6c1a0d52_FrDemCtrlTestResultRef_1: provided-interface=DiagnosticInfo
      EvtInfo_AutoCreatedDemEvent_McuModuleConfiguration_MCU_E_CLOCK_FAILURE_1: provided-interface=DiagnosticInfo
      EvtInfo_AutoCreatedDemEvent_XCP_E_INIT_FAILED: provided-interface=DiagnosticInfo
      EvtInfo_DEM_EVENT_StartApplication: provided-interface=DiagnosticInfo
      Event_DEM_EVENT_StartApplication: provided-interface=DiagnosticMonitor
    require port CBReadData_DemDataElementClass_StartApplication: required-interface=CSDataServices_DemDataElementClass_StartApplication
    238 x provide port:
      EvtInfo_AutoCreatedDemEvent_WDG_E_MODE_FAILED: provided-interface=DiagnosticInfo
      EvtInfo_AutoCreatedDemEvent_WDG_E_DISABLE_REJECTED: provided-interface=DiagnosticInfo
      EvtInfo_AutoCreatedDemEvent_WdgMDemEventParameterRefs_WDGM_E_SET_MODE: provided-interface=DiagnosticInfo
      EvtInfo_AutoCreatedDemEvent_WdgMDemEventParameterRefs_WDGM_E_MONITORING: provided-interface=DiagnosticInfo
      EvtInfo_AutoCreatedDemEvent_WdgMDemEventParameterRefs_WDGM_E_IMPROPER_CALLER: provided-interface=DiagnosticInfo
      GeneralEvtInfo: provided-interface=GeneralDiagnosticInfo
      EvtInfo_AutoCreatedDemEvent_FeeDemEventParameterRefs_FEE_E_WRITE_CYCLES_EXHAUSTED: provided-interface=DiagnosticInfo
      EvtInfo_AutoCreatedDemEvent_FeeDemEventParameterRefs_FEE_E_WRITE: provided-interface=DiagnosticInfo
      EvtInfo_AutoCreatedDemEvent_FeeDemEventParameterRefs_FEE_E_UNCONFIG_BLK_EXCEEDED: provided-interface=DiagnosticInfo
      EvtInfo_AutoCreatedDemEvent_FeeDemEventParameterRefs_FEE_E_READ: provided-interface=DiagnosticInfo
      EvtInfo_AutoCreatedDemEvent_FeeDemEventParameterRefs_FEE_E_INVALIDATE: provided-interface=DiagnosticInfo
      EvtInfo_AutoCreatedDemEvent_FeeDemEventParameterRefs_FEE_E_GC_WRITE: provided-interface=DiagnosticInfo
      EvtInfo_AutoCreatedDemEvent_FeeDemEventParameterRefs_FEE_E_GC_TRIG: provided-interface=DiagnosticInfo
      EvtInfo_AutoCreatedDemEvent_FeeDemEventParameterRefs_FEE_E_GC_READ: provided-interface=DiagnosticInfo
      EvtInfo_AutoCreatedDemEvent_FeeDemEventParameterRefs_FEE_E_GC_INIT: provided-interface=DiagnosticInfo
      EvtInfo_AutoCreatedDemEvent_FeeDemEventParameterRefs_FEE_E_GC_ERASE: provided-interface=DiagnosticInfo
      EvtInfo_DTC_0x100000: provided-interface=DiagnosticInfo
      Event_DTC_0x100000: provided-interface=DiagnosticMonitor
      EvtInfo_DTC_0x100002: provided-interface=DiagnosticInfo
      Event_DTC_0x100002: provided-interface=DiagnosticMonitor
      EvtInfo_DTC_0x100003: provided-interface=DiagnosticInfo
      Event_DTC_0x100003: provided-interface=DiagnosticMonitor
      EvtInfo_DTC_0xc12490: provided-interface=DiagnosticInfo
      Event_DTC_0xc12490: provided-interface=DiagnosticMonitor
      EvtInfo_DTC_0x100009: provided-interface=DiagnosticInfo
      Event_DTC_0x100009: provided-interface=DiagnosticMonitor
      EvtInfo_DTC_0xd40200: provided-interface=DiagnosticInfo
      Event_DTC_0xd40200: provided-interface=DiagnosticMonitor
      EvtInfo_DTC_0x00b050: provided-interface=DiagnosticInfo
      Event_DTC_0x00b050: provided-interface=DiagnosticMonitor
      EvtInfo_DTC_0x10000f: provided-interface=DiagnosticInfo
      Event_DTC_0x10000f: provided-interface=DiagnosticMonitor
      EvtInfo_DTC_0x10001a: provided-interface=DiagnosticInfo
      Event_DTC_0x10001a: provided-interface=DiagnosticMonitor
      EvtInfo_DTC_0x10001c: provided-interface=DiagnosticInfo
      Event_DTC_0x10001c: provided-interface=DiagnosticMonitor
      EvtInfo_DTC_0x100011: provided-interface=DiagnosticInfo
      Event_DTC_0x100011: provided-interface=DiagnosticMonitor
      EvtInfo_DTC_0x100012: provided-interface=DiagnosticInfo
      Event_DTC_0x100012: provided-interface=DiagnosticMonitor
      EvtInfo_DTC_0x100010: provided-interface=DiagnosticInfo
      Event_DTC_0x100010: provided-interface=DiagnosticMonitor
      EvtInfo_DTC_0x100013: provided-interface=DiagnosticInfo
      Event_DTC_0x100013: provided-interface=DiagnosticMonitor
      EvtInfo_DTC_0x10000a: provided-interface=DiagnosticInfo
      Event_DTC_0x10000a: provided-interface=DiagnosticMonitor
      EvtInfo_DTC_0x10000d: provided-interface=DiagnosticInfo
      Event_DTC_0x10000d: provided-interface=DiagnosticMonitor
      EvtInfo_DTC_0x10000e: provided-interface=DiagnosticInfo
      Event_DTC_0x10000e: provided-interface=DiagnosticMonitor
      EvtInfo_DTC_0x10000b: provided-interface=DiagnosticInfo
      Event_DTC_0x10000b: provided-interface=DiagnosticMonitor
      EvtInfo_DTC_0x100044: provided-interface=DiagnosticInfo
      Event_DTC_0x100044: provided-interface=DiagnosticMonitor
      EvtInfo_DTC_0x100042: provided-interface=DiagnosticInfo
      Event_DTC_0x100042: provided-interface=DiagnosticMonitor
      EvtInfo_DTC_0x100043: provided-interface=DiagnosticInfo
      Event_DTC_0x100043: provided-interface=DiagnosticMonitor
      EvtInfo_DTC_0xd12c20: provided-interface=DiagnosticInfo
      Event_DTC_0xd12c20: provided-interface=DiagnosticMonitor
      EvtInfo_DTC_0xd12c21: provided-interface=DiagnosticInfo
      Event_DTC_0xd12c21: provided-interface=DiagnosticMonitor
      EvtInfo_DTC_0xd01200: provided-interface=DiagnosticInfo
      Event_DTC_0xd01200: provided-interface=DiagnosticMonitor
      EvtInfo_DTC_0xd12c23: provided-interface=DiagnosticInfo
      Event_DTC_0xd12c23: provided-interface=DiagnosticMonitor
      EvtInfo_DTC_0x100041: provided-interface=DiagnosticInfo
      Event_DTC_0x100041: provided-interface=DiagnosticMonitor
      EvtInfo_DTC_0xd12101: provided-interface=DiagnosticInfo
      Event_DTC_0xd12101: provided-interface=DiagnosticMonitor
      EvtInfo_DTC_0xd12102: provided-interface=DiagnosticInfo
      Event_DTC_0xd12102: provided-interface=DiagnosticMonitor
      EvtInfo_DTC_0xd12103: provided-interface=DiagnosticInfo
      Event_DTC_0xd12103: provided-interface=DiagnosticMonitor
      EvtInfo_DTC_0x100033: provided-interface=DiagnosticInfo
      Event_DTC_0x100033: provided-interface=DiagnosticMonitor
      EvtInfo_DTC_0x100034: provided-interface=DiagnosticInfo
      Event_DTC_0x100034: provided-interface=DiagnosticMonitor
      EvtInfo_DTC_0x100031: provided-interface=DiagnosticInfo
      Event_DTC_0x100031: provided-interface=DiagnosticMonitor
      EvtInfo_DTC_0x100032: provided-interface=DiagnosticInfo
      Event_DTC_0x100032: provided-interface=DiagnosticMonitor
      EvtInfo_DTC_0x100035: provided-interface=DiagnosticInfo
      Event_DTC_0x100035: provided-interface=DiagnosticMonitor
      EvtInfo_DTC_0xd12c30: provided-interface=DiagnosticInfo
      Event_DTC_0xd12c30: provided-interface=DiagnosticMonitor
      EvtInfo_DTC_0x100036: provided-interface=DiagnosticInfo
      Event_DTC_0x100036: provided-interface=DiagnosticMonitor
      EvtInfo_DTC_0x333000: provided-interface=DiagnosticInfo
      Event_DTC_0x333000: provided-interface=DiagnosticMonitor
      EvtInfo_DTC_0xd12112: provided-interface=DiagnosticInfo
      Event_DTC_0xd12112: provided-interface=DiagnosticMonitor
      EvtInfo_DTC_0xd12114: provided-interface=DiagnosticInfo
      Event_DTC_0xd12114: provided-interface=DiagnosticMonitor
      EvtInfo_DTC_0xd12115: provided-interface=DiagnosticInfo
      Event_DTC_0xd12115: provided-interface=DiagnosticMonitor
      EvtInfo_DTC_0xd12116: provided-interface=DiagnosticInfo
      Event_DTC_0xd12116: provided-interface=DiagnosticMonitor
      EvtInfo_DTC_0xd12117: provided-interface=DiagnosticInfo
      Event_DTC_0xd12117: provided-interface=DiagnosticMonitor
      EvtInfo_DTC_0xd12118: provided-interface=DiagnosticInfo
      Event_DTC_0xd12118: provided-interface=DiagnosticMonitor
      EvtInfo_DTC_0xd12119: provided-interface=DiagnosticInfo
      Event_DTC_0xd12119: provided-interface=DiagnosticMonitor
      EvtInfo_DTC_0xd01100: provided-interface=DiagnosticInfo
      Event_DTC_0xd01100: provided-interface=DiagnosticMonitor
      EvtInfo_DTC_0xd12c00: provided-interface=DiagnosticInfo
      Event_DTC_0xd12c00: provided-interface=DiagnosticMonitor
      EvtInfo_DTC_0xd12c01: provided-interface=DiagnosticInfo
      Event_DTC_0xd12c01: provided-interface=DiagnosticMonitor
      EvtInfo_DTC_0xd12c08: provided-interface=DiagnosticInfo
      Event_DTC_0xd12c08: provided-interface=DiagnosticMonitor
      EvtInfo_DTC_0xd12c14: provided-interface=DiagnosticInfo
      Event_DTC_0xd12c14: provided-interface=DiagnosticMonitor
      EvtInfo_DTC_0xd12c17: provided-interface=DiagnosticInfo
      Event_DTC_0xd12c17: provided-interface=DiagnosticMonitor
      EvtInfo_DTC_0xd12c16: provided-interface=DiagnosticInfo
      Event_DTC_0xd12c16: provided-interface=DiagnosticMonitor
      EvtInfo_DTC_0xd12c18: provided-interface=DiagnosticInfo
      Event_DTC_0xd12c18: provided-interface=DiagnosticMonitor
      EvtInfo_DTC_0xd40100: provided-interface=DiagnosticInfo
      Event_DTC_0xd40100: provided-interface=DiagnosticMonitor
      EvtInfo_DTC_0x000080: provided-interface=DiagnosticInfo
      Event_DTC_0x000080: provided-interface=DiagnosticMonitor
      EvtInfo_DTC_0xd12025: provided-interface=DiagnosticInfo
      Event_DTC_0xd12025: provided-interface=DiagnosticMonitor
      EvtInfo_DTC_0xd12026: provided-interface=DiagnosticInfo
      Event_DTC_0xd12026: provided-interface=DiagnosticMonitor
      EvtInfo_DTC_0x120022: provided-interface=DiagnosticInfo
      Event_DTC_0x120022: provided-interface=DiagnosticMonitor
      EvtInfo_DTC_0x120020: provided-interface=DiagnosticInfo
      Event_DTC_0x120020: provided-interface=DiagnosticMonitor
      EvtInfo_DTC_0x170400: provided-interface=DiagnosticInfo
      Event_DTC_0x170400: provided-interface=DiagnosticMonitor
      EvtInfo_DTC_0xd12159: provided-interface=DiagnosticInfo
      Event_DTC_0xd12159: provided-interface=DiagnosticMonitor
      EvtInfo_DTC_0x00a009: provided-interface=DiagnosticInfo
      Event_DTC_0x00a009: provided-interface=DiagnosticMonitor
      EvtInfo_DTC_0xd1210b: provided-interface=DiagnosticInfo
      Event_DTC_0xd1210b: provided-interface=DiagnosticMonitor
      EvtInfo_DTC_0xd1210c: provided-interface=DiagnosticInfo
      Event_DTC_0xd1210c: provided-interface=DiagnosticMonitor
      EvtInfo_DTC_0xd1210d: provided-interface=DiagnosticInfo
      Event_DTC_0xd1210d: provided-interface=DiagnosticMonitor
      EvtInfo_DTC_0xd1210e: provided-interface=DiagnosticInfo
      Event_DTC_0xd1210e: provided-interface=DiagnosticMonitor
      EvtInfo_DTC_0xd1210f: provided-interface=DiagnosticInfo
      Event_DTC_0xd1210f: provided-interface=DiagnosticMonitor
      EvtInfo_DTC_0xd12000: provided-interface=DiagnosticInfo
      Event_DTC_0xd12000: provided-interface=DiagnosticMonitor
      EvtInfo_DTC_0xd12001: provided-interface=DiagnosticInfo
      Event_DTC_0xd12001: provided-interface=DiagnosticMonitor
      EvtInfo_DTC_0xd12002: provided-interface=DiagnosticInfo
      Event_DTC_0xd12002: provided-interface=DiagnosticMonitor
      EvtInfo_DTC_0xd12004: provided-interface=DiagnosticInfo
      Event_DTC_0xd12004: provided-interface=DiagnosticMonitor
      EvtInfo_DTC_0xe40004: provided-interface=DiagnosticInfo
      Event_DTC_0xe40004: provided-interface=DiagnosticMonitor
      EvtInfo_DTC_0x00a00a: provided-interface=DiagnosticInfo
      Event_DTC_0x00a00a: provided-interface=DiagnosticMonitor
      EvtInfo_DTC_0xe40005: provided-interface=DiagnosticInfo
      Event_DTC_0xe40005: provided-interface=DiagnosticMonitor
      EvtInfo_DTC_0xe40002: provided-interface=DiagnosticInfo
      Event_DTC_0xe40002: provided-interface=DiagnosticMonitor
      EvtInfo_DTC_0xe40003: provided-interface=DiagnosticInfo
      Event_DTC_0xe40003: provided-interface=DiagnosticMonitor
      EvtInfo_DTC_0xe40000: provided-interface=DiagnosticInfo
      Event_DTC_0xe40000: provided-interface=DiagnosticMonitor
      EvtInfo_DTC_0xe40001: provided-interface=DiagnosticInfo
      Event_DTC_0xe40001: provided-interface=DiagnosticMonitor
      EvtInfo_DTC_0x00a00b: provided-interface=DiagnosticInfo
      Event_DTC_0x00a00b: provided-interface=DiagnosticMonitor
      EvtInfo_DTC_0xd1211d: provided-interface=DiagnosticInfo
      Event_DTC_0xd1211d: provided-interface=DiagnosticMonitor
      EvtInfo_DTC_0xd12011: provided-interface=DiagnosticInfo
      Event_DTC_0xd12011: provided-interface=DiagnosticMonitor
      EvtInfo_DTC_0xe40013: provided-interface=DiagnosticInfo
      Event_DTC_0xe40013: provided-interface=DiagnosticMonitor
      EvtInfo_DTC_0xd13b51: provided-interface=DiagnosticInfo
      Event_DTC_0xd13b51: provided-interface=DiagnosticMonitor
      EvtInfo_DTC_0xd13b50: provided-interface=DiagnosticInfo
      Event_DTC_0xd13b50: provided-interface=DiagnosticMonitor
      EvtInfo_DTC_0xe40011: provided-interface=DiagnosticInfo
      Event_DTC_0xe40011: provided-interface=DiagnosticMonitor
      EvtInfo_DTC_0xe40012: provided-interface=DiagnosticInfo
      Event_DTC_0xe40012: provided-interface=DiagnosticMonitor
      EvtInfo_DTC_0x100203: provided-interface=DiagnosticInfo
      Event_DTC_0x100203: provided-interface=DiagnosticMonitor
      EvtInfo_DTC_0xe40010: provided-interface=DiagnosticInfo
      Event_DTC_0xe40010: provided-interface=DiagnosticMonitor
      EvtInfo_DTC_0x12cb03: provided-interface=DiagnosticInfo
      Event_DTC_0x12cb03: provided-interface=DiagnosticMonitor
      EvtInfo_DTC_0x12cb04: provided-interface=DiagnosticInfo
      Event_DTC_0x12cb04: provided-interface=DiagnosticMonitor
      EvtInfo_DTC_0x12cb01: provided-interface=DiagnosticInfo
      Event_DTC_0x12cb01: provided-interface=DiagnosticMonitor
      EvtInfo_DTC_0x12cb02: provided-interface=DiagnosticInfo
      Event_DTC_0x12cb02: provided-interface=DiagnosticMonitor
      EvtInfo_DTC_0xe40008: provided-interface=DiagnosticInfo
      Event_DTC_0xe40008: provided-interface=DiagnosticMonitor
      EvtInfo_DTC_0xe40009: provided-interface=DiagnosticInfo
      Event_DTC_0xe40009: provided-interface=DiagnosticMonitor
      EvtInfo_DTC_0xe40006: provided-interface=DiagnosticInfo
      Event_DTC_0xe40006: provided-interface=DiagnosticMonitor
      EvtInfo_DTC_0xe40007: provided-interface=DiagnosticInfo
      Event_DTC_0xe40007: provided-interface=DiagnosticMonitor
      EvtInfo_DTC_0xd10301: provided-interface=DiagnosticInfo
      Event_DTC_0xd10301: provided-interface=DiagnosticMonitor
      EvtInfo_DTC_0xd10300: provided-interface=DiagnosticInfo
      Event_DTC_0xd10300: provided-interface=DiagnosticMonitor
      EvtInfo_DTC_0x170600: provided-interface=DiagnosticInfo
      Event_DTC_0x170600: provided-interface=DiagnosticMonitor
      EvtInfo_DTC_0x000016: provided-interface=DiagnosticInfo
      Event_DTC_0x000016: provided-interface=DiagnosticMonitor
      EvtInfo_DTC_0x000018: provided-interface=DiagnosticInfo
      Event_DTC_0x000018: provided-interface=DiagnosticMonitor
      EvtInfo_DTC_0xd1311d: provided-interface=DiagnosticInfo
      Event_DTC_0xd1311d: provided-interface=DiagnosticMonitor
      EvtInfo_DTC_0xd1311f: provided-interface=DiagnosticInfo
      Event_DTC_0xd1311f: provided-interface=DiagnosticMonitor
      EvtInfo_DTC_0xd12160: provided-interface=DiagnosticInfo
      Event_DTC_0xd12160: provided-interface=DiagnosticMonitor
      EvtInfo_DTC_0xd12161: provided-interface=DiagnosticInfo
      Event_DTC_0xd12161: provided-interface=DiagnosticMonitor
      EvtInfo_DTC_0x170612: provided-interface=DiagnosticInfo
      Event_DTC_0x170612: provided-interface=DiagnosticMonitor
      EvtInfo_DTC_0x000012: provided-interface=DiagnosticInfo
      Event_DTC_0x000012: provided-interface=DiagnosticMonitor
      EvtInfo_DTC_0x170610: provided-interface=DiagnosticInfo
      Event_DTC_0x170610: provided-interface=DiagnosticMonitor
      EvtInfo_DTC_0x000015: provided-interface=DiagnosticInfo
      Event_DTC_0x000015: provided-interface=DiagnosticMonitor
      EvtInfo_DTC_0x170611: provided-interface=DiagnosticInfo
      Event_DTC_0x170611: provided-interface=DiagnosticMonitor
      EvtInfo_DTC_0xd13026: provided-interface=DiagnosticInfo
      Event_DTC_0xd13026: provided-interface=DiagnosticMonitor
      EvtInfo_DTC_0x170500: provided-interface=DiagnosticInfo
      Event_DTC_0x170500: provided-interface=DiagnosticMonitor
    11 x require port:
      CBReadData_DID_0xF404_Calculate_Load_Value: required-interface=CSDataServices_DID_0xF404_Calculate_Load_Value
      CBReadData_DID_0xF405_Engine_Coolent_temperature: required-interface=CSDataServices_DID_0xF405_Engine_Coolent_temperature
      CBReadData_DID_0xF40C_Engine_RPM: required-interface=CSDataServices_DID_0xF40C_Engine_RPM
      CBReadData_DID_0xF41F_Time_Since_Engin_Start: required-interface=CSDataServices_DID_0xF41F_Time_Since_Engin_Start
      CBReadData_DID_0xF40D_Vehicle_Speed_Sensor: required-interface=CSDataServices_DID_0xF40D_Vehicle_Speed_Sensor
      CBReadData_DID_0xF442_Controle_Module_Voltage: required-interface=CSDataServices_DID_0xF442_Controle_Module_Voltage
      CBReadData_DID_0xF449_Accelerator_Pedal_Position_D: required-interface=CSDataServices_DID_0xF449_Accelerator_Pedal_Position_D
      CBReadData_EDC_Standard_DTC_Information: required-interface=CSDataServices_EDC_Standard_DTC_Information
      CBReadData_EDC_Standard_Freeze_Frame: required-interface=CSDataServices_EDC_Standard_Freeze_Frame
      CBReadData_EDC_Monitor_Activity_numerator_Counts: required-interface=CSDataServices_EDC_Monitor_Activity_numerator_Counts
      CBReadData_EDC_Stored_Monitor_Activity_Ratio: required-interface=CSDataServices_EDC_Stored_Monitor_Activity_Ratio
    4 x provide port:
      EvtInfo_DTC_0x184c00: provided-interface=DiagnosticInfo
      Event_DTC_0x184c00: provided-interface=DiagnosticMonitor
      EvtInfo_DTC_0x1d5af0: provided-interface=DiagnosticInfo
      Event_DTC_0x1d5af0: provided-interface=DiagnosticMonitor
    16 x require port:
      CBReadData_Data_StandardFreezeFrame1_Param_KmMilea_1: required-interface=CSDataServices_Data_StandardFreezeFrame1_Param_KmMilea_1
      CBReadData_Data_PID_0xd_Param_VehicSpeedSenso: required-interface=CSDataServices_Data_PID_0xd_Param_VehicSpeedSenso
      CBReadData_Data_PID_0x42_Param_ContrModulVolta: required-interface=CSDataServices_Data_PID_0x42_Param_ContrModulVolta
      CBReadData_Data_PID_0xc_Param_EnginRPM: required-interface=CSDataServices_Data_PID_0xc_Param_EnginRPM
      CBReadData_Data_PID_0x1f_Param_TimeSinceEnginStart: required-interface=CSDataServices_Data_PID_0x1f_Param_TimeSinceEnginStart
      CBReadData_Data_SupplementalMonitorActivityData_Param_StoreMonitActivRatio: required-interface=CSDataServices_Data_SupplementalMonitorActivityData_Param_StoreMonitActivRatio
      CBReadData_Data_PID_0x49_Param_AccelPedalPositD: required-interface=CSDataServices_Data_PID_0x49_Param_AccelPedalPositD
      CBReadData_Data_PID_0x4_Param_CalcuLOADValue: required-interface=CSDataServices_Data_PID_0x4_Param_CalcuLOADValue
      CBReadData_Data_PID_0x5_Param_EnginCoolaTempe: required-interface=CSDataServices_Data_PID_0x5_Param_EnginCoolaTempe
      CBReadData_Data_StandardFreezeFrame1_Param_TimeStamp_STRUC_Bitfi: required-interface=CSDataServices_Data_StandardFreezeFrame1_Param_TimeStamp_STRUC_Bitfi
      CBReadData_Data_StandardFreezeFrame1_Param_AgingCount: required-interface=CSDataServices_Data_StandardFreezeFrame1_Param_AgingCount
      CBReadData_Data_StandardDTCInformation_Param_DTCPrior: required-interface=CSDataServices_Data_StandardDTCInformation_Param_DTCPrior
      CBReadData_Data_SupplementalMonitorActivityData_Param_MonitActivNumerCount: required-interface=CSDataServices_Data_SupplementalMonitorActivityData_Param_MonitActivNumerCount
      CBReadData_Data_StandardFreezeFrame1_Param_Reser: required-interface=CSDataServices_Data_StandardFreezeFrame1_Param_Reser
      CBReadData_Data_Vishnu_ExtData_Param_VishnDOB: required-interface=CSDataServices_Data_Vishnu_ExtData_Param_VishnDOB
      CBReadData_Data_Vishnu_ExtData_Param_VishnRes: required-interface=CSDataServices_Data_Vishnu_ExtData_Param_VishnRes
    provide port EvtInfo_Busoff_Event: provided-interface=DiagnosticInfo
    behavior DemSatellite_0InternalBehavior: handle-termination-and-restart=NO-SUPPORT, included-data-type-set=data-type=[Dem_EventIdType, Dem_RatioIdType, Dem_EventStatusType, Dem_UdsStatusByteType, Dem_DTCFormatType, Dem_InitMonitorReasonType, Dem_OperationCycleStateType, Dem_DTCStatusMaskType, Dem_IndicatorStatusType, Dem_MaxDataValueType, Dem_DTCKindType, Dem_DTCGroupType, Dem_IumprDenomCondIdType, Dem_IumprDenomCondStatusType, Dem_DebounceResetStatusType, Dem_DebouncingStateType, Dem_IumprReadinessGroupType, Dem_DTRControlType, Dem_DTCSeverityType, Dem_MonitorStatusType]
      timing event Timer_Dem_SatelliteMainFunction: start-on-event=Dem_SatelliteMainFunction, period=0.01
      3146 x operation invoked event:
        OpEventGetEventUdsStatus_GetEventUdsStatus_EvtInfo_AutoCreatedDemEvent_BswMConfig_BswMReportFailToDemRef: start-on-event=DemSatellite_0InternalBehavior/GetEventUdsStatus, operation=EvtInfo_AutoCreatedDemEvent_BswMConfig_BswMReportFailToDemRef.GetEventUdsStatus
        OpEventGetEventUdsStatus_GetEventUdsStatus_EvtInfo_AutoCreatedDemEvent_CHNL_346f2748_CANSM_E_MODE_REQUEST_TIMEOUT: start-on-event=DemSatellite_0InternalBehavior/GetEventUdsStatus, operation=EvtInfo_AutoCreatedDemEvent_CHNL_346f2748_CANSM_E_MODE_REQUEST_TIMEOUT.GetEventUdsStatus
        OpEventGetEventUdsStatus_GetEventUdsStatus_EvtInfo_AutoCreatedDemEvent_CHNL_346f2748_CANSM_E_BUS_OFF: start-on-event=DemSatellite_0InternalBehavior/GetEventUdsStatus, operation=EvtInfo_AutoCreatedDemEvent_CHNL_346f2748_CANSM_E_BUS_OFF.GetEventUdsStatus
        OpEventGetEventUdsStatus_GetEventUdsStatus_EvtInfo_AutoCreatedDemEvent_XFRM_E_MALFORMED_MESSAGE: start-on-event=DemSatellite_0InternalBehavior/GetEventUdsStatus, operation=EvtInfo_AutoCreatedDemEvent_XFRM_E_MALFORMED_MESSAGE.GetEventUdsStatus
        OpEventGetEventUdsStatus_GetEventUdsStatus_EvtInfo_AutoCreatedDemEvent_XFRM_E_MALFORMED_MESSAGE_1: start-on-event=DemSatellite_0InternalBehavior/GetEventUdsStatus, operation=EvtInfo_AutoCreatedDemEvent_XFRM_E_MALFORMED_MESSAGE_1.GetEventUdsStatus
        OpEventGetEventUdsStatus_GetEventUdsStatus_EvtInfo_AutoCreatedDemEvent_ECUM_E_RAM_CHECK_FAILED: start-on-event=DemSatellite_0InternalBehavior/GetEventUdsStatus, operation=EvtInfo_AutoCreatedDemEvent_ECUM_E_RAM_CHECK_FAILED.GetEventUdsStatus
        OpEventGetEventUdsStatus_GetEventUdsStatus_EvtInfo_AutoCreatedDemEvent_ECUM_E_IMPROPER_CALLER: start-on-event=DemSatellite_0InternalBehavior/GetEventUdsStatus, operation=EvtInfo_AutoCreatedDemEvent_ECUM_E_IMPROPER_CALLER.GetEventUdsStatus
        OpEventGetEventUdsStatus_GetEventUdsStatus_EvtInfo_AutoCreatedDemEvent_ECUM_E_CONFIGURATION_DATA_INCONSISTENT: start-on-event=DemSatellite_0InternalBehavior/GetEventUdsStatus, operation=EvtInfo_AutoCreatedDemEvent_ECUM_E_CONFIGURATION_DATA_INCONSISTENT.GetEventUdsStatus
        OpEventGetEventUdsStatus_GetEventUdsStatus_EvtInfo_AutoCreatedDemEvent_ECUM_E_ALL_RUN_REQUESTS_KILLED: start-on-event=DemSatellite_0InternalBehavior/GetEventUdsStatus, operation=EvtInfo_AutoCreatedDemEvent_ECUM_E_ALL_RUN_REQUESTS_KILLED.GetEventUdsStatus
        OpEventGetEventUdsStatus_GetEventUdsStatus_EvtInfo_AutoCreatedDemEvent_EEP_E_WRITE_FAILED: start-on-event=DemSatellite_0InternalBehavior/GetEventUdsStatus, operation=EvtInfo_AutoCreatedDemEvent_EEP_E_WRITE_FAILED.GetEventUdsStatus
        OpEventGetEventUdsStatus_GetEventUdsStatus_EvtInfo_AutoCreatedDemEvent_EEP_E_READ_FAILED: start-on-event=DemSatellite_0InternalBehavior/GetEventUdsStatus, operation=EvtInfo_AutoCreatedDemEvent_EEP_E_READ_FAILED.GetEventUdsStatus
        OpEventGetEventUdsStatus_GetEventUdsStatus_EvtInfo_AutoCreatedDemEvent_EEP_E_ERASE_FAILED: start-on-event=DemSatellite_0InternalBehavior/GetEventUdsStatus, operation=EvtInfo_AutoCreatedDemEvent_EEP_E_ERASE_FAILED.GetEventUdsStatus
        OpEventGetEventUdsStatus_GetEventUdsStatus_EvtInfo_AutoCreatedDemEvent_EEP_E_COMPARE_FAILED: start-on-event=DemSatellite_0InternalBehavior/GetEventUdsStatus, operation=EvtInfo_AutoCreatedDemEvent_EEP_E_COMPARE_FAILED.GetEventUdsStatus
        OpEventGetEventUdsStatus_GetEventUdsStatus_EvtInfo_AutoCreatedDemEvent_FLS_E_WRITE_FAILED: start-on-event=DemSatellite_0InternalBehavior/GetEventUdsStatus, operation=EvtInfo_AutoCreatedDemEvent_FLS_E_WRITE_FAILED.GetEventUdsStatus
        OpEventGetEventUdsStatus_GetEventUdsStatus_EvtInfo_AutoCreatedDemEvent_FLS_E_UNEXPECTED_FLASH_ID: start-on-event=DemSatellite_0InternalBehavior/GetEventUdsStatus, operation=EvtInfo_AutoCreatedDemEvent_FLS_E_UNEXPECTED_FLASH_ID.GetEventUdsStatus
        OpEventGetEventUdsStatus_GetEventUdsStatus_EvtInfo_AutoCreatedDemEvent_FLS_E_READ_FAILED: start-on-event=DemSatellite_0InternalBehavior/GetEventUdsStatus, operation=EvtInfo_AutoCreatedDemEvent_FLS_E_READ_FAILED.GetEventUdsStatus
        OpEventGetEventUdsStatus_GetEventUdsStatus_EvtInfo_AutoCreatedDemEvent_FLS_E_ERASE_FAILED: start-on-event=DemSatellite_0InternalBehavior/GetEventUdsStatus, operation=EvtInfo_AutoCreatedDemEvent_FLS_E_ERASE_FAILED.GetEventUdsStatus
        OpEventGetEventUdsStatus_GetEventUdsStatus_EvtInfo_AutoCreatedDemEvent_FLS_E_COMPARE_FAILED: start-on-event=DemSatellite_0InternalBehavior/GetEventUdsStatus, operation=EvtInfo_AutoCreatedDemEvent_FLS_E_COMPARE_FAILED.GetEventUdsStatus
        OpEventGetEventUdsStatus_GetEventUdsStatus_EvtInfo_AutoCreatedDemEvent_MyECU_6c1a0d52_FrDemCtrlTestResultRef: start-on-event=DemSatellite_0InternalBehavior/GetEventUdsStatus, operation=EvtInfo_AutoCreatedDemEvent_MyECU_6c1a0d52_FrDemCtrlTestResultRef.GetEventUdsStatus
        OpEventGetEventUdsStatus_GetEventUdsStatus_EvtInfo_AutoCreatedDemEvent_LIN_E_TIMEOUT: start-on-event=DemSatellite_0InternalBehavior/GetEventUdsStatus, operation=EvtInfo_AutoCreatedDemEvent_LIN_E_TIMEOUT.GetEventUdsStatus
        OpEventGetEventUdsStatus_GetEventUdsStatus_EvtInfo_AutoCreatedDemEvent_McuModuleConfiguration_MCU_E_CLOCK_FAILURE: start-on-event=DemSatellite_0InternalBehavior/GetEventUdsStatus, operation=EvtInfo_AutoCreatedDemEvent_McuModuleConfiguration_MCU_E_CLOCK_FAILURE.GetEventUdsStatus
        OpEventGetEventUdsStatus_GetEventUdsStatus_EvtInfo_AutoCreatedDemEvent_NVM_E_WRONG_BLOCK_ID: start-on-event=DemSatellite_0InternalBehavior/GetEventUdsStatus, operation=EvtInfo_AutoCreatedDemEvent_NVM_E_WRONG_BLOCK_ID.GetEventUdsStatus
        OpEventGetEventUdsStatus_GetEventUdsStatus_EvtInfo_AutoCreatedDemEvent_NVM_E_WRITE_PROTECTED: start-on-event=DemSatellite_0InternalBehavior/GetEventUdsStatus, operation=EvtInfo_AutoCreatedDemEvent_NVM_E_WRITE_PROTECTED.GetEventUdsStatus
        OpEventGetEventUdsStatus_GetEventUdsStatus_EvtInfo_AutoCreatedDemEvent_NVM_E_VERIFY_FAILED: start-on-event=DemSatellite_0InternalBehavior/GetEventUdsStatus, operation=EvtInfo_AutoCreatedDemEvent_NVM_E_VERIFY_FAILED.GetEventUdsStatus
        OpEventGetEventUdsStatus_GetEventUdsStatus_EvtInfo_AutoCreatedDemEvent_NVM_E_REQ_FAILED: start-on-event=DemSatellite_0InternalBehavior/GetEventUdsStatus, operation=EvtInfo_AutoCreatedDemEvent_NVM_E_REQ_FAILED.GetEventUdsStatus
        OpEventGetEventUdsStatus_GetEventUdsStatus_EvtInfo_AutoCreatedDemEvent_NVM_E_QUEUE_OVERFLOW: start-on-event=DemSatellite_0InternalBehavior/GetEventUdsStatus, operation=EvtInfo_AutoCreatedDemEvent_NVM_E_QUEUE_OVERFLOW.GetEventUdsStatus
        OpEventGetEventUdsStatus_GetEventUdsStatus_EvtInfo_AutoCreatedDemEvent_NVM_E_LOSS_OF_REDUNDANCY: start-on-event=DemSatellite_0InternalBehavior/GetEventUdsStatus, operation=EvtInfo_AutoCreatedDemEvent_NVM_E_LOSS_OF_REDUNDANCY.GetEventUdsStatus
        OpEventGetEventUdsStatus_GetEventUdsStatus_EvtInfo_AutoCreatedDemEvent_NVM_E_INTEGRITY_FAILED: start-on-event=DemSatellite_0InternalBehavior/GetEventUdsStatus, operation=EvtInfo_AutoCreatedDemEvent_NVM_E_INTEGRITY_FAILED.GetEventUdsStatus
        OpEventGetEventUdsStatus_GetEventUdsStatus_EvtInfo_AutoCreatedDemEvent_XFRM_E_MALFORMED_MESSAGE_2: start-on-event=DemSatellite_0InternalBehavior/GetEventUdsStatus, operation=EvtInfo_AutoCreatedDemEvent_XFRM_E_MALFORMED_MESSAGE_2.GetEventUdsStatus
        OpEventGetEventUdsStatus_GetEventUdsStatus_EvtInfo_AutoCreatedDemEvent_EEP_E_WRITE_FAILED_1: start-on-event=DemSatellite_0InternalBehavior/GetEventUdsStatus, operation=EvtInfo_AutoCreatedDemEvent_EEP_E_WRITE_FAILED_1.GetEventUdsStatus
        OpEventGetEventUdsStatus_GetEventUdsStatus_EvtInfo_AutoCreatedDemEvent_EEP_E_READ_FAILED_1: start-on-event=DemSatellite_0InternalBehavior/GetEventUdsStatus, operation=EvtInfo_AutoCreatedDemEvent_EEP_E_READ_FAILED_1.GetEventUdsStatus
        OpEventGetEventUdsStatus_GetEventUdsStatus_EvtInfo_AutoCreatedDemEvent_EEP_E_ERASE_FAILED_1: start-on-event=DemSatellite_0InternalBehavior/GetEventUdsStatus, operation=EvtInfo_AutoCreatedDemEvent_EEP_E_ERASE_FAILED_1.GetEventUdsStatus
        OpEventGetEventUdsStatus_GetEventUdsStatus_EvtInfo_AutoCreatedDemEvent_EEP_E_COMPARE_FAILED_1: start-on-event=DemSatellite_0InternalBehavior/GetEventUdsStatus, operation=EvtInfo_AutoCreatedDemEvent_EEP_E_COMPARE_FAILED_1.GetEventUdsStatus
        OpEventGetEventUdsStatus_GetEventUdsStatus_EvtInfo_AutoCreatedDemEvent_FLS_E_WRITE_FAILED_1: start-on-event=DemSatellite_0InternalBehavior/GetEventUdsStatus, operation=EvtInfo_AutoCreatedDemEvent_FLS_E_WRITE_FAILED_1.GetEventUdsStatus
        OpEventGetEventUdsStatus_GetEventUdsStatus_EvtInfo_AutoCreatedDemEvent_FLS_E_UNEXPECTED_FLASH_ID_1: start-on-event=DemSatellite_0InternalBehavior/GetEventUdsStatus, operation=EvtInfo_AutoCreatedDemEvent_FLS_E_UNEXPECTED_FLASH_ID_1.GetEventUdsStatus
        OpEventGetEventUdsStatus_GetEventUdsStatus_EvtInfo_AutoCreatedDemEvent_FLS_E_READ_FAILED_1: start-on-event=DemSatellite_0InternalBehavior/GetEventUdsStatus, operation=EvtInfo_AutoCreatedDemEvent_FLS_E_READ_FAILED_1.GetEventUdsStatus
        OpEventGetEventUdsStatus_GetEventUdsStatus_EvtInfo_AutoCreatedDemEvent_FLS_E_ERASE_FAILED_1: start-on-event=DemSatellite_0InternalBehavior/GetEventUdsStatus, operation=EvtInfo_AutoCreatedDemEvent_FLS_E_ERASE_FAILED_1.GetEventUdsStatus
        OpEventGetEventUdsStatus_GetEventUdsStatus_EvtInfo_AutoCreatedDemEvent_FLS_E_COMPARE_FAILED_1: start-on-event=DemSatellite_0InternalBehavior/GetEventUdsStatus, operation=EvtInfo_AutoCreatedDemEvent_FLS_E_COMPARE_FAILED_1.GetEventUdsStatus
        OpEventGetEventUdsStatus_GetEventUdsStatus_EvtInfo_AutoCreatedDemEvent_MyECU_6c1a0d52_FrDemCtrlTestResultRef_1: start-on-event=DemSatellite_0InternalBehavior/GetEventUdsStatus, operation=EvtInfo_AutoCreatedDemEvent_MyECU_6c1a0d52_FrDemCtrlTestResultRef_1.GetEventUdsStatus
        OpEventGetEventUdsStatus_GetEventUdsStatus_EvtInfo_AutoCreatedDemEvent_McuModuleConfiguration_MCU_E_CLOCK_FAILURE_1: start-on-event=DemSatellite_0InternalBehavior/GetEventUdsStatus, operation=EvtInfo_AutoCreatedDemEvent_McuModuleConfiguration_MCU_E_CLOCK_FAILURE_1.GetEventUdsStatus
        OpEventGetEventUdsStatus_GetEventUdsStatus_EvtInfo_AutoCreatedDemEvent_XCP_E_INIT_FAILED: start-on-event=DemSatellite_0InternalBehavior/GetEventUdsStatus, operation=EvtInfo_AutoCreatedDemEvent_XCP_E_INIT_FAILED.GetEventUdsStatus
        OpEventGetEventStatus_GetEventStatus_EvtInfo_AutoCreatedDemEvent_BswMConfig_BswMReportFailToDemRef: start-on-event=DemSatellite_0InternalBehavior/GetEventStatus, operation=EvtInfo_AutoCreatedDemEvent_BswMConfig_BswMReportFailToDemRef.GetEventStatus
        OpEventGetEventStatus_GetEventStatus_EvtInfo_AutoCreatedDemEvent_CHNL_346f2748_CANSM_E_MODE_REQUEST_TIMEOUT: start-on-event=DemSatellite_0InternalBehavior/GetEventStatus, operation=EvtInfo_AutoCreatedDemEvent_CHNL_346f2748_CANSM_E_MODE_REQUEST_TIMEOUT.GetEventStatus
        OpEventGetEventStatus_GetEventStatus_EvtInfo_AutoCreatedDemEvent_CHNL_346f2748_CANSM_E_BUS_OFF: start-on-event=DemSatellite_0InternalBehavior/GetEventStatus, operation=EvtInfo_AutoCreatedDemEvent_CHNL_346f2748_CANSM_E_BUS_OFF.GetEventStatus
        OpEventGetEventStatus_GetEventStatus_EvtInfo_AutoCreatedDemEvent_XFRM_E_MALFORMED_MESSAGE: start-on-event=DemSatellite_0InternalBehavior/GetEventStatus, operation=EvtInfo_AutoCreatedDemEvent_XFRM_E_MALFORMED_MESSAGE.GetEventStatus
        OpEventGetEventStatus_GetEventStatus_EvtInfo_AutoCreatedDemEvent_XFRM_E_MALFORMED_MESSAGE_1: start-on-event=DemSatellite_0InternalBehavior/GetEventStatus, operation=EvtInfo_AutoCreatedDemEvent_XFRM_E_MALFORMED_MESSAGE_1.GetEventStatus
        OpEventGetEventStatus_GetEventStatus_EvtInfo_AutoCreatedDemEvent_ECUM_E_RAM_CHECK_FAILED: start-on-event=DemSatellite_0InternalBehavior/GetEventStatus, operation=EvtInfo_AutoCreatedDemEvent_ECUM_E_RAM_CHECK_FAILED.GetEventStatus
        OpEventGetEventStatus_GetEventStatus_EvtInfo_AutoCreatedDemEvent_ECUM_E_IMPROPER_CALLER: start-on-event=DemSatellite_0InternalBehavior/GetEventStatus, operation=EvtInfo_AutoCreatedDemEvent_ECUM_E_IMPROPER_CALLER.GetEventStatus
        OpEventGetEventStatus_GetEventStatus_EvtInfo_AutoCreatedDemEvent_ECUM_E_CONFIGURATION_DATA_INCONSISTENT: start-on-event=DemSatellite_0InternalBehavior/GetEventStatus, operation=EvtInfo_AutoCreatedDemEvent_ECUM_E_CONFIGURATION_DATA_INCONSISTENT.GetEventStatus
        OpEventGetEventStatus_GetEventStatus_EvtInfo_AutoCreatedDemEvent_ECUM_E_ALL_RUN_REQUESTS_KILLED: start-on-event=DemSatellite_0InternalBehavior/GetEventStatus, operation=EvtInfo_AutoCreatedDemEvent_ECUM_E_ALL_RUN_REQUESTS_KILLED.GetEventStatus
        OpEventGetEventStatus_GetEventStatus_EvtInfo_AutoCreatedDemEvent_EEP_E_WRITE_FAILED: start-on-event=DemSatellite_0InternalBehavior/GetEventStatus, operation=EvtInfo_AutoCreatedDemEvent_EEP_E_WRITE_FAILED.GetEventStatus
        OpEventGetEventStatus_GetEventStatus_EvtInfo_AutoCreatedDemEvent_EEP_E_READ_FAILED: start-on-event=DemSatellite_0InternalBehavior/GetEventStatus, operation=EvtInfo_AutoCreatedDemEvent_EEP_E_READ_FAILED.GetEventStatus
        OpEventGetEventStatus_GetEventStatus_EvtInfo_AutoCreatedDemEvent_EEP_E_ERASE_FAILED: start-on-event=DemSatellite_0InternalBehavior/GetEventStatus, operation=EvtInfo_AutoCreatedDemEvent_EEP_E_ERASE_FAILED.GetEventStatus
        OpEventGetEventStatus_GetEventStatus_EvtInfo_AutoCreatedDemEvent_EEP_E_COMPARE_FAILED: start-on-event=DemSatellite_0InternalBehavior/GetEventStatus, operation=EvtInfo_AutoCreatedDemEvent_EEP_E_COMPARE_FAILED.GetEventStatus
        OpEventGetEventStatus_GetEventStatus_EvtInfo_AutoCreatedDemEvent_FLS_E_WRITE_FAILED: start-on-event=DemSatellite_0InternalBehavior/GetEventStatus, operation=EvtInfo_AutoCreatedDemEvent_FLS_E_WRITE_FAILED.GetEventStatus
        OpEventGetEventStatus_GetEventStatus_EvtInfo_AutoCreatedDemEvent_FLS_E_UNEXPECTED_FLASH_ID: start-on-event=DemSatellite_0InternalBehavior/GetEventStatus, operation=EvtInfo_AutoCreatedDemEvent_FLS_E_UNEXPECTED_FLASH_ID.GetEventStatus
        OpEventGetEventStatus_GetEventStatus_EvtInfo_AutoCreatedDemEvent_FLS_E_READ_FAILED: start-on-event=DemSatellite_0InternalBehavior/GetEventStatus, operation=EvtInfo_AutoCreatedDemEvent_FLS_E_READ_FAILED.GetEventStatus
        OpEventGetEventStatus_GetEventStatus_EvtInfo_AutoCreatedDemEvent_FLS_E_ERASE_FAILED: start-on-event=DemSatellite_0InternalBehavior/GetEventStatus, operation=EvtInfo_AutoCreatedDemEvent_FLS_E_ERASE_FAILED.GetEventStatus
        OpEventGetEventStatus_GetEventStatus_EvtInfo_AutoCreatedDemEvent_FLS_E_COMPARE_FAILED: start-on-event=DemSatellite_0InternalBehavior/GetEventStatus, operation=EvtInfo_AutoCreatedDemEvent_FLS_E_COMPARE_FAILED.GetEventStatus
        OpEventGetEventStatus_GetEventStatus_EvtInfo_AutoCreatedDemEvent_MyECU_6c1a0d52_FrDemCtrlTestResultRef: start-on-event=DemSatellite_0InternalBehavior/GetEventStatus, operation=EvtInfo_AutoCreatedDemEvent_MyECU_6c1a0d52_FrDemCtrlTestResultRef.GetEventStatus
        OpEventGetEventStatus_GetEventStatus_EvtInfo_AutoCreatedDemEvent_LIN_E_TIMEOUT: start-on-event=DemSatellite_0InternalBehavior/GetEventStatus, operation=EvtInfo_AutoCreatedDemEvent_LIN_E_TIMEOUT.GetEventStatus
        OpEventGetEventStatus_GetEventStatus_EvtInfo_AutoCreatedDemEvent_McuModuleConfiguration_MCU_E_CLOCK_FAILURE: start-on-event=DemSatellite_0InternalBehavior/GetEventStatus, operation=EvtInfo_AutoCreatedDemEvent_McuModuleConfiguration_MCU_E_CLOCK_FAILURE.GetEventStatus
        OpEventGetEventStatus_GetEventStatus_EvtInfo_AutoCreatedDemEvent_NVM_E_WRONG_BLOCK_ID: start-on-event=DemSatellite_0InternalBehavior/GetEventStatus, operation=EvtInfo_AutoCreatedDemEvent_NVM_E_WRONG_BLOCK_ID.GetEventStatus
        OpEventGetEventStatus_GetEventStatus_EvtInfo_AutoCreatedDemEvent_NVM_E_WRITE_PROTECTED: start-on-event=DemSatellite_0InternalBehavior/GetEventStatus, operation=EvtInfo_AutoCreatedDemEvent_NVM_E_WRITE_PROTECTED.GetEventStatus
        OpEventGetEventStatus_GetEventStatus_EvtInfo_AutoCreatedDemEvent_NVM_E_VERIFY_FAILED: start-on-event=DemSatellite_0InternalBehavior/GetEventStatus, operation=EvtInfo_AutoCreatedDemEvent_NVM_E_VERIFY_FAILED.GetEventStatus
        OpEventGetEventStatus_GetEventStatus_EvtInfo_AutoCreatedDemEvent_NVM_E_REQ_FAILED: start-on-event=DemSatellite_0InternalBehavior/GetEventStatus, operation=EvtInfo_AutoCreatedDemEvent_NVM_E_REQ_FAILED.GetEventStatus
        OpEventGetEventStatus_GetEventStatus_EvtInfo_AutoCreatedDemEvent_NVM_E_QUEUE_OVERFLOW: start-on-event=DemSatellite_0InternalBehavior/GetEventStatus, operation=EvtInfo_AutoCreatedDemEvent_NVM_E_QUEUE_OVERFLOW.GetEventStatus
        OpEventGetEventStatus_GetEventStatus_EvtInfo_AutoCreatedDemEvent_NVM_E_LOSS_OF_REDUNDANCY: start-on-event=DemSatellite_0InternalBehavior/GetEventStatus, operation=EvtInfo_AutoCreatedDemEvent_NVM_E_LOSS_OF_REDUNDANCY.GetEventStatus
        OpEventGetEventStatus_GetEventStatus_EvtInfo_AutoCreatedDemEvent_NVM_E_INTEGRITY_FAILED: start-on-event=DemSatellite_0InternalBehavior/GetEventStatus, operation=EvtInfo_AutoCreatedDemEvent_NVM_E_INTEGRITY_FAILED.GetEventStatus
        OpEventGetEventStatus_GetEventStatus_EvtInfo_AutoCreatedDemEvent_XFRM_E_MALFORMED_MESSAGE_2: start-on-event=DemSatellite_0InternalBehavior/GetEventStatus, operation=EvtInfo_AutoCreatedDemEvent_XFRM_E_MALFORMED_MESSAGE_2.GetEventStatus
        OpEventGetEventStatus_GetEventStatus_EvtInfo_AutoCreatedDemEvent_EEP_E_WRITE_FAILED_1: start-on-event=DemSatellite_0InternalBehavior/GetEventStatus, operation=EvtInfo_AutoCreatedDemEvent_EEP_E_WRITE_FAILED_1.GetEventStatus
        OpEventGetEventStatus_GetEventStatus_EvtInfo_AutoCreatedDemEvent_EEP_E_READ_FAILED_1: start-on-event=DemSatellite_0InternalBehavior/GetEventStatus, operation=EvtInfo_AutoCreatedDemEvent_EEP_E_READ_FAILED_1.GetEventStatus
        OpEventGetEventStatus_GetEventStatus_EvtInfo_AutoCreatedDemEvent_EEP_E_ERASE_FAILED_1: start-on-event=DemSatellite_0InternalBehavior/GetEventStatus, operation=EvtInfo_AutoCreatedDemEvent_EEP_E_ERASE_FAILED_1.GetEventStatus
        OpEventGetEventStatus_GetEventStatus_EvtInfo_AutoCreatedDemEvent_EEP_E_COMPARE_FAILED_1: start-on-event=DemSatellite_0InternalBehavior/GetEventStatus, operation=EvtInfo_AutoCreatedDemEvent_EEP_E_COMPARE_FAILED_1.GetEventStatus
        OpEventGetEventStatus_GetEventStatus_EvtInfo_AutoCreatedDemEvent_FLS_E_WRITE_FAILED_1: start-on-event=DemSatellite_0InternalBehavior/GetEventStatus, operation=EvtInfo_AutoCreatedDemEvent_FLS_E_WRITE_FAILED_1.GetEventStatus
        OpEventGetEventStatus_GetEventStatus_EvtInfo_AutoCreatedDemEvent_FLS_E_UNEXPECTED_FLASH_ID_1: start-on-event=DemSatellite_0InternalBehavior/GetEventStatus, operation=EvtInfo_AutoCreatedDemEvent_FLS_E_UNEXPECTED_FLASH_ID_1.GetEventStatus
        OpEventGetEventStatus_GetEventStatus_EvtInfo_AutoCreatedDemEvent_FLS_E_READ_FAILED_1: start-on-event=DemSatellite_0InternalBehavior/GetEventStatus, operation=EvtInfo_AutoCreatedDemEvent_FLS_E_READ_FAILED_1.GetEventStatus
        OpEventGetEventStatus_GetEventStatus_EvtInfo_AutoCreatedDemEvent_FLS_E_ERASE_FAILED_1: start-on-event=DemSatellite_0InternalBehavior/GetEventStatus, operation=EvtInfo_AutoCreatedDemEvent_FLS_E_ERASE_FAILED_1.GetEventStatus
        OpEventGetEventStatus_GetEventStatus_EvtInfo_AutoCreatedDemEvent_FLS_E_COMPARE_FAILED_1: start-on-event=DemSatellite_0InternalBehavior/GetEventStatus, operation=EvtInfo_AutoCreatedDemEvent_FLS_E_COMPARE_FAILED_1.GetEventStatus
        OpEventGetEventStatus_GetEventStatus_EvtInfo_AutoCreatedDemEvent_MyECU_6c1a0d52_FrDemCtrlTestResultRef_1: start-on-event=DemSatellite_0InternalBehavior/GetEventStatus, operation=EvtInfo_AutoCreatedDemEvent_MyECU_6c1a0d52_FrDemCtrlTestResultRef_1.GetEventStatus
        OpEventGetEventStatus_GetEventStatus_EvtInfo_AutoCreatedDemEvent_McuModuleConfiguration_MCU_E_CLOCK_FAILURE_1: start-on-event=DemSatellite_0InternalBehavior/GetEventStatus, operation=EvtInfo_AutoCreatedDemEvent_McuModuleConfiguration_MCU_E_CLOCK_FAILURE_1.GetEventStatus
        OpEventGetEventStatus_GetEventStatus_EvtInfo_AutoCreatedDemEvent_XCP_E_INIT_FAILED: start-on-event=DemSatellite_0InternalBehavior/GetEventStatus, operation=EvtInfo_AutoCreatedDemEvent_XCP_E_INIT_FAILED.GetEventStatus
        OpEventGetEventFailed_GetEventFailed_EvtInfo_AutoCreatedDemEvent_BswMConfig_BswMReportFailToDemRef: start-on-event=DemSatellite_0InternalBehavior/GetEventFailed, operation=EvtInfo_AutoCreatedDemEvent_BswMConfig_BswMReportFailToDemRef.GetEventFailed
        OpEventGetEventFailed_GetEventFailed_EvtInfo_AutoCreatedDemEvent_CHNL_346f2748_CANSM_E_MODE_REQUEST_TIMEOUT: start-on-event=DemSatellite_0InternalBehavior/GetEventFailed, operation=EvtInfo_AutoCreatedDemEvent_CHNL_346f2748_CANSM_E_MODE_REQUEST_TIMEOUT.GetEventFailed
        OpEventGetEventFailed_GetEventFailed_EvtInfo_AutoCreatedDemEvent_CHNL_346f2748_CANSM_E_BUS_OFF: start-on-event=DemSatellite_0InternalBehavior/GetEventFailed, operation=EvtInfo_AutoCreatedDemEvent_CHNL_346f2748_CANSM_E_BUS_OFF.GetEventFailed
        OpEventGetEventFailed_GetEventFailed_EvtInfo_AutoCreatedDemEvent_XFRM_E_MALFORMED_MESSAGE: start-on-event=DemSatellite_0InternalBehavior/GetEventFailed, operation=EvtInfo_AutoCreatedDemEvent_XFRM_E_MALFORMED_MESSAGE.GetEventFailed
        OpEventGetEventFailed_GetEventFailed_EvtInfo_AutoCreatedDemEvent_XFRM_E_MALFORMED_MESSAGE_1: start-on-event=DemSatellite_0InternalBehavior/GetEventFailed, operation=EvtInfo_AutoCreatedDemEvent_XFRM_E_MALFORMED_MESSAGE_1.GetEventFailed
        OpEventGetEventFailed_GetEventFailed_EvtInfo_AutoCreatedDemEvent_ECUM_E_RAM_CHECK_FAILED: start-on-event=DemSatellite_0InternalBehavior/GetEventFailed, operation=EvtInfo_AutoCreatedDemEvent_ECUM_E_RAM_CHECK_FAILED.GetEventFailed
        OpEventGetEventFailed_GetEventFailed_EvtInfo_AutoCreatedDemEvent_ECUM_E_IMPROPER_CALLER: start-on-event=DemSatellite_0InternalBehavior/GetEventFailed, operation=EvtInfo_AutoCreatedDemEvent_ECUM_E_IMPROPER_CALLER.GetEventFailed
        OpEventGetEventFailed_GetEventFailed_EvtInfo_AutoCreatedDemEvent_ECUM_E_CONFIGURATION_DATA_INCONSISTENT: start-on-event=DemSatellite_0InternalBehavior/GetEventFailed, operation=EvtInfo_AutoCreatedDemEvent_ECUM_E_CONFIGURATION_DATA_INCONSISTENT.GetEventFailed
        OpEventGetEventFailed_GetEventFailed_EvtInfo_AutoCreatedDemEvent_ECUM_E_ALL_RUN_REQUESTS_KILLED: start-on-event=DemSatellite_0InternalBehavior/GetEventFailed, operation=EvtInfo_AutoCreatedDemEvent_ECUM_E_ALL_RUN_REQUESTS_KILLED.GetEventFailed
        OpEventGetEventFailed_GetEventFailed_EvtInfo_AutoCreatedDemEvent_EEP_E_WRITE_FAILED: start-on-event=DemSatellite_0InternalBehavior/GetEventFailed, operation=EvtInfo_AutoCreatedDemEvent_EEP_E_WRITE_FAILED.GetEventFailed
        OpEventGetEventFailed_GetEventFailed_EvtInfo_AutoCreatedDemEvent_EEP_E_READ_FAILED: start-on-event=DemSatellite_0InternalBehavior/GetEventFailed, operation=EvtInfo_AutoCreatedDemEvent_EEP_E_READ_FAILED.GetEventFailed
        OpEventGetEventFailed_GetEventFailed_EvtInfo_AutoCreatedDemEvent_EEP_E_ERASE_FAILED: start-on-event=DemSatellite_0InternalBehavior/GetEventFailed, operation=EvtInfo_AutoCreatedDemEvent_EEP_E_ERASE_FAILED.GetEventFailed
        OpEventGetEventFailed_GetEventFailed_EvtInfo_AutoCreatedDemEvent_EEP_E_COMPARE_FAILED: start-on-event=DemSatellite_0InternalBehavior/GetEventFailed, operation=EvtInfo_AutoCreatedDemEvent_EEP_E_COMPARE_FAILED.GetEventFailed
        OpEventGetEventFailed_GetEventFailed_EvtInfo_AutoCreatedDemEvent_FLS_E_WRITE_FAILED: start-on-event=DemSatellite_0InternalBehavior/GetEventFailed, operation=EvtInfo_AutoCreatedDemEvent_FLS_E_WRITE_FAILED.GetEventFailed
        OpEventGetEventFailed_GetEventFailed_EvtInfo_AutoCreatedDemEvent_FLS_E_UNEXPECTED_FLASH_ID: start-on-event=DemSatellite_0InternalBehavior/GetEventFailed, operation=EvtInfo_AutoCreatedDemEvent_FLS_E_UNEXPECTED_FLASH_ID.GetEventFailed
        OpEventGetEventFailed_GetEventFailed_EvtInfo_AutoCreatedDemEvent_FLS_E_READ_FAILED: start-on-event=DemSatellite_0InternalBehavior/GetEventFailed, operation=EvtInfo_AutoCreatedDemEvent_FLS_E_READ_FAILED.GetEventFailed
        OpEventGetEventFailed_GetEventFailed_EvtInfo_AutoCreatedDemEvent_FLS_E_ERASE_FAILED: start-on-event=DemSatellite_0InternalBehavior/GetEventFailed, operation=EvtInfo_AutoCreatedDemEvent_FLS_E_ERASE_FAILED.GetEventFailed
        OpEventGetEventFailed_GetEventFailed_EvtInfo_AutoCreatedDemEvent_FLS_E_COMPARE_FAILED: start-on-event=DemSatellite_0InternalBehavior/GetEventFailed, operation=EvtInfo_AutoCreatedDemEvent_FLS_E_COMPARE_FAILED.GetEventFailed
        OpEventGetEventFailed_GetEventFailed_EvtInfo_AutoCreatedDemEvent_MyECU_6c1a0d52_FrDemCtrlTestResultRef: start-on-event=DemSatellite_0InternalBehavior/GetEventFailed, operation=EvtInfo_AutoCreatedDemEvent_MyECU_6c1a0d52_FrDemCtrlTestResultRef.GetEventFailed
        OpEventGetEventFailed_GetEventFailed_EvtInfo_AutoCreatedDemEvent_LIN_E_TIMEOUT: start-on-event=DemSatellite_0InternalBehavior/GetEventFailed, operation=EvtInfo_AutoCreatedDemEvent_LIN_E_TIMEOUT.GetEventFailed
        OpEventGetEventFailed_GetEventFailed_EvtInfo_AutoCreatedDemEvent_McuModuleConfiguration_MCU_E_CLOCK_FAILURE: start-on-event=DemSatellite_0InternalBehavior/GetEventFailed, operation=EvtInfo_AutoCreatedDemEvent_McuModuleConfiguration_MCU_E_CLOCK_FAILURE.GetEventFailed
        OpEventGetEventFailed_GetEventFailed_EvtInfo_AutoCreatedDemEvent_NVM_E_WRONG_BLOCK_ID: start-on-event=DemSatellite_0InternalBehavior/GetEventFailed, operation=EvtInfo_AutoCreatedDemEvent_NVM_E_WRONG_BLOCK_ID.GetEventFailed
        OpEventGetEventFailed_GetEventFailed_EvtInfo_AutoCreatedDemEvent_NVM_E_WRITE_PROTECTED: start-on-event=DemSatellite_0InternalBehavior/GetEventFailed, operation=EvtInfo_AutoCreatedDemEvent_NVM_E_WRITE_PROTECTED.GetEventFailed
        OpEventGetEventFailed_GetEventFailed_EvtInfo_AutoCreatedDemEvent_NVM_E_VERIFY_FAILED: start-on-event=DemSatellite_0InternalBehavior/GetEventFailed, operation=EvtInfo_AutoCreatedDemEvent_NVM_E_VERIFY_FAILED.GetEventFailed
        OpEventGetEventFailed_GetEventFailed_EvtInfo_AutoCreatedDemEvent_NVM_E_REQ_FAILED: start-on-event=DemSatellite_0InternalBehavior/GetEventFailed, operation=EvtInfo_AutoCreatedDemEvent_NVM_E_REQ_FAILED.GetEventFailed
        OpEventGetEventFailed_GetEventFailed_EvtInfo_AutoCreatedDemEvent_NVM_E_QUEUE_OVERFLOW: start-on-event=DemSatellite_0InternalBehavior/GetEventFailed, operation=EvtInfo_AutoCreatedDemEvent_NVM_E_QUEUE_OVERFLOW.GetEventFailed
        OpEventGetEventFailed_GetEventFailed_EvtInfo_AutoCreatedDemEvent_NVM_E_LOSS_OF_REDUNDANCY: start-on-event=DemSatellite_0InternalBehavior/GetEventFailed, operation=EvtInfo_AutoCreatedDemEvent_NVM_E_LOSS_OF_REDUNDANCY.GetEventFailed
        OpEventGetEventFailed_GetEventFailed_EvtInfo_AutoCreatedDemEvent_NVM_E_INTEGRITY_FAILED: start-on-event=DemSatellite_0InternalBehavior/GetEventFailed, operation=EvtInfo_AutoCreatedDemEvent_NVM_E_INTEGRITY_FAILED.GetEventFailed
        OpEventGetEventFailed_GetEventFailed_EvtInfo_AutoCreatedDemEvent_XFRM_E_MALFORMED_MESSAGE_2: start-on-event=DemSatellite_0InternalBehavior/GetEventFailed, operation=EvtInfo_AutoCreatedDemEvent_XFRM_E_MALFORMED_MESSAGE_2.GetEventFailed
        OpEventGetEventFailed_GetEventFailed_EvtInfo_AutoCreatedDemEvent_EEP_E_WRITE_FAILED_1: start-on-event=DemSatellite_0InternalBehavior/GetEventFailed, operation=EvtInfo_AutoCreatedDemEvent_EEP_E_WRITE_FAILED_1.GetEventFailed
        OpEventGetEventFailed_GetEventFailed_EvtInfo_AutoCreatedDemEvent_EEP_E_READ_FAILED_1: start-on-event=DemSatellite_0InternalBehavior/GetEventFailed, operation=EvtInfo_AutoCreatedDemEvent_EEP_E_READ_FAILED_1.GetEventFailed
        OpEventGetEventFailed_GetEventFailed_EvtInfo_AutoCreatedDemEvent_EEP_E_ERASE_FAILED_1: start-on-event=DemSatellite_0InternalBehavior/GetEventFailed, operation=EvtInfo_AutoCreatedDemEvent_EEP_E_ERASE_FAILED_1.GetEventFailed
        OpEventGetEventFailed_GetEventFailed_EvtInfo_AutoCreatedDemEvent_EEP_E_COMPARE_FAILED_1: start-on-event=DemSatellite_0InternalBehavior/GetEventFailed, operation=EvtInfo_AutoCreatedDemEvent_EEP_E_COMPARE_FAILED_1.GetEventFailed
        OpEventGetEventFailed_GetEventFailed_EvtInfo_AutoCreatedDemEvent_FLS_E_WRITE_FAILED_1: start-on-event=DemSatellite_0InternalBehavior/GetEventFailed, operation=EvtInfo_AutoCreatedDemEvent_FLS_E_WRITE_FAILED_1.GetEventFailed
        OpEventGetEventFailed_GetEventFailed_EvtInfo_AutoCreatedDemEvent_FLS_E_UNEXPECTED_FLASH_ID_1: start-on-event=DemSatellite_0InternalBehavior/GetEventFailed, operation=EvtInfo_AutoCreatedDemEvent_FLS_E_UNEXPECTED_FLASH_ID_1.GetEventFailed
        OpEventGetEventFailed_GetEventFailed_EvtInfo_AutoCreatedDemEvent_FLS_E_READ_FAILED_1: start-on-event=DemSatellite_0InternalBehavior/GetEventFailed, operation=EvtInfo_AutoCreatedDemEvent_FLS_E_READ_FAILED_1.GetEventFailed
        OpEventGetEventFailed_GetEventFailed_EvtInfo_AutoCreatedDemEvent_FLS_E_ERASE_FAILED_1: start-on-event=DemSatellite_0InternalBehavior/GetEventFailed, operation=EvtInfo_AutoCreatedDemEvent_FLS_E_ERASE_FAILED_1.GetEventFailed
        OpEventGetEventFailed_GetEventFailed_EvtInfo_AutoCreatedDemEvent_FLS_E_COMPARE_FAILED_1: start-on-event=DemSatellite_0InternalBehavior/GetEventFailed, operation=EvtInfo_AutoCreatedDemEvent_FLS_E_COMPARE_FAILED_1.GetEventFailed
        OpEventGetEventFailed_GetEventFailed_EvtInfo_AutoCreatedDemEvent_MyECU_6c1a0d52_FrDemCtrlTestResultRef_1: start-on-event=DemSatellite_0InternalBehavior/GetEventFailed, operation=EvtInfo_AutoCreatedDemEvent_MyECU_6c1a0d52_FrDemCtrlTestResultRef_1.GetEventFailed
        OpEventGetEventFailed_GetEventFailed_EvtInfo_AutoCreatedDemEvent_McuModuleConfiguration_MCU_E_CLOCK_FAILURE_1: start-on-event=DemSatellite_0InternalBehavior/GetEventFailed, operation=EvtInfo_AutoCreatedDemEvent_McuModuleConfiguration_MCU_E_CLOCK_FAILURE_1.GetEventFailed
        OpEventGetEventFailed_GetEventFailed_EvtInfo_AutoCreatedDemEvent_XCP_E_INIT_FAILED: start-on-event=DemSatellite_0InternalBehavior/GetEventFailed, operation=EvtInfo_AutoCreatedDemEvent_XCP_E_INIT_FAILED.GetEventFailed
        OpEventGetEventTested_GetEventTested_EvtInfo_AutoCreatedDemEvent_BswMConfig_BswMReportFailToDemRef: start-on-event=DemSatellite_0InternalBehavior/GetEventTested, operation=EvtInfo_AutoCreatedDemEvent_BswMConfig_BswMReportFailToDemRef.GetEventTested
        OpEventGetEventTested_GetEventTested_EvtInfo_AutoCreatedDemEvent_CHNL_346f2748_CANSM_E_MODE_REQUEST_TIMEOUT: start-on-event=DemSatellite_0InternalBehavior/GetEventTested, operation=EvtInfo_AutoCreatedDemEvent_CHNL_346f2748_CANSM_E_MODE_REQUEST_TIMEOUT.GetEventTested
        OpEventGetEventTested_GetEventTested_EvtInfo_AutoCreatedDemEvent_CHNL_346f2748_CANSM_E_BUS_OFF: start-on-event=DemSatellite_0InternalBehavior/GetEventTested, operation=EvtInfo_AutoCreatedDemEvent_CHNL_346f2748_CANSM_E_BUS_OFF.GetEventTested
        OpEventGetEventTested_GetEventTested_EvtInfo_AutoCreatedDemEvent_XFRM_E_MALFORMED_MESSAGE: start-on-event=DemSatellite_0InternalBehavior/GetEventTested, operation=EvtInfo_AutoCreatedDemEvent_XFRM_E_MALFORMED_MESSAGE.GetEventTested
        OpEventGetEventTested_GetEventTested_EvtInfo_AutoCreatedDemEvent_XFRM_E_MALFORMED_MESSAGE_1: start-on-event=DemSatellite_0InternalBehavior/GetEventTested, operation=EvtInfo_AutoCreatedDemEvent_XFRM_E_MALFORMED_MESSAGE_1.GetEventTested
        OpEventGetEventTested_GetEventTested_EvtInfo_AutoCreatedDemEvent_ECUM_E_RAM_CHECK_FAILED: start-on-event=DemSatellite_0InternalBehavior/GetEventTested, operation=EvtInfo_AutoCreatedDemEvent_ECUM_E_RAM_CHECK_FAILED.GetEventTested
        OpEventGetEventTested_GetEventTested_EvtInfo_AutoCreatedDemEvent_ECUM_E_IMPROPER_CALLER: start-on-event=DemSatellite_0InternalBehavior/GetEventTested, operation=EvtInfo_AutoCreatedDemEvent_ECUM_E_IMPROPER_CALLER.GetEventTested
        OpEventGetEventTested_GetEventTested_EvtInfo_AutoCreatedDemEvent_ECUM_E_CONFIGURATION_DATA_INCONSISTENT: start-on-event=DemSatellite_0InternalBehavior/GetEventTested, operation=EvtInfo_AutoCreatedDemEvent_ECUM_E_CONFIGURATION_DATA_INCONSISTENT.GetEventTested
        OpEventGetEventTested_GetEventTested_EvtInfo_AutoCreatedDemEvent_ECUM_E_ALL_RUN_REQUESTS_KILLED: start-on-event=DemSatellite_0InternalBehavior/GetEventTested, operation=EvtInfo_AutoCreatedDemEvent_ECUM_E_ALL_RUN_REQUESTS_KILLED.GetEventTested
        OpEventGetEventTested_GetEventTested_EvtInfo_AutoCreatedDemEvent_EEP_E_WRITE_FAILED: start-on-event=DemSatellite_0InternalBehavior/GetEventTested, operation=EvtInfo_AutoCreatedDemEvent_EEP_E_WRITE_FAILED.GetEventTested
        OpEventGetEventTested_GetEventTested_EvtInfo_AutoCreatedDemEvent_EEP_E_READ_FAILED: start-on-event=DemSatellite_0InternalBehavior/GetEventTested, operation=EvtInfo_AutoCreatedDemEvent_EEP_E_READ_FAILED.GetEventTested
        OpEventGetEventTested_GetEventTested_EvtInfo_AutoCreatedDemEvent_EEP_E_ERASE_FAILED: start-on-event=DemSatellite_0InternalBehavior/GetEventTested, operation=EvtInfo_AutoCreatedDemEvent_EEP_E_ERASE_FAILED.GetEventTested
        OpEventGetEventTested_GetEventTested_EvtInfo_AutoCreatedDemEvent_EEP_E_COMPARE_FAILED: start-on-event=DemSatellite_0InternalBehavior/GetEventTested, operation=EvtInfo_AutoCreatedDemEvent_EEP_E_COMPARE_FAILED.GetEventTested
        OpEventGetEventTested_GetEventTested_EvtInfo_AutoCreatedDemEvent_FLS_E_WRITE_FAILED: start-on-event=DemSatellite_0InternalBehavior/GetEventTested, operation=EvtInfo_AutoCreatedDemEvent_FLS_E_WRITE_FAILED.GetEventTested
        OpEventGetEventTested_GetEventTested_EvtInfo_AutoCreatedDemEvent_FLS_E_UNEXPECTED_FLASH_ID: start-on-event=DemSatellite_0InternalBehavior/GetEventTested, operation=EvtInfo_AutoCreatedDemEvent_FLS_E_UNEXPECTED_FLASH_ID.GetEventTested
        OpEventGetEventTested_GetEventTested_EvtInfo_AutoCreatedDemEvent_FLS_E_READ_FAILED: start-on-event=DemSatellite_0InternalBehavior/GetEventTested, operation=EvtInfo_AutoCreatedDemEvent_FLS_E_READ_FAILED.GetEventTested
        OpEventGetEventTested_GetEventTested_EvtInfo_AutoCreatedDemEvent_FLS_E_ERASE_FAILED: start-on-event=DemSatellite_0InternalBehavior/GetEventTested, operation=EvtInfo_AutoCreatedDemEvent_FLS_E_ERASE_FAILED.GetEventTested
        OpEventGetEventTested_GetEventTested_EvtInfo_AutoCreatedDemEvent_FLS_E_COMPARE_FAILED: start-on-event=DemSatellite_0InternalBehavior/GetEventTested, operation=EvtInfo_AutoCreatedDemEvent_FLS_E_COMPARE_FAILED.GetEventTested
        OpEventGetEventTested_GetEventTested_EvtInfo_AutoCreatedDemEvent_MyECU_6c1a0d52_FrDemCtrlTestResultRef: start-on-event=DemSatellite_0InternalBehavior/GetEventTested, operation=EvtInfo_AutoCreatedDemEvent_MyECU_6c1a0d52_FrDemCtrlTestResultRef.GetEventTested
        OpEventGetEventTested_GetEventTested_EvtInfo_AutoCreatedDemEvent_LIN_E_TIMEOUT: start-on-event=DemSatellite_0InternalBehavior/GetEventTested, operation=EvtInfo_AutoCreatedDemEvent_LIN_E_TIMEOUT.GetEventTested
        OpEventGetEventTested_GetEventTested_EvtInfo_AutoCreatedDemEvent_McuModuleConfiguration_MCU_E_CLOCK_FAILURE: start-on-event=DemSatellite_0InternalBehavior/GetEventTested, operation=EvtInfo_AutoCreatedDemEvent_McuModuleConfiguration_MCU_E_CLOCK_FAILURE.GetEventTested
        OpEventGetEventTested_GetEventTested_EvtInfo_AutoCreatedDemEvent_NVM_E_WRONG_BLOCK_ID: start-on-event=DemSatellite_0InternalBehavior/GetEventTested, operation=EvtInfo_AutoCreatedDemEvent_NVM_E_WRONG_BLOCK_ID.GetEventTested
        OpEventGetEventTested_GetEventTested_EvtInfo_AutoCreatedDemEvent_NVM_E_WRITE_PROTECTED: start-on-event=DemSatellite_0InternalBehavior/GetEventTested, operation=EvtInfo_AutoCreatedDemEvent_NVM_E_WRITE_PROTECTED.GetEventTested
        OpEventGetEventTested_GetEventTested_EvtInfo_AutoCreatedDemEvent_NVM_E_VERIFY_FAILED: start-on-event=DemSatellite_0InternalBehavior/GetEventTested, operation=EvtInfo_AutoCreatedDemEvent_NVM_E_VERIFY_FAILED.GetEventTested
        OpEventGetEventTested_GetEventTested_EvtInfo_AutoCreatedDemEvent_NVM_E_REQ_FAILED: start-on-event=DemSatellite_0InternalBehavior/GetEventTested, operation=EvtInfo_AutoCreatedDemEvent_NVM_E_REQ_FAILED.GetEventTested
        OpEventGetEventTested_GetEventTested_EvtInfo_AutoCreatedDemEvent_NVM_E_QUEUE_OVERFLOW: start-on-event=DemSatellite_0InternalBehavior/GetEventTested, operation=EvtInfo_AutoCreatedDemEvent_NVM_E_QUEUE_OVERFLOW.GetEventTested
        OpEventGetEventTested_GetEventTested_EvtInfo_AutoCreatedDemEvent_NVM_E_LOSS_OF_REDUNDANCY: start-on-event=DemSatellite_0InternalBehavior/GetEventTested, operation=EvtInfo_AutoCreatedDemEvent_NVM_E_LOSS_OF_REDUNDANCY.GetEventTested
        OpEventGetEventTested_GetEventTested_EvtInfo_AutoCreatedDemEvent_NVM_E_INTEGRITY_FAILED: start-on-event=DemSatellite_0InternalBehavior/GetEventTested, operation=EvtInfo_AutoCreatedDemEvent_NVM_E_INTEGRITY_FAILED.GetEventTested
        OpEventGetEventTested_GetEventTested_EvtInfo_AutoCreatedDemEvent_XFRM_E_MALFORMED_MESSAGE_2: start-on-event=DemSatellite_0InternalBehavior/GetEventTested, operation=EvtInfo_AutoCreatedDemEvent_XFRM_E_MALFORMED_MESSAGE_2.GetEventTested
        OpEventGetEventTested_GetEventTested_EvtInfo_AutoCreatedDemEvent_EEP_E_WRITE_FAILED_1: start-on-event=DemSatellite_0InternalBehavior/GetEventTested, operation=EvtInfo_AutoCreatedDemEvent_EEP_E_WRITE_FAILED_1.GetEventTested
        OpEventGetEventTested_GetEventTested_EvtInfo_AutoCreatedDemEvent_EEP_E_READ_FAILED_1: start-on-event=DemSatellite_0InternalBehavior/GetEventTested, operation=EvtInfo_AutoCreatedDemEvent_EEP_E_READ_FAILED_1.GetEventTested
        OpEventGetEventTested_GetEventTested_EvtInfo_AutoCreatedDemEvent_EEP_E_ERASE_FAILED_1: start-on-event=DemSatellite_0InternalBehavior/GetEventTested, operation=EvtInfo_AutoCreatedDemEvent_EEP_E_ERASE_FAILED_1.GetEventTested
        OpEventGetEventTested_GetEventTested_EvtInfo_AutoCreatedDemEvent_EEP_E_COMPARE_FAILED_1: start-on-event=DemSatellite_0InternalBehavior/GetEventTested, operation=EvtInfo_AutoCreatedDemEvent_EEP_E_COMPARE_FAILED_1.GetEventTested
        OpEventGetEventTested_GetEventTested_EvtInfo_AutoCreatedDemEvent_FLS_E_WRITE_FAILED_1: start-on-event=DemSatellite_0InternalBehavior/GetEventTested, operation=EvtInfo_AutoCreatedDemEvent_FLS_E_WRITE_FAILED_1.GetEventTested
        OpEventGetEventTested_GetEventTested_EvtInfo_AutoCreatedDemEvent_FLS_E_UNEXPECTED_FLASH_ID_1: start-on-event=DemSatellite_0InternalBehavior/GetEventTested, operation=EvtInfo_AutoCreatedDemEvent_FLS_E_UNEXPECTED_FLASH_ID_1.GetEventTested
        OpEventGetEventTested_GetEventTested_EvtInfo_AutoCreatedDemEvent_FLS_E_READ_FAILED_1: start-on-event=DemSatellite_0InternalBehavior/GetEventTested, operation=EvtInfo_AutoCreatedDemEvent_FLS_E_READ_FAILED_1.GetEventTested
        OpEventGetEventTested_GetEventTested_EvtInfo_AutoCreatedDemEvent_FLS_E_ERASE_FAILED_1: start-on-event=DemSatellite_0InternalBehavior/GetEventTested, operation=EvtInfo_AutoCreatedDemEvent_FLS_E_ERASE_FAILED_1.GetEventTested
        OpEventGetEventTested_GetEventTested_EvtInfo_AutoCreatedDemEvent_FLS_E_COMPARE_FAILED_1: start-on-event=DemSatellite_0InternalBehavior/GetEventTested, operation=EvtInfo_AutoCreatedDemEvent_FLS_E_COMPARE_FAILED_1.GetEventTested
        OpEventGetEventTested_GetEventTested_EvtInfo_AutoCreatedDemEvent_MyECU_6c1a0d52_FrDemCtrlTestResultRef_1: start-on-event=DemSatellite_0InternalBehavior/GetEventTested, operation=EvtInfo_AutoCreatedDemEvent_MyECU_6c1a0d52_FrDemCtrlTestResultRef_1.GetEventTested
        OpEventGetEventTested_GetEventTested_EvtInfo_AutoCreatedDemEvent_McuModuleConfiguration_MCU_E_CLOCK_FAILURE_1: start-on-event=DemSatellite_0InternalBehavior/GetEventTested, operation=EvtInfo_AutoCreatedDemEvent_McuModuleConfiguration_MCU_E_CLOCK_FAILURE_1.GetEventTested
        OpEventGetEventTested_GetEventTested_EvtInfo_AutoCreatedDemEvent_XCP_E_INIT_FAILED: start-on-event=DemSatellite_0InternalBehavior/GetEventTested, operation=EvtInfo_AutoCreatedDemEvent_XCP_E_INIT_FAILED.GetEventTested
        OpEventGetDTCOfEvent_GetDTCOfEvent_EvtInfo_AutoCreatedDemEvent_BswMConfig_BswMReportFailToDemRef: start-on-event=DemSatellite_0InternalBehavior/GetDTCOfEvent, operation=EvtInfo_AutoCreatedDemEvent_BswMConfig_BswMReportFailToDemRef.GetDTCOfEvent
        OpEventGetDTCOfEvent_GetDTCOfEvent_EvtInfo_AutoCreatedDemEvent_CHNL_346f2748_CANSM_E_MODE_REQUEST_TIMEOUT: start-on-event=DemSatellite_0InternalBehavior/GetDTCOfEvent, operation=EvtInfo_AutoCreatedDemEvent_CHNL_346f2748_CANSM_E_MODE_REQUEST_TIMEOUT.GetDTCOfEvent
        OpEventGetDTCOfEvent_GetDTCOfEvent_EvtInfo_AutoCreatedDemEvent_CHNL_346f2748_CANSM_E_BUS_OFF: start-on-event=DemSatellite_0InternalBehavior/GetDTCOfEvent, operation=EvtInfo_AutoCreatedDemEvent_CHNL_346f2748_CANSM_E_BUS_OFF.GetDTCOfEvent
        OpEventGetDTCOfEvent_GetDTCOfEvent_EvtInfo_AutoCreatedDemEvent_XFRM_E_MALFORMED_MESSAGE: start-on-event=DemSatellite_0InternalBehavior/GetDTCOfEvent, operation=EvtInfo_AutoCreatedDemEvent_XFRM_E_MALFORMED_MESSAGE.GetDTCOfEvent
        OpEventGetDTCOfEvent_GetDTCOfEvent_EvtInfo_AutoCreatedDemEvent_XFRM_E_MALFORMED_MESSAGE_1: start-on-event=DemSatellite_0InternalBehavior/GetDTCOfEvent, operation=EvtInfo_AutoCreatedDemEvent_XFRM_E_MALFORMED_MESSAGE_1.GetDTCOfEvent
        OpEventGetDTCOfEvent_GetDTCOfEvent_EvtInfo_AutoCreatedDemEvent_ECUM_E_RAM_CHECK_FAILED: start-on-event=DemSatellite_0InternalBehavior/GetDTCOfEvent, operation=EvtInfo_AutoCreatedDemEvent_ECUM_E_RAM_CHECK_FAILED.GetDTCOfEvent
        OpEventGetDTCOfEvent_GetDTCOfEvent_EvtInfo_AutoCreatedDemEvent_ECUM_E_IMPROPER_CALLER: start-on-event=DemSatellite_0InternalBehavior/GetDTCOfEvent, operation=EvtInfo_AutoCreatedDemEvent_ECUM_E_IMPROPER_CALLER.GetDTCOfEvent
        OpEventGetDTCOfEvent_GetDTCOfEvent_EvtInfo_AutoCreatedDemEvent_ECUM_E_CONFIGURATION_DATA_INCONSISTENT: start-on-event=DemSatellite_0InternalBehavior/GetDTCOfEvent, operation=EvtInfo_AutoCreatedDemEvent_ECUM_E_CONFIGURATION_DATA_INCONSISTENT.GetDTCOfEvent
        OpEventGetDTCOfEvent_GetDTCOfEvent_EvtInfo_AutoCreatedDemEvent_ECUM_E_ALL_RUN_REQUESTS_KILLED: start-on-event=DemSatellite_0InternalBehavior/GetDTCOfEvent, operation=EvtInfo_AutoCreatedDemEvent_ECUM_E_ALL_RUN_REQUESTS_KILLED.GetDTCOfEvent
        OpEventGetDTCOfEvent_GetDTCOfEvent_EvtInfo_AutoCreatedDemEvent_EEP_E_WRITE_FAILED: start-on-event=DemSatellite_0InternalBehavior/GetDTCOfEvent, operation=EvtInfo_AutoCreatedDemEvent_EEP_E_WRITE_FAILED.GetDTCOfEvent
        OpEventGetDTCOfEvent_GetDTCOfEvent_EvtInfo_AutoCreatedDemEvent_EEP_E_READ_FAILED: start-on-event=DemSatellite_0InternalBehavior/GetDTCOfEvent, operation=EvtInfo_AutoCreatedDemEvent_EEP_E_READ_FAILED.GetDTCOfEvent
        OpEventGetDTCOfEvent_GetDTCOfEvent_EvtInfo_AutoCreatedDemEvent_EEP_E_ERASE_FAILED: start-on-event=DemSatellite_0InternalBehavior/GetDTCOfEvent, operation=EvtInfo_AutoCreatedDemEvent_EEP_E_ERASE_FAILED.GetDTCOfEvent
        OpEventGetDTCOfEvent_GetDTCOfEvent_EvtInfo_AutoCreatedDemEvent_EEP_E_COMPARE_FAILED: start-on-event=DemSatellite_0InternalBehavior/GetDTCOfEvent, operation=EvtInfo_AutoCreatedDemEvent_EEP_E_COMPARE_FAILED.GetDTCOfEvent
        OpEventGetDTCOfEvent_GetDTCOfEvent_EvtInfo_AutoCreatedDemEvent_FLS_E_WRITE_FAILED: start-on-event=DemSatellite_0InternalBehavior/GetDTCOfEvent, operation=EvtInfo_AutoCreatedDemEvent_FLS_E_WRITE_FAILED.GetDTCOfEvent
        OpEventGetDTCOfEvent_GetDTCOfEvent_EvtInfo_AutoCreatedDemEvent_FLS_E_UNEXPECTED_FLASH_ID: start-on-event=DemSatellite_0InternalBehavior/GetDTCOfEvent, operation=EvtInfo_AutoCreatedDemEvent_FLS_E_UNEXPECTED_FLASH_ID.GetDTCOfEvent
        OpEventGetDTCOfEvent_GetDTCOfEvent_EvtInfo_AutoCreatedDemEvent_FLS_E_READ_FAILED: start-on-event=DemSatellite_0InternalBehavior/GetDTCOfEvent, operation=EvtInfo_AutoCreatedDemEvent_FLS_E_READ_FAILED.GetDTCOfEvent
        OpEventGetDTCOfEvent_GetDTCOfEvent_EvtInfo_AutoCreatedDemEvent_FLS_E_ERASE_FAILED: start-on-event=DemSatellite_0InternalBehavior/GetDTCOfEvent, operation=EvtInfo_AutoCreatedDemEvent_FLS_E_ERASE_FAILED.GetDTCOfEvent
        OpEventGetDTCOfEvent_GetDTCOfEvent_EvtInfo_AutoCreatedDemEvent_FLS_E_COMPARE_FAILED: start-on-event=DemSatellite_0InternalBehavior/GetDTCOfEvent, operation=EvtInfo_AutoCreatedDemEvent_FLS_E_COMPARE_FAILED.GetDTCOfEvent
        OpEventGetDTCOfEvent_GetDTCOfEvent_EvtInfo_AutoCreatedDemEvent_MyECU_6c1a0d52_FrDemCtrlTestResultRef: start-on-event=DemSatellite_0InternalBehavior/GetDTCOfEvent, operation=EvtInfo_AutoCreatedDemEvent_MyECU_6c1a0d52_FrDemCtrlTestResultRef.GetDTCOfEvent
        OpEventGetDTCOfEvent_GetDTCOfEvent_EvtInfo_AutoCreatedDemEvent_LIN_E_TIMEOUT: start-on-event=DemSatellite_0InternalBehavior/GetDTCOfEvent, operation=EvtInfo_AutoCreatedDemEvent_LIN_E_TIMEOUT.GetDTCOfEvent
        OpEventGetDTCOfEvent_GetDTCOfEvent_EvtInfo_AutoCreatedDemEvent_McuModuleConfiguration_MCU_E_CLOCK_FAILURE: start-on-event=DemSatellite_0InternalBehavior/GetDTCOfEvent, operation=EvtInfo_AutoCreatedDemEvent_McuModuleConfiguration_MCU_E_CLOCK_FAILURE.GetDTCOfEvent
        OpEventGetDTCOfEvent_GetDTCOfEvent_EvtInfo_AutoCreatedDemEvent_NVM_E_WRONG_BLOCK_ID: start-on-event=DemSatellite_0InternalBehavior/GetDTCOfEvent, operation=EvtInfo_AutoCreatedDemEvent_NVM_E_WRONG_BLOCK_ID.GetDTCOfEvent
        OpEventGetDTCOfEvent_GetDTCOfEvent_EvtInfo_AutoCreatedDemEvent_NVM_E_WRITE_PROTECTED: start-on-event=DemSatellite_0InternalBehavior/GetDTCOfEvent, operation=EvtInfo_AutoCreatedDemEvent_NVM_E_WRITE_PROTECTED.GetDTCOfEvent
        OpEventGetDTCOfEvent_GetDTCOfEvent_EvtInfo_AutoCreatedDemEvent_NVM_E_VERIFY_FAILED: start-on-event=DemSatellite_0InternalBehavior/GetDTCOfEvent, operation=EvtInfo_AutoCreatedDemEvent_NVM_E_VERIFY_FAILED.GetDTCOfEvent
        OpEventGetDTCOfEvent_GetDTCOfEvent_EvtInfo_AutoCreatedDemEvent_NVM_E_REQ_FAILED: start-on-event=DemSatellite_0InternalBehavior/GetDTCOfEvent, operation=EvtInfo_AutoCreatedDemEvent_NVM_E_REQ_FAILED.GetDTCOfEvent
        OpEventGetDTCOfEvent_GetDTCOfEvent_EvtInfo_AutoCreatedDemEvent_NVM_E_QUEUE_OVERFLOW: start-on-event=DemSatellite_0InternalBehavior/GetDTCOfEvent, operation=EvtInfo_AutoCreatedDemEvent_NVM_E_QUEUE_OVERFLOW.GetDTCOfEvent
        OpEventGetDTCOfEvent_GetDTCOfEvent_EvtInfo_AutoCreatedDemEvent_NVM_E_LOSS_OF_REDUNDANCY: start-on-event=DemSatellite_0InternalBehavior/GetDTCOfEvent, operation=EvtInfo_AutoCreatedDemEvent_NVM_E_LOSS_OF_REDUNDANCY.GetDTCOfEvent
        OpEventGetDTCOfEvent_GetDTCOfEvent_EvtInfo_AutoCreatedDemEvent_NVM_E_INTEGRITY_FAILED: start-on-event=DemSatellite_0InternalBehavior/GetDTCOfEvent, operation=EvtInfo_AutoCreatedDemEvent_NVM_E_INTEGRITY_FAILED.GetDTCOfEvent
        OpEventGetDTCOfEvent_GetDTCOfEvent_EvtInfo_AutoCreatedDemEvent_XFRM_E_MALFORMED_MESSAGE_2: start-on-event=DemSatellite_0InternalBehavior/GetDTCOfEvent, operation=EvtInfo_AutoCreatedDemEvent_XFRM_E_MALFORMED_MESSAGE_2.GetDTCOfEvent
        OpEventGetDTCOfEvent_GetDTCOfEvent_EvtInfo_AutoCreatedDemEvent_EEP_E_WRITE_FAILED_1: start-on-event=DemSatellite_0InternalBehavior/GetDTCOfEvent, operation=EvtInfo_AutoCreatedDemEvent_EEP_E_WRITE_FAILED_1.GetDTCOfEvent
        OpEventGetDTCOfEvent_GetDTCOfEvent_EvtInfo_AutoCreatedDemEvent_EEP_E_READ_FAILED_1: start-on-event=DemSatellite_0InternalBehavior/GetDTCOfEvent, operation=EvtInfo_AutoCreatedDemEvent_EEP_E_READ_FAILED_1.GetDTCOfEvent
        OpEventGetDTCOfEvent_GetDTCOfEvent_EvtInfo_AutoCreatedDemEvent_EEP_E_ERASE_FAILED_1: start-on-event=DemSatellite_0InternalBehavior/GetDTCOfEvent, operation=EvtInfo_AutoCreatedDemEvent_EEP_E_ERASE_FAILED_1.GetDTCOfEvent
        OpEventGetDTCOfEvent_GetDTCOfEvent_EvtInfo_AutoCreatedDemEvent_EEP_E_COMPARE_FAILED_1: start-on-event=DemSatellite_0InternalBehavior/GetDTCOfEvent, operation=EvtInfo_AutoCreatedDemEvent_EEP_E_COMPARE_FAILED_1.GetDTCOfEvent
        OpEventGetDTCOfEvent_GetDTCOfEvent_EvtInfo_AutoCreatedDemEvent_FLS_E_WRITE_FAILED_1: start-on-event=DemSatellite_0InternalBehavior/GetDTCOfEvent, operation=EvtInfo_AutoCreatedDemEvent_FLS_E_WRITE_FAILED_1.GetDTCOfEvent
        OpEventGetDTCOfEvent_GetDTCOfEvent_EvtInfo_AutoCreatedDemEvent_FLS_E_UNEXPECTED_FLASH_ID_1: start-on-event=DemSatellite_0InternalBehavior/GetDTCOfEvent, operation=EvtInfo_AutoCreatedDemEvent_FLS_E_UNEXPECTED_FLASH_ID_1.GetDTCOfEvent
        OpEventGetDTCOfEvent_GetDTCOfEvent_EvtInfo_AutoCreatedDemEvent_FLS_E_READ_FAILED_1: start-on-event=DemSatellite_0InternalBehavior/GetDTCOfEvent, operation=EvtInfo_AutoCreatedDemEvent_FLS_E_READ_FAILED_1.GetDTCOfEvent
        OpEventGetDTCOfEvent_GetDTCOfEvent_EvtInfo_AutoCreatedDemEvent_FLS_E_ERASE_FAILED_1: start-on-event=DemSatellite_0InternalBehavior/GetDTCOfEvent, operation=EvtInfo_AutoCreatedDemEvent_FLS_E_ERASE_FAILED_1.GetDTCOfEvent
        OpEventGetDTCOfEvent_GetDTCOfEvent_EvtInfo_AutoCreatedDemEvent_FLS_E_COMPARE_FAILED_1: start-on-event=DemSatellite_0InternalBehavior/GetDTCOfEvent, operation=EvtInfo_AutoCreatedDemEvent_FLS_E_COMPARE_FAILED_1.GetDTCOfEvent
        OpEventGetDTCOfEvent_GetDTCOfEvent_EvtInfo_AutoCreatedDemEvent_MyECU_6c1a0d52_FrDemCtrlTestResultRef_1: start-on-event=DemSatellite_0InternalBehavior/GetDTCOfEvent, operation=EvtInfo_AutoCreatedDemEvent_MyECU_6c1a0d52_FrDemCtrlTestResultRef_1.GetDTCOfEvent
        OpEventGetDTCOfEvent_GetDTCOfEvent_EvtInfo_AutoCreatedDemEvent_McuModuleConfiguration_MCU_E_CLOCK_FAILURE_1: start-on-event=DemSatellite_0InternalBehavior/GetDTCOfEvent, operation=EvtInfo_AutoCreatedDemEvent_McuModuleConfiguration_MCU_E_CLOCK_FAILURE_1.GetDTCOfEvent
        OpEventGetDTCOfEvent_GetDTCOfEvent_EvtInfo_AutoCreatedDemEvent_XCP_E_INIT_FAILED: start-on-event=DemSatellite_0InternalBehavior/GetDTCOfEvent, operation=EvtInfo_AutoCreatedDemEvent_XCP_E_INIT_FAILED.GetDTCOfEvent
        OpEventGetFaultDetectionCounter_GetFaultDetectionCounter_EvtInfo_AutoCreatedDemEvent_BswMConfig_BswMReportFailToDemRef: start-on-event=DemSatellite_0InternalBehavior/GetFaultDetectionCounter, operation=EvtInfo_AutoCreatedDemEvent_BswMConfig_BswMReportFailToDemRef.GetFaultDetectionCounter
        OpEventGetFaultDetectionCounter_GetFaultDetectionCounter_EvtInfo_AutoCreatedDemEvent_CHNL_346f2748_CANSM_E_MODE_REQUEST_TIMEOUT: start-on-event=DemSatellite_0InternalBehavior/GetFaultDetectionCounter, operation=EvtInfo_AutoCreatedDemEvent_CHNL_346f2748_CANSM_E_MODE_REQUEST_TIMEOUT.GetFaultDetectionCounter
        OpEventGetFaultDetectionCounter_GetFaultDetectionCounter_EvtInfo_AutoCreatedDemEvent_CHNL_346f2748_CANSM_E_BUS_OFF: start-on-event=DemSatellite_0InternalBehavior/GetFaultDetectionCounter, operation=EvtInfo_AutoCreatedDemEvent_CHNL_346f2748_CANSM_E_BUS_OFF.GetFaultDetectionCounter
        OpEventGetFaultDetectionCounter_GetFaultDetectionCounter_EvtInfo_AutoCreatedDemEvent_XFRM_E_MALFORMED_MESSAGE: start-on-event=DemSatellite_0InternalBehavior/GetFaultDetectionCounter, operation=EvtInfo_AutoCreatedDemEvent_XFRM_E_MALFORMED_MESSAGE.GetFaultDetectionCounter
        OpEventGetFaultDetectionCounter_GetFaultDetectionCounter_EvtInfo_AutoCreatedDemEvent_XFRM_E_MALFORMED_MESSAGE_1: start-on-event=DemSatellite_0InternalBehavior/GetFaultDetectionCounter, operation=EvtInfo_AutoCreatedDemEvent_XFRM_E_MALFORMED_MESSAGE_1.GetFaultDetectionCounter
        OpEventGetFaultDetectionCounter_GetFaultDetectionCounter_EvtInfo_AutoCreatedDemEvent_ECUM_E_RAM_CHECK_FAILED: start-on-event=DemSatellite_0InternalBehavior/GetFaultDetectionCounter, operation=EvtInfo_AutoCreatedDemEvent_ECUM_E_RAM_CHECK_FAILED.GetFaultDetectionCounter
        OpEventGetFaultDetectionCounter_GetFaultDetectionCounter_EvtInfo_AutoCreatedDemEvent_ECUM_E_IMPROPER_CALLER: start-on-event=DemSatellite_0InternalBehavior/GetFaultDetectionCounter, operation=EvtInfo_AutoCreatedDemEvent_ECUM_E_IMPROPER_CALLER.GetFaultDetectionCounter
        OpEventGetFaultDetectionCounter_GetFaultDetectionCounter_EvtInfo_AutoCreatedDemEvent_ECUM_E_CONFIGURATION_DATA_INCONSISTENT: start-on-event=DemSatellite_0InternalBehavior/GetFaultDetectionCounter, operation=EvtInfo_AutoCreatedDemEvent_ECUM_E_CONFIGURATION_DATA_INCONSISTENT.GetFaultDetectionCounter
        OpEventGetFaultDetectionCounter_GetFaultDetectionCounter_EvtInfo_AutoCreatedDemEvent_ECUM_E_ALL_RUN_REQUESTS_KILLED: start-on-event=DemSatellite_0InternalBehavior/GetFaultDetectionCounter, operation=EvtInfo_AutoCreatedDemEvent_ECUM_E_ALL_RUN_REQUESTS_KILLED.GetFaultDetectionCounter
        OpEventGetFaultDetectionCounter_GetFaultDetectionCounter_EvtInfo_AutoCreatedDemEvent_EEP_E_WRITE_FAILED: start-on-event=DemSatellite_0InternalBehavior/GetFaultDetectionCounter, operation=EvtInfo_AutoCreatedDemEvent_EEP_E_WRITE_FAILED.GetFaultDetectionCounter
        OpEventGetFaultDetectionCounter_GetFaultDetectionCounter_EvtInfo_AutoCreatedDemEvent_EEP_E_READ_FAILED: start-on-event=DemSatellite_0InternalBehavior/GetFaultDetectionCounter, operation=EvtInfo_AutoCreatedDemEvent_EEP_E_READ_FAILED.GetFaultDetectionCounter
        OpEventGetFaultDetectionCounter_GetFaultDetectionCounter_EvtInfo_AutoCreatedDemEvent_EEP_E_ERASE_FAILED: start-on-event=DemSatellite_0InternalBehavior/GetFaultDetectionCounter, operation=EvtInfo_AutoCreatedDemEvent_EEP_E_ERASE_FAILED.GetFaultDetectionCounter
        OpEventGetFaultDetectionCounter_GetFaultDetectionCounter_EvtInfo_AutoCreatedDemEvent_EEP_E_COMPARE_FAILED: start-on-event=DemSatellite_0InternalBehavior/GetFaultDetectionCounter, operation=EvtInfo_AutoCreatedDemEvent_EEP_E_COMPARE_FAILED.GetFaultDetectionCounter
        OpEventGetFaultDetectionCounter_GetFaultDetectionCounter_EvtInfo_AutoCreatedDemEvent_FLS_E_WRITE_FAILED: start-on-event=DemSatellite_0InternalBehavior/GetFaultDetectionCounter, operation=EvtInfo_AutoCreatedDemEvent_FLS_E_WRITE_FAILED.GetFaultDetectionCounter
        OpEventGetFaultDetectionCounter_GetFaultDetectionCounter_EvtInfo_AutoCreatedDemEvent_FLS_E_UNEXPECTED_FLASH_ID: start-on-event=DemSatellite_0InternalBehavior/GetFaultDetectionCounter, operation=EvtInfo_AutoCreatedDemEvent_FLS_E_UNEXPECTED_FLASH_ID.GetFaultDetectionCounter
        OpEventGetFaultDetectionCounter_GetFaultDetectionCounter_EvtInfo_AutoCreatedDemEvent_FLS_E_READ_FAILED: start-on-event=DemSatellite_0InternalBehavior/GetFaultDetectionCounter, operation=EvtInfo_AutoCreatedDemEvent_FLS_E_READ_FAILED.GetFaultDetectionCounter
        OpEventGetFaultDetectionCounter_GetFaultDetectionCounter_EvtInfo_AutoCreatedDemEvent_FLS_E_ERASE_FAILED: start-on-event=DemSatellite_0InternalBehavior/GetFaultDetectionCounter, operation=EvtInfo_AutoCreatedDemEvent_FLS_E_ERASE_FAILED.GetFaultDetectionCounter
        OpEventGetFaultDetectionCounter_GetFaultDetectionCounter_EvtInfo_AutoCreatedDemEvent_FLS_E_COMPARE_FAILED: start-on-event=DemSatellite_0InternalBehavior/GetFaultDetectionCounter, operation=EvtInfo_AutoCreatedDemEvent_FLS_E_COMPARE_FAILED.GetFaultDetectionCounter
